VERSION ""

NS_ :

BS_:

BU_: UWB_RL UWB_FRNK UWB_RR UWB_INT DHR DHL UWB_BLE BDC UWB_FL Devtool ROA WPC UWB_TRNK UWB_FR

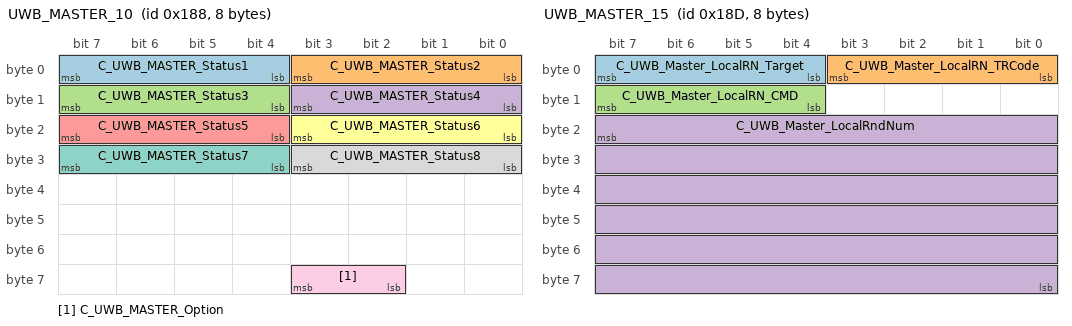
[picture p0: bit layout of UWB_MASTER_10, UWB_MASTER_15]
BO_ 392 UWB_MASTER_10: 8 UWB_BLE
 SG_ C_UWB_MASTER_Status1 : 7|4@0+ (1,0) [0|7] ""  BDC
 SG_ C_UWB_MASTER_Status2 : 3|4@0+ (1,0) [0|7] ""  BDC
 SG_ C_UWB_MASTER_Status3 : 15|4@0+ (1,0) [0|7] ""  BDC
 SG_ C_UWB_MASTER_Status4 : 11|4@0+ (1,0) [0|7] ""  BDC
 SG_ C_UWB_MASTER_Status5 : 23|4@0+ (1,0) [0|7] ""  BDC
 SG_ C_UWB_MASTER_Status6 : 19|4@0+ (1,0) [0|7] ""  BDC
 SG_ C_UWB_MASTER_Status7 : 31|4@0+ (1,0) [0|7] ""  BDC
 SG_ C_UWB_MASTER_Status8 : 27|4@0+ (1,0) [0|7] ""  BDC
 SG_ C_UWB_MASTER_Option : 59|2@0+ (1,0) [0|0] ""  BDC

BO_ 393 UWB_MASTER_11: 8 UWB_BLE
 SG_ C_UWB_Master_DK_ConnStat : 7|2@0+ (1,0) [0|0] ""  BDC
 SG_ C_UWB_Mst_DK_LocalizationStat : 5|2@0+ (1,0) [0|0] ""  BDC

BO_ 394 UWB_MASTER_12: 8 UWB_BLE
 SG_ C_UWB_Mst_EncryptedResult1Val : 7|64@0+ (1,0) [0|0] ""  BDC

BO_ 395 UWB_MASTER_13: 8 UWB_BLE
 SG_ C_UWB_Mst_EncryptedResult2Val : 7|64@0+ (1,0) [0|0] ""  BDC

BO_ 396 UWB_MASTER_14: 8 UWB_BLE
 SG_ C_UWB_Master2BDC_RndNum : 15|48@0+ (1,0) [0|0] ""  BDC

BO_ 397 UWB_MASTER_15: 8 UWB_BLE
 SG_ C_UWB_Master_LocalRN_Target : 7|4@0+ (1,0) [0|0] ""  UWB_FL,UWB_FR,UWB_FRNK,UWB_INT,UWB_RL,UWB_RR,UWB_TRNK
 SG_ C_UWB_Master_LocalRN_TRCode : 3|4@0+ (1,0) [0|0] ""  UWB_FL,UWB_FR,UWB_FRNK,UWB_INT,UWB_RL,UWB_RR,UWB_TRNK
 SG_ C_UWB_Master_LocalRN_CMD : 15|4@0+ (1,0) [0|0] ""  UWB_FL,UWB_FR,UWB_FRNK,UWB_INT,UWB_RL,UWB_RR,UWB_TRNK
 SG_ C_UWB_Master_LocalRndNum : 23|48@0+ (1,0) [0|0] ""  UWB_FL,UWB_FR,UWB_FRNK,UWB_INT,UWB_RL,UWB_RR,UWB_TRNK

BO_ 398 UWB_MASTER_16: 8 UWB_BLE
 SG_ UWB_Master_ToUWBEncryptData1 : 7|64@0+ (1,0) [0|0] ""  UWB_FL,UWB_FR,UWB_FRNK,UWB_INT,UWB_RL,UWB_RR,UWB_TRNK

BO_ 399 UWB_MASTER_17: 8 UWB_BLE
 SG_ UWB_Master_ToUWBEncryptData2 : 7|64@0+ (1,0) [0|0] ""  UWB_FL,UWB_FR,UWB_FRNK,UWB_INT,UWB_RL,UWB_RR,UWB_TRNK

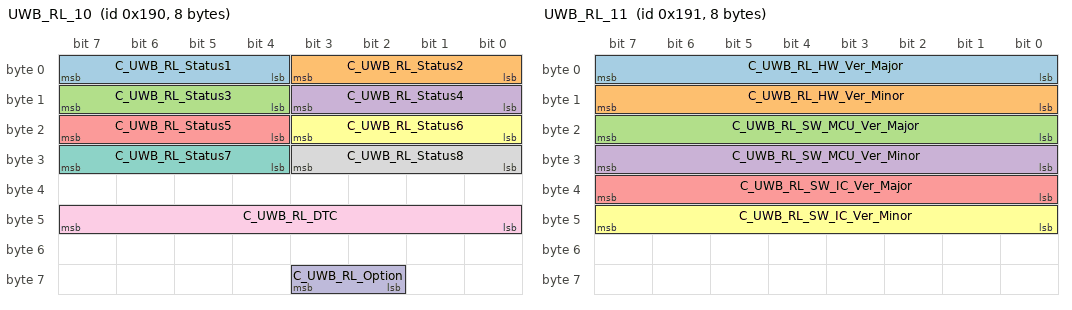
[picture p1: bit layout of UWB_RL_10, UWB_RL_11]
BO_ 400 UWB_RL_10: 8 UWB_RL
 SG_ C_UWB_RL_Status1 : 7|4@0+ (1,0) [0|7] ""  BDC,UWB_BLE
 SG_ C_UWB_RL_Status2 : 3|4@0+ (1,0) [0|7] ""  BDC,UWB_BLE
 SG_ C_UWB_RL_Status3 : 15|4@0+ (1,0) [0|7] ""  BDC,UWB_BLE
 SG_ C_UWB_RL_Status4 : 11|4@0+ (1,0) [0|7] ""  BDC,UWB_BLE
 SG_ C_UWB_RL_Status5 : 23|4@0+ (1,0) [0|7] ""  BDC,UWB_BLE
 SG_ C_UWB_RL_Status6 : 19|4@0+ (1,0) [0|7] ""  BDC,UWB_BLE
 SG_ C_UWB_RL_Status7 : 31|4@0+ (1,0) [0|7] ""  BDC,UWB_BLE
 SG_ C_UWB_RL_Status8 : 27|4@0+ (1,0) [0|7] ""  BDC,UWB_BLE
 SG_ C_UWB_RL_DTC : 47|8@0+ (1,0) [0|0] ""  UWB_BLE
 SG_ C_UWB_RL_Option : 59|2@0+ (1,0) [0|0] ""  BDC,UWB_BLE

BO_ 401 UWB_RL_11: 8 UWB_RL
 SG_ C_UWB_RL_HW_Ver_Major : 7|8@0+ (1,0) [0|7] ""  UWB_BLE
 SG_ C_UWB_RL_HW_Ver_Minor : 15|8@0+ (1,0) [0|7] ""  UWB_BLE
 SG_ C_UWB_RL_SW_MCU_Ver_Major : 23|8@0+ (1,0) [0|7] ""  UWB_BLE
 SG_ C_UWB_RL_SW_MCU_Ver_Minor : 31|8@0+ (1,0) [0|7] ""  UWB_BLE
 SG_ C_UWB_RL_SW_IC_Ver_Major : 39|8@0+ (1,0) [0|7] ""  UWB_BLE
 SG_ C_UWB_RL_SW_IC_Ver_Minor : 47|8@0+ (1,0) [0|7] ""  UWB_BLE

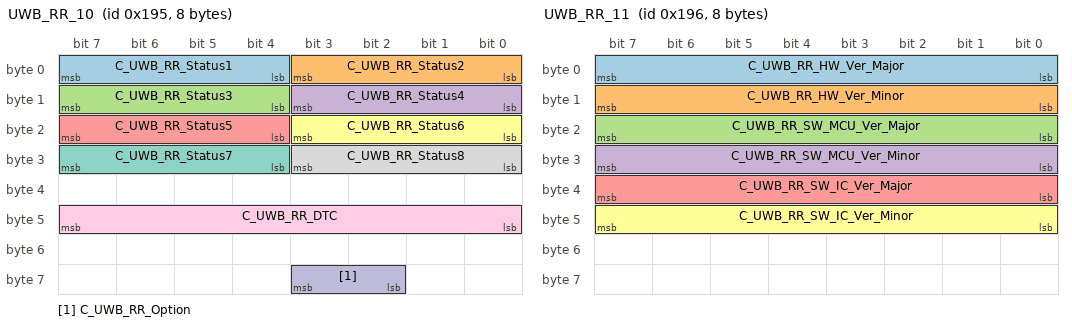
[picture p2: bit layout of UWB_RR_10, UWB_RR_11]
BO_ 405 UWB_RR_10: 8 UWB_RR
 SG_ C_UWB_RR_Status1 : 7|4@0+ (1,0) [0|7] ""  BDC,UWB_BLE
 SG_ C_UWB_RR_Status2 : 3|4@0+ (1,0) [0|7] ""  BDC,UWB_BLE
 SG_ C_UWB_RR_Status3 : 15|4@0+ (1,0) [0|7] ""  BDC,UWB_BLE
 SG_ C_UWB_RR_Status4 : 11|4@0+ (1,0) [0|7] ""  BDC,UWB_BLE
 SG_ C_UWB_RR_Status5 : 23|4@0+ (1,0) [0|7] ""  BDC,UWB_BLE
 SG_ C_UWB_RR_Status6 : 19|4@0+ (1,0) [0|7] ""  BDC,UWB_BLE
 SG_ C_UWB_RR_Status7 : 31|4@0+ (1,0) [0|7] ""  BDC,UWB_BLE
 SG_ C_UWB_RR_Status8 : 27|4@0+ (1,0) [0|7] ""  BDC,UWB_BLE
 SG_ C_UWB_RR_DTC : 47|8@0+ (1,0) [0|0] ""  UWB_BLE
 SG_ C_UWB_RR_Option : 59|2@0+ (1,0) [0|0] ""  BDC,UWB_BLE

BO_ 406 UWB_RR_11: 8 UWB_RR
 SG_ C_UWB_RR_HW_Ver_Major : 7|8@0+ (1,0) [0|7] ""  UWB_BLE
 SG_ C_UWB_RR_HW_Ver_Minor : 15|8@0+ (1,0) [0|7] ""  UWB_BLE
 SG_ C_UWB_RR_SW_MCU_Ver_Major : 23|8@0+ (1,0) [0|7] ""  UWB_BLE
 SG_ C_UWB_RR_SW_MCU_Ver_Minor : 31|8@0+ (1,0) [0|7] ""  UWB_BLE
 SG_ C_UWB_RR_SW_IC_Ver_Major : 39|8@0+ (1,0) [0|7] ""  UWB_BLE
 SG_ C_UWB_RR_SW_IC_Ver_Minor : 47|8@0+ (1,0) [0|7] ""  UWB_BLE

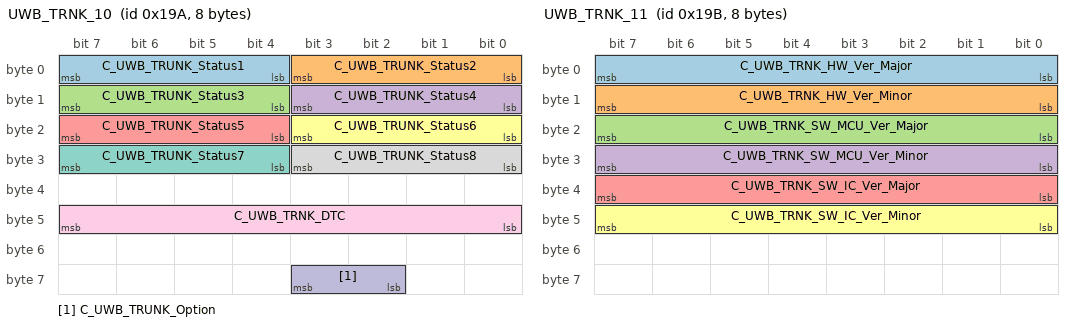
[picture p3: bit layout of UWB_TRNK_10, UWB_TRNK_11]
BO_ 410 UWB_TRNK_10: 8 UWB_TRNK
 SG_ C_UWB_TRUNK_Status1 : 7|4@0+ (1,0) [0|7] ""  BDC,UWB_BLE
 SG_ C_UWB_TRUNK_Status2 : 3|4@0+ (1,0) [0|7] ""  BDC,UWB_BLE
 SG_ C_UWB_TRUNK_Status3 : 15|4@0+ (1,0) [0|7] ""  BDC,UWB_BLE
 SG_ C_UWB_TRUNK_Status4 : 11|4@0+ (1,0) [0|7] ""  BDC,UWB_BLE
 SG_ C_UWB_TRUNK_Status5 : 23|4@0+ (1,0) [0|7] ""  BDC,UWB_BLE
 SG_ C_UWB_TRUNK_Status6 : 19|4@0+ (1,0) [0|7] ""  BDC,UWB_BLE
 SG_ C_UWB_TRUNK_Status7 : 31|4@0+ (1,0) [0|7] ""  BDC,UWB_BLE
 SG_ C_UWB_TRUNK_Status8 : 27|4@0+ (1,0) [0|7] ""  BDC,UWB_BLE
 SG_ C_UWB_TRNK_DTC : 47|8@0+ (1,0) [0|0] ""  UWB_BLE
 SG_ C_UWB_TRUNK_Option : 59|2@0+ (1,0) [0|3] ""  BDC,UWB_BLE

BO_ 411 UWB_TRNK_11: 8 UWB_TRNK
 SG_ C_UWB_TRNK_HW_Ver_Major : 7|8@0+ (1,0) [0|7] ""  UWB_BLE
 SG_ C_UWB_TRNK_HW_Ver_Minor : 15|8@0+ (1,0) [0|7] ""  UWB_BLE
 SG_ C_UWB_TRNK_SW_MCU_Ver_Major : 23|8@0+ (1,0) [0|7] ""  UWB_BLE
 SG_ C_UWB_TRNK_SW_MCU_Ver_Minor : 31|8@0+ (1,0) [0|7] ""  UWB_BLE
 SG_ C_UWB_TRNK_SW_IC_Ver_Major : 39|8@0+ (1,0) [0|7] ""  UWB_BLE
 SG_ C_UWB_TRNK_SW_IC_Ver_Minor : 47|8@0+ (1,0) [0|7] ""  UWB_BLE

BO_ 418 UWB_INT_02: 8 UWB_INT
 SG_ C_UWB_INT_To_MasterEncData1 : 7|64@0+ (1,0) [0|0] ""  UWB_BLE

BO_ 450 UWB_RL_02: 8 UWB_RL
 SG_ C_UWB_RL_To_MasterEncData1 : 7|64@0+ (1,0) [0|0] ""  UWB_BLE

BO_ 451 UWB_RL_03: 8 UWB_RL
 SG_ C_UWB_RL_To_MasterEncData2 : 7|64@0+ (1,0) [0|0] ""  UWB_BLE

BO_ 452 UWB_RL_04: 8 UWB_RL
 SG_ C_UWB_RL_To_BDCFOBRSDResult : 7|64@0+ (1,0) [0|0] ""  BDC

BO_ 453 UWB_RL_05: 8 UWB_RL
 SG_ C_UWB_RL_MCU_Bootloader : 7|8@0+ (1,0) [0|0] ""  UWB_BLE
 SG_ C_UWB_RL_MCU_Flash_Erase : 15|8@0+ (1,0) [0|0] ""  UWB_BLE
 SG_ C_UWB_RL_MCU_CRC32 : 23|8@0+ (1,0) [0|0] ""  UWB_BLE

BO_ 454 UWB_RL_06: 8 UWB_RL
 SG_ C_UWB_RL_IC_Bootloader : 7|8@0+ (1,0) [0|0] ""  UWB_BLE
 SG_ C_UWB_RL_IC_Flash_Erase : 15|8@0+ (1,0) [0|0] ""  UWB_BLE
 SG_ C_UWB_RL_IC_CRC32 : 23|8@0+ (1,0) [0|0] ""  UWB_BLE

BO_ 455 UWB_RL_01: 8 UWB_RL
 SG_ C_UWB_RL_Decrypt_FB : 63|4@0+ (1,0) [0|0] ""  BDC,UWB_BLE

BO_ 482 UWB_RR_02: 8 UWB_RR
 SG_ C_UWB_RR_To_MasterEncData1 : 7|64@0+ (1,0) [0|0] ""  UWB_BLE

BO_ 483 UWB_RR_03: 8 UWB_RR
 SG_ C_UWB_RR_To_MasterEncData2 : 7|64@0+ (1,0) [0|0] ""  UWB_BLE

BO_ 484 UWB_RR_04: 8 UWB_RR
 SG_ C_UWB_RR_To_BDCFOBRSDResult : 7|64@0+ (1,0) [0|0] ""  BDC

BO_ 485 UWB_RR_05: 8 UWB_RR
 SG_ C_UWB_RR_MCU_Bootloader : 7|8@0+ (1,0) [0|0] ""  UWB_BLE
 SG_ C_UWB_RR_MCU_Flash_Erase : 15|8@0+ (1,0) [0|0] ""  UWB_BLE
 SG_ C_UWB_RR_MCU_CRC32 : 23|8@0+ (1,0) [0|0] ""  UWB_BLE

BO_ 486 UWB_RR_06: 8 UWB_RR
 SG_ C_UWB_RR_IC_Bootloader : 7|8@0+ (1,0) [0|0] ""  UWB_BLE
 SG_ C_UWB_RR_IC_Flash_Erase : 15|8@0+ (1,0) [0|0] ""  UWB_BLE
 SG_ C_UWB_RR_IC_CRC32 : 23|8@0+ (1,0) [0|0] ""  UWB_BLE

BO_ 487 UWB_RR_01: 8 UWB_RR
 SG_ C_UWB_RR_Decrypt_FB : 63|4@0+ (1,0) [0|0] ""  BDC,UWB_BLE

BO_ 498 UWB_TRNK_02: 8 UWB_TRNK
 SG_ C_UWB_TRNK_To_MasterEncData1 : 7|64@0+ (1,0) [0|0] ""  UWB_BLE

BO_ 499 UWB_TRNK_03: 8 UWB_TRNK
 SG_ C_UWB_TRNK_To_MasterEncData2 : 7|64@0+ (1,0) [0|0] ""  UWB_BLE

BO_ 500 UWB_TRNK_04: 8 UWB_TRNK
 SG_ C_UWB_TRNK_To_BDCFOBRSDResult : 7|64@0+ (1,0) [0|0] ""  BDC

BO_ 501 UWB_TRNK_05: 8 UWB_TRNK
 SG_ C_UWB_TRNK_MCU_Bootloader : 7|8@0+ (1,0) [0|0] ""  UWB_BLE
 SG_ C_UWB_TRNK_MCU_Flash_Erase : 15|8@0+ (1,0) [0|0] ""  UWB_BLE
 SG_ C_UWB_TRNK_MCU_CRC32 : 23|8@0+ (1,0) [0|0] ""  UWB_BLE

BO_ 502 UWB_TRNK_06: 8 UWB_TRNK
 SG_ C_UWB_TRNK_IC_Bootloader : 7|8@0+ (1,0) [0|0] ""  UWB_BLE
 SG_ C_UWB_TRNK_IC_Flash_Erase : 15|8@0+ (1,0) [0|0] ""  UWB_BLE
 SG_ C_UWB_TRNK_IC_CRC32 : 23|8@0+ (1,0) [0|0] ""  UWB_BLE

BO_ 503 UWB_TRNK_01: 8 UWB_TRNK
 SG_ C_UWB_TRNK_Decrypt_FB : 63|4@0+ (1,0) [0|0] ""  BDC,UWB_BLE

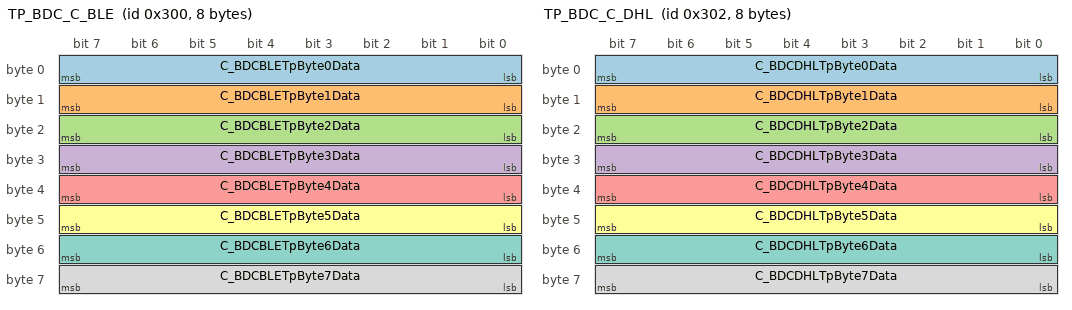
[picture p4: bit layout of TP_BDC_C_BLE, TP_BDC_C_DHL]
BO_ 768 TP_BDC_C_BLE: 8 BDC
 SG_ C_BDCBLETpByte0Data : 7|8@0+ (1,0) [0|0] ""  UWB_BLE
 SG_ C_BDCBLETpByte1Data : 15|8@0+ (1,0) [0|0] ""  UWB_BLE
 SG_ C_BDCBLETpByte2Data : 23|8@0+ (1,0) [0|0] ""  UWB_BLE
 SG_ C_BDCBLETpByte3Data : 31|8@0+ (1,0) [0|0] ""  UWB_BLE
 SG_ C_BDCBLETpByte4Data : 39|8@0+ (1,0) [0|0] ""  UWB_BLE
 SG_ C_BDCBLETpByte5Data : 47|8@0+ (1,0) [0|0] ""  UWB_BLE
 SG_ C_BDCBLETpByte6Data : 55|8@0+ (1,0) [0|0] ""  UWB_BLE
 SG_ C_BDCBLETpByte7Data : 63|8@0+ (1,0) [0|0] ""  UWB_BLE

BO_ 770 TP_BDC_C_DHL: 8 BDC
 SG_ C_BDCDHLTpByte0Data : 7|8@0+ (1,0) [0|0] ""  DHL
 SG_ C_BDCDHLTpByte1Data : 15|8@0+ (1,0) [0|0] ""  DHL
 SG_ C_BDCDHLTpByte2Data : 23|8@0+ (1,0) [0|0] ""  DHL
 SG_ C_BDCDHLTpByte3Data : 31|8@0+ (1,0) [0|0] ""  DHL
 SG_ C_BDCDHLTpByte4Data : 39|8@0+ (1,0) [0|0] ""  DHL
 SG_ C_BDCDHLTpByte5Data : 47|8@0+ (1,0) [0|0] ""  DHL
 SG_ C_BDCDHLTpByte6Data : 55|8@0+ (1,0) [0|0] ""  DHL
 SG_ C_BDCDHLTpByte7Data : 63|8@0+ (1,0) [0|0] ""  DHL

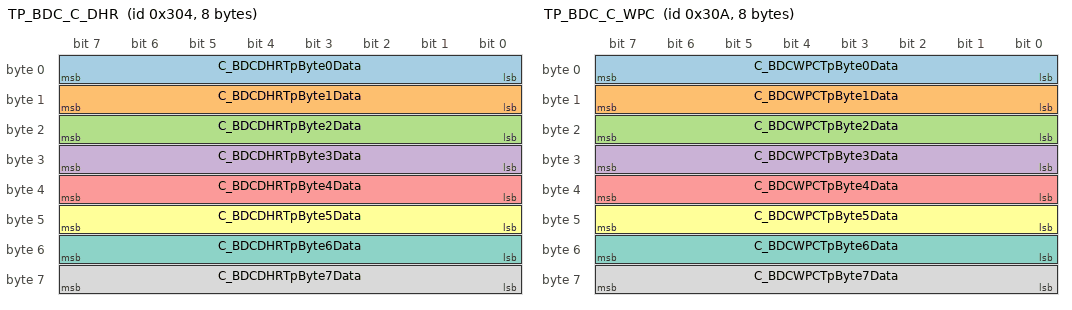
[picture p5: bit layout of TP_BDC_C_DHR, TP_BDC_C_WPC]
BO_ 772 TP_BDC_C_DHR: 8 BDC
 SG_ C_BDCDHRTpByte0Data : 7|8@0+ (1,0) [0|0] ""  DHR
 SG_ C_BDCDHRTpByte1Data : 15|8@0+ (1,0) [0|0] ""  DHR
 SG_ C_BDCDHRTpByte2Data : 23|8@0+ (1,0) [0|0] ""  DHR
 SG_ C_BDCDHRTpByte3Data : 31|8@0+ (1,0) [0|0] ""  DHR
 SG_ C_BDCDHRTpByte4Data : 39|8@0+ (1,0) [0|0] ""  DHR
 SG_ C_BDCDHRTpByte5Data : 47|8@0+ (1,0) [0|0] ""  DHR
 SG_ C_BDCDHRTpByte6Data : 55|8@0+ (1,0) [0|0] ""  DHR
 SG_ C_BDCDHRTpByte7Data : 63|8@0+ (1,0) [0|0] ""  DHR

BO_ 778 TP_BDC_C_WPC: 8 BDC
 SG_ C_BDCWPCTpByte0Data : 7|8@0+ (1,0) [0|0] ""  WPC
 SG_ C_BDCWPCTpByte1Data : 15|8@0+ (1,0) [0|0] ""  WPC
 SG_ C_BDCWPCTpByte2Data : 23|8@0+ (1,0) [0|0] ""  WPC
 SG_ C_BDCWPCTpByte3Data : 31|8@0+ (1,0) [0|0] ""  WPC
 SG_ C_BDCWPCTpByte4Data : 39|8@0+ (1,0) [0|0] ""  WPC
 SG_ C_BDCWPCTpByte5Data : 47|8@0+ (1,0) [0|0] ""  WPC
 SG_ C_BDCWPCTpByte6Data : 55|8@0+ (1,0) [0|0] ""  WPC
 SG_ C_BDCWPCTpByte7Data : 63|8@0+ (1,0) [0|0] ""  WPC

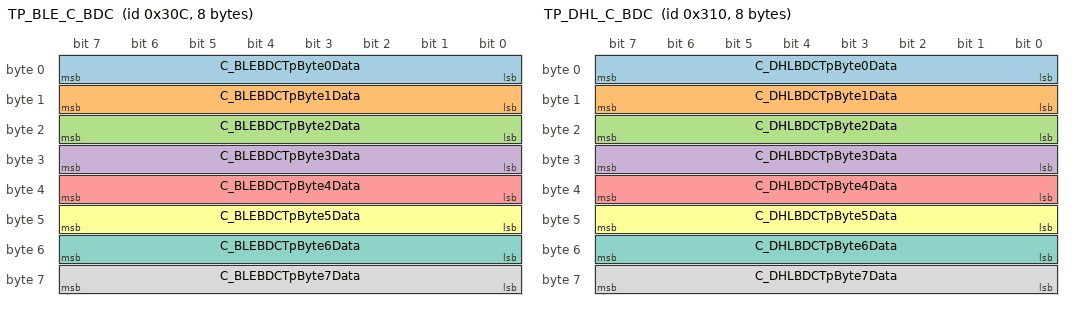
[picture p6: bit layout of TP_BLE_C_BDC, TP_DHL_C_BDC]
BO_ 780 TP_BLE_C_BDC: 8 UWB_BLE
 SG_ C_BLEBDCTpByte0Data : 7|8@0+ (1,0) [0|0] ""  BDC
 SG_ C_BLEBDCTpByte1Data : 15|8@0+ (1,0) [0|0] ""  BDC
 SG_ C_BLEBDCTpByte2Data : 23|8@0+ (1,0) [0|0] ""  BDC
 SG_ C_BLEBDCTpByte3Data : 31|8@0+ (1,0) [0|0] ""  BDC
 SG_ C_BLEBDCTpByte4Data : 39|8@0+ (1,0) [0|0] ""  BDC
 SG_ C_BLEBDCTpByte5Data : 47|8@0+ (1,0) [0|0] ""  BDC
 SG_ C_BLEBDCTpByte6Data : 55|8@0+ (1,0) [0|0] ""  BDC
 SG_ C_BLEBDCTpByte7Data : 63|8@0+ (1,0) [0|0] ""  BDC

BO_ 784 TP_DHL_C_BDC: 8 DHL
 SG_ C_DHLBDCTpByte0Data : 7|8@0+ (1,0) [0|0] ""  BDC
 SG_ C_DHLBDCTpByte1Data : 15|8@0+ (1,0) [0|0] ""  BDC
 SG_ C_DHLBDCTpByte2Data : 23|8@0+ (1,0) [0|0] ""  BDC
 SG_ C_DHLBDCTpByte3Data : 31|8@0+ (1,0) [0|0] ""  BDC
 SG_ C_DHLBDCTpByte4Data : 39|8@0+ (1,0) [0|0] ""  BDC
 SG_ C_DHLBDCTpByte5Data : 47|8@0+ (1,0) [0|0] ""  BDC
 SG_ C_DHLBDCTpByte6Data : 55|8@0+ (1,0) [0|0] ""  BDC
 SG_ C_DHLBDCTpByte7Data : 63|8@0+ (1,0) [0|0] ""  BDC

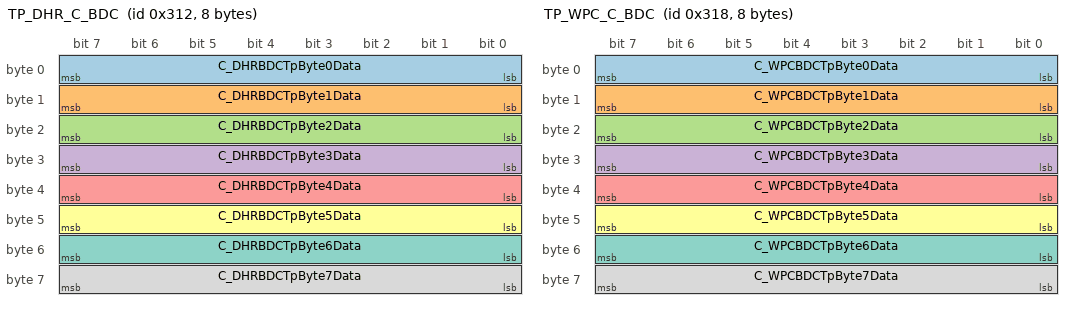
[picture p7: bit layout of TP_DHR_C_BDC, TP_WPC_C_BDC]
BO_ 786 TP_DHR_C_BDC: 8 DHR
 SG_ C_DHRBDCTpByte0Data : 7|8@0+ (1,0) [0|0] ""  BDC
 SG_ C_DHRBDCTpByte1Data : 15|8@0+ (1,0) [0|0] ""  BDC
 SG_ C_DHRBDCTpByte2Data : 23|8@0+ (1,0) [0|0] ""  BDC
 SG_ C_DHRBDCTpByte3Data : 31|8@0+ (1,0) [0|0] ""  BDC
 SG_ C_DHRBDCTpByte4Data : 39|8@0+ (1,0) [0|0] ""  BDC
 SG_ C_DHRBDCTpByte5Data : 47|8@0+ (1,0) [0|0] ""  BDC
 SG_ C_DHRBDCTpByte6Data : 55|8@0+ (1,0) [0|0] ""  BDC
 SG_ C_DHRBDCTpByte7Data : 63|8@0+ (1,0) [0|0] ""  BDC

BO_ 792 TP_WPC_C_BDC: 8 WPC
 SG_ C_WPCBDCTpByte0Data : 7|8@0+ (1,0) [0|0] ""  BDC,Devtool
 SG_ C_WPCBDCTpByte1Data : 15|8@0+ (1,0) [0|0] ""  BDC,Devtool
 SG_ C_WPCBDCTpByte2Data : 23|8@0+ (1,0) [0|0] ""  BDC,Devtool
 SG_ C_WPCBDCTpByte3Data : 31|8@0+ (1,0) [0|0] ""  BDC,Devtool
 SG_ C_WPCBDCTpByte4Data : 39|8@0+ (1,0) [0|0] ""  BDC,Devtool
 SG_ C_WPCBDCTpByte5Data : 47|8@0+ (1,0) [0|0] ""  BDC,Devtool
 SG_ C_WPCBDCTpByte6Data : 55|8@0+ (1,0) [0|0] ""  BDC,Devtool
 SG_ C_WPCBDCTpByte7Data : 63|8@0+ (1,0) [0|0] ""  BDC,Devtool

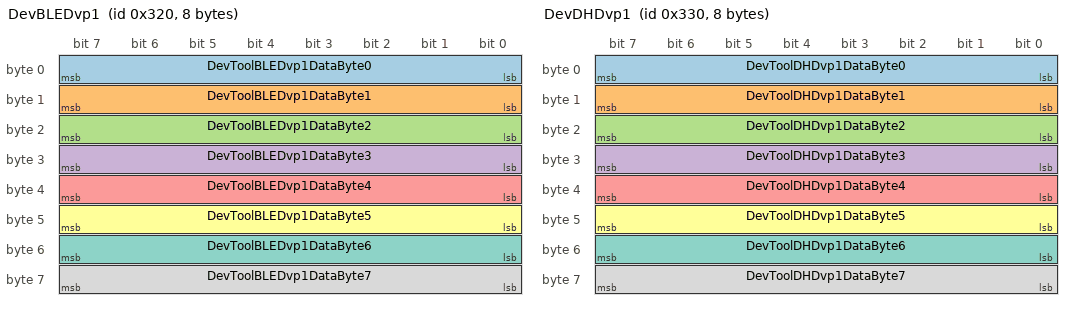
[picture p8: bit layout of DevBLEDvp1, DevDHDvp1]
BO_ 800 DevBLEDvp1: 8 Devtool
 SG_ DevToolBLEDvp1DataByte0 : 7|8@0+ (1,0) [0|0] ""  UWB_BLE
 SG_ DevToolBLEDvp1DataByte1 : 15|8@0+ (1,0) [0|0] ""  UWB_BLE
 SG_ DevToolBLEDvp1DataByte2 : 23|8@0+ (1,0) [0|0] ""  UWB_BLE
 SG_ DevToolBLEDvp1DataByte3 : 31|8@0+ (1,0) [0|0] ""  UWB_BLE
 SG_ DevToolBLEDvp1DataByte4 : 39|8@0+ (1,0) [0|0] ""  UWB_BLE
 SG_ DevToolBLEDvp1DataByte5 : 47|8@0+ (1,0) [0|0] ""  UWB_BLE
 SG_ DevToolBLEDvp1DataByte6 : 55|8@0+ (1,0) [0|0] ""  UWB_BLE
 SG_ DevToolBLEDvp1DataByte7 : 63|8@0+ (1,0) [0|0] ""  UWB_BLE

BO_ 816 DevDHDvp1: 8 Devtool
 SG_ DevToolDHDvp1DataByte0 : 7|8@0+ (1,0) [0|0] ""  DHL,DHR
 SG_ DevToolDHDvp1DataByte1 : 15|8@0+ (1,0) [0|0] ""  DHL,DHR
 SG_ DevToolDHDvp1DataByte2 : 23|8@0+ (1,0) [0|0] ""  DHL,DHR
 SG_ DevToolDHDvp1DataByte3 : 31|8@0+ (1,0) [0|0] ""  DHL,DHR
 SG_ DevToolDHDvp1DataByte4 : 39|8@0+ (1,0) [0|0] ""  DHL,DHR
 SG_ DevToolDHDvp1DataByte5 : 47|8@0+ (1,0) [0|0] ""  DHL,DHR
 SG_ DevToolDHDvp1DataByte6 : 55|8@0+ (1,0) [0|0] ""  DHL,DHR
 SG_ DevToolDHDvp1DataByte7 : 63|8@0+ (1,0) [0|0] ""  DHL,DHR

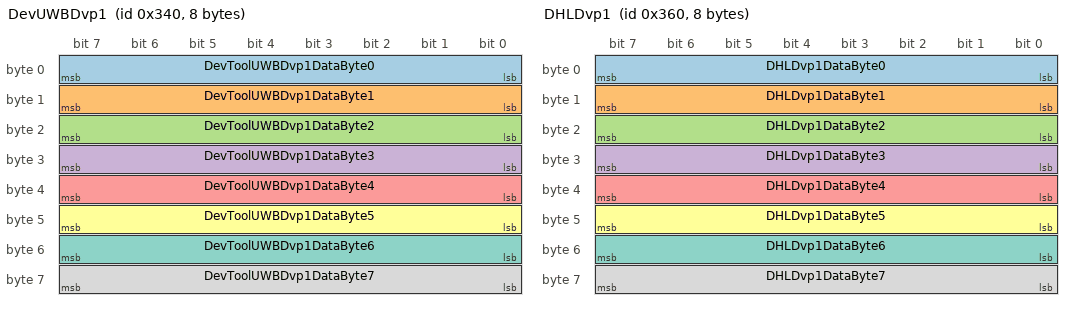
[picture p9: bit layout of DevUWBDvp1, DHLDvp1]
BO_ 832 DevUWBDvp1: 8 Devtool
 SG_ DevToolUWBDvp1DataByte0 : 7|8@0+ (1,0) [0|0] ""  UWB_BLE,UWB_FL,UWB_FR,UWB_FRNK,UWB_INT,UWB_RL,UWB_RR,UWB_TRNK
 SG_ DevToolUWBDvp1DataByte1 : 15|8@0+ (1,0) [0|0] ""  UWB_BLE,UWB_FL,UWB_FR,UWB_FRNK,UWB_INT,UWB_RL,UWB_RR,UWB_TRNK
 SG_ DevToolUWBDvp1DataByte2 : 23|8@0+ (1,0) [0|0] ""  UWB_BLE,UWB_FL,UWB_FR,UWB_FRNK,UWB_INT,UWB_RL,UWB_RR,UWB_TRNK
 SG_ DevToolUWBDvp1DataByte3 : 31|8@0+ (1,0) [0|0] ""  UWB_BLE,UWB_FL,UWB_FR,UWB_FRNK,UWB_INT,UWB_RL,UWB_RR,UWB_TRNK
 SG_ DevToolUWBDvp1DataByte4 : 39|8@0+ (1,0) [0|0] ""  UWB_BLE,UWB_FL,UWB_FR,UWB_FRNK,UWB_INT,UWB_RL,UWB_RR,UWB_TRNK
 SG_ DevToolUWBDvp1DataByte5 : 47|8@0+ (1,0) [0|0] ""  UWB_BLE,UWB_FL,UWB_FR,UWB_FRNK,UWB_INT,UWB_RL,UWB_RR,UWB_TRNK
 SG_ DevToolUWBDvp1DataByte6 : 55|8@0+ (1,0) [0|0] ""  UWB_BLE,UWB_FL,UWB_FR,UWB_FRNK,UWB_INT,UWB_RL,UWB_RR,UWB_TRNK
 SG_ DevToolUWBDvp1DataByte7 : 63|8@0+ (1,0) [0|0] ""  UWB_BLE,UWB_FL,UWB_FR,UWB_FRNK,UWB_INT,UWB_RL,UWB_RR,UWB_TRNK

BO_ 864 DHLDvp1: 8 DHL
 SG_ DHLDvp1DataByte0 : 7|8@0+ (1,0) [0|0] ""  Devtool
 SG_ DHLDvp1DataByte1 : 15|8@0+ (1,0) [0|0] ""  Devtool
 SG_ DHLDvp1DataByte2 : 23|8@0+ (1,0) [0|0] ""  Devtool
 SG_ DHLDvp1DataByte3 : 31|8@0+ (1,0) [0|0] ""  Devtool
 SG_ DHLDvp1DataByte4 : 39|8@0+ (1,0) [0|0] ""  Devtool
 SG_ DHLDvp1DataByte5 : 47|8@0+ (1,0) [0|0] ""  Devtool
 SG_ DHLDvp1DataByte6 : 55|8@0+ (1,0) [0|0] ""  Devtool
 SG_ DHLDvp1DataByte7 : 63|8@0+ (1,0) [0|0] ""  Devtool

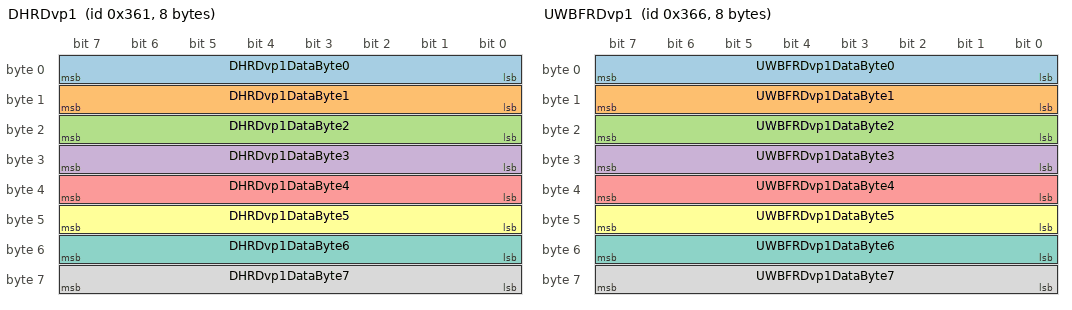
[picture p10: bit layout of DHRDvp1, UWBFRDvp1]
BO_ 865 DHRDvp1: 8 DHR
 SG_ DHRDvp1DataByte0 : 7|8@0+ (1,0) [0|0] ""  Devtool
 SG_ DHRDvp1DataByte1 : 15|8@0+ (1,0) [0|0] ""  Devtool
 SG_ DHRDvp1DataByte2 : 23|8@0+ (1,0) [0|0] ""  Devtool
 SG_ DHRDvp1DataByte3 : 31|8@0+ (1,0) [0|0] ""  Devtool
 SG_ DHRDvp1DataByte4 : 39|8@0+ (1,0) [0|0] ""  Devtool
 SG_ DHRDvp1DataByte5 : 47|8@0+ (1,0) [0|0] ""  Devtool
 SG_ DHRDvp1DataByte6 : 55|8@0+ (1,0) [0|0] ""  Devtool
 SG_ DHRDvp1DataByte7 : 63|8@0+ (1,0) [0|0] ""  Devtool

BO_ 870 UWBFRDvp1: 8 UWB_FR
 SG_ UWBFRDvp1DataByte0 : 7|8@0+ (1,0) [0|0] ""  Devtool
 SG_ UWBFRDvp1DataByte1 : 15|8@0+ (1,0) [0|0] ""  Devtool
 SG_ UWBFRDvp1DataByte2 : 23|8@0+ (1,0) [0|0] ""  Devtool
 SG_ UWBFRDvp1DataByte3 : 31|8@0+ (1,0) [0|0] ""  Devtool
 SG_ UWBFRDvp1DataByte4 : 39|8@0+ (1,0) [0|0] ""  Devtool
 SG_ UWBFRDvp1DataByte5 : 47|8@0+ (1,0) [0|0] ""  Devtool
 SG_ UWBFRDvp1DataByte6 : 55|8@0+ (1,0) [0|0] ""  Devtool
 SG_ UWBFRDvp1DataByte7 : 63|8@0+ (1,0) [0|0] ""  Devtool

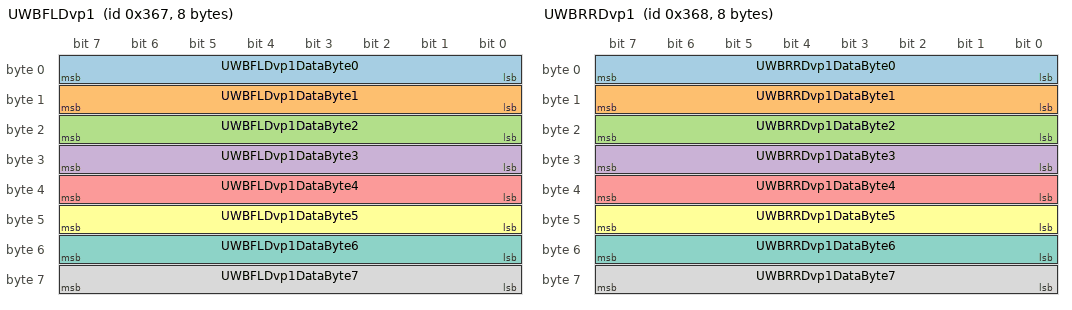
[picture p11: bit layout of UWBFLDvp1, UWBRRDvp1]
BO_ 871 UWBFLDvp1: 8 UWB_FL
 SG_ UWBFLDvp1DataByte0 : 7|8@0+ (1,0) [0|0] ""  Devtool
 SG_ UWBFLDvp1DataByte1 : 15|8@0+ (1,0) [0|0] ""  Devtool
 SG_ UWBFLDvp1DataByte2 : 23|8@0+ (1,0) [0|0] ""  Devtool
 SG_ UWBFLDvp1DataByte3 : 31|8@0+ (1,0) [0|0] ""  Devtool
 SG_ UWBFLDvp1DataByte4 : 39|8@0+ (1,0) [0|0] ""  Devtool
 SG_ UWBFLDvp1DataByte5 : 47|8@0+ (1,0) [0|0] ""  Devtool
 SG_ UWBFLDvp1DataByte6 : 55|8@0+ (1,0) [0|0] ""  Devtool
 SG_ UWBFLDvp1DataByte7 : 63|8@0+ (1,0) [0|0] ""  Devtool

BO_ 872 UWBRRDvp1: 8 UWB_RR
 SG_ UWBRRDvp1DataByte0 : 7|8@0+ (1,0) [0|0] ""  Devtool
 SG_ UWBRRDvp1DataByte1 : 15|8@0+ (1,0) [0|0] ""  Devtool
 SG_ UWBRRDvp1DataByte2 : 23|8@0+ (1,0) [0|0] ""  Devtool
 SG_ UWBRRDvp1DataByte3 : 31|8@0+ (1,0) [0|0] ""  Devtool
 SG_ UWBRRDvp1DataByte4 : 39|8@0+ (1,0) [0|0] ""  Devtool
 SG_ UWBRRDvp1DataByte5 : 47|8@0+ (1,0) [0|0] ""  Devtool
 SG_ UWBRRDvp1DataByte6 : 55|8@0+ (1,0) [0|0] ""  Devtool
 SG_ UWBRRDvp1DataByte7 : 63|8@0+ (1,0) [0|0] ""  Devtool

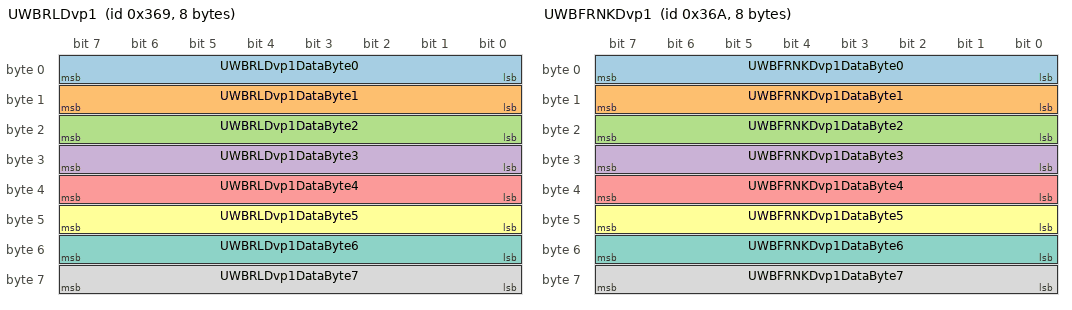
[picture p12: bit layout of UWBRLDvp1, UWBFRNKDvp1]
BO_ 873 UWBRLDvp1: 8 UWB_RL
 SG_ UWBRLDvp1DataByte0 : 7|8@0+ (1,0) [0|0] ""  Devtool
 SG_ UWBRLDvp1DataByte1 : 15|8@0+ (1,0) [0|0] ""  Devtool
 SG_ UWBRLDvp1DataByte2 : 23|8@0+ (1,0) [0|0] ""  Devtool
 SG_ UWBRLDvp1DataByte3 : 31|8@0+ (1,0) [0|0] ""  Devtool
 SG_ UWBRLDvp1DataByte4 : 39|8@0+ (1,0) [0|0] ""  Devtool
 SG_ UWBRLDvp1DataByte5 : 47|8@0+ (1,0) [0|0] ""  Devtool
 SG_ UWBRLDvp1DataByte6 : 55|8@0+ (1,0) [0|0] ""  Devtool
 SG_ UWBRLDvp1DataByte7 : 63|8@0+ (1,0) [0|0] ""  Devtool

BO_ 874 UWBFRNKDvp1: 8 UWB_FRNK
 SG_ UWBFRNKDvp1DataByte0 : 7|8@0+ (1,0) [0|0] ""  Devtool
 SG_ UWBFRNKDvp1DataByte1 : 15|8@0+ (1,0) [0|0] ""  Devtool
 SG_ UWBFRNKDvp1DataByte2 : 23|8@0+ (1,0) [0|0] ""  Devtool
 SG_ UWBFRNKDvp1DataByte3 : 31|8@0+ (1,0) [0|0] ""  Devtool
 SG_ UWBFRNKDvp1DataByte4 : 39|8@0+ (1,0) [0|0] ""  Devtool
 SG_ UWBFRNKDvp1DataByte5 : 47|8@0+ (1,0) [0|0] ""  Devtool
 SG_ UWBFRNKDvp1DataByte6 : 55|8@0+ (1,0) [0|0] ""  Devtool
 SG_ UWBFRNKDvp1DataByte7 : 63|8@0+ (1,0) [0|0] ""  Devtool

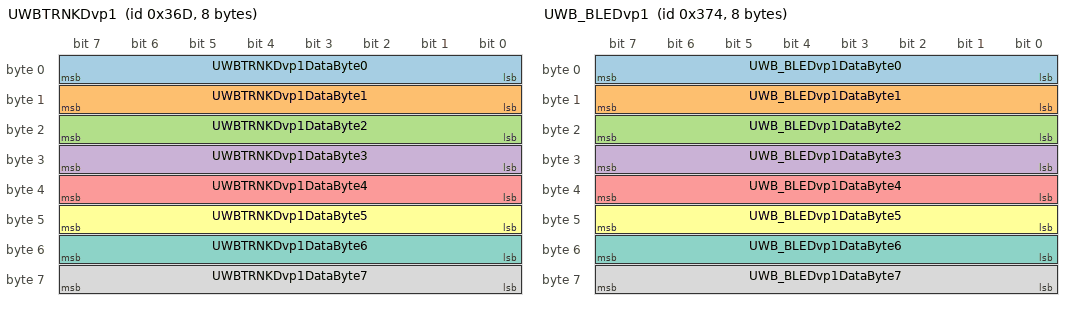
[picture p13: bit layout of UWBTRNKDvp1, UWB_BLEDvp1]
BO_ 877 UWBTRNKDvp1: 8 UWB_TRNK
 SG_ UWBTRNKDvp1DataByte0 : 7|8@0+ (1,0) [0|0] ""  Devtool
 SG_ UWBTRNKDvp1DataByte1 : 15|8@0+ (1,0) [0|0] ""  Devtool
 SG_ UWBTRNKDvp1DataByte2 : 23|8@0+ (1,0) [0|0] ""  Devtool
 SG_ UWBTRNKDvp1DataByte3 : 31|8@0+ (1,0) [0|0] ""  Devtool
 SG_ UWBTRNKDvp1DataByte4 : 39|8@0+ (1,0) [0|0] ""  Devtool
 SG_ UWBTRNKDvp1DataByte5 : 47|8@0+ (1,0) [0|0] ""  Devtool
 SG_ UWBTRNKDvp1DataByte6 : 55|8@0+ (1,0) [0|0] ""  Devtool
 SG_ UWBTRNKDvp1DataByte7 : 63|8@0+ (1,0) [0|0] ""  Devtool

BO_ 884 UWB_BLEDvp1: 8 UWB_BLE
 SG_ UWB_BLEDvp1DataByte0 : 7|8@0+ (1,0) [0|0] ""  Devtool
 SG_ UWB_BLEDvp1DataByte1 : 15|8@0+ (1,0) [0|0] ""  Devtool
 SG_ UWB_BLEDvp1DataByte2 : 23|8@0+ (1,0) [0|0] ""  Devtool
 SG_ UWB_BLEDvp1DataByte3 : 31|8@0+ (1,0) [0|0] ""  Devtool
 SG_ UWB_BLEDvp1DataByte4 : 39|8@0+ (1,0) [0|0] ""  Devtool
 SG_ UWB_BLEDvp1DataByte5 : 47|8@0+ (1,0) [0|0] ""  Devtool
 SG_ UWB_BLEDvp1DataByte6 : 55|8@0+ (1,0) [0|0] ""  Devtool
 SG_ UWB_BLEDvp1DataByte7 : 63|8@0+ (1,0) [0|0] ""  Devtool

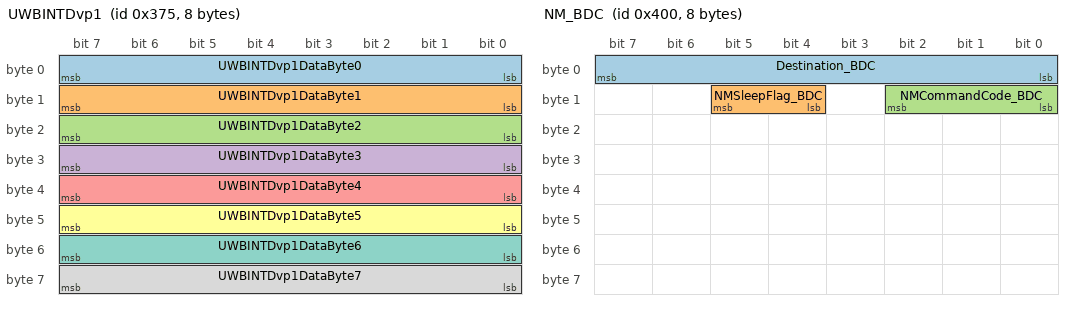
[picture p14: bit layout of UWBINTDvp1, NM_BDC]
BO_ 885 UWBINTDvp1: 8 UWB_INT
 SG_ UWBINTDvp1DataByte0 : 7|8@0+ (1,0) [0|0] ""  Devtool
 SG_ UWBINTDvp1DataByte1 : 15|8@0+ (1,0) [0|0] ""  Devtool
 SG_ UWBINTDvp1DataByte2 : 23|8@0+ (1,0) [0|0] ""  Devtool
 SG_ UWBINTDvp1DataByte3 : 31|8@0+ (1,0) [0|0] ""  Devtool
 SG_ UWBINTDvp1DataByte4 : 39|8@0+ (1,0) [0|0] ""  Devtool
 SG_ UWBINTDvp1DataByte5 : 47|8@0+ (1,0) [0|0] ""  Devtool
 SG_ UWBINTDvp1DataByte6 : 55|8@0+ (1,0) [0|0] ""  Devtool
 SG_ UWBINTDvp1DataByte7 : 63|8@0+ (1,0) [0|0] ""  Devtool

BO_ 888 UWB_BLEDvp2: 8 UWB_BLE
 SG_ UWB_BLE_Dvp2Data : 7|64@0+ (1,0) [0|0] ""  Devtool

BO_ 889 UWB_BLEDvp3: 8 UWB_BLE
 SG_ UWB_BLE_Dvp3Data : 7|64@0+ (1,0) [0|0] ""  Devtool

BO_ 896 UWB_BLEDvp4: 8 UWB_BLE
 SG_ UWB_BLE_Dvp4Data : 7|64@0+ (1,0) [0|0] ""  Devtool

BO_ 1024 NM_BDC: 8 BDC
 SG_ Destination_BDC : 7|8@0+ (1,0) [0|0] ""  UWB_RL,UWB_FRNK,UWB_RR,UWB_INT,DHR,DHL,UWB_BLE,UWB_FL,Devtool,ROA,WPC,UWB_TRNK,UWB_FR
 SG_ NMSleepFlag_BDC : 13|2@0+ (1,0) [0|0] ""  UWB_RL,UWB_FRNK,UWB_RR,UWB_INT,DHR,DHL,UWB_BLE,UWB_FL,Devtool,ROA,WPC,UWB_TRNK,UWB_FR
 SG_ NMCommandCode_BDC : 10|3@0+ (1,0) [0|0] ""  UWB_RL,UWB_FRNK,UWB_RR,UWB_INT,DHR,DHL,UWB_BLE,UWB_FL,Devtool,ROA,WPC,UWB_TRNK,UWB_FR

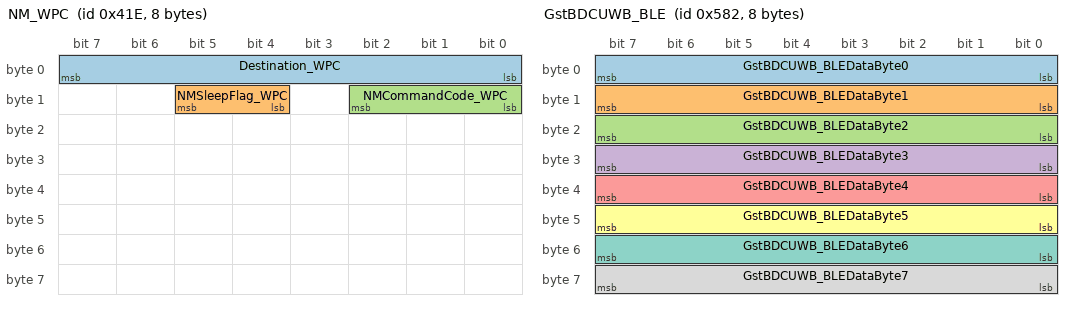
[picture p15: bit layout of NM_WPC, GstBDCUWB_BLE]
BO_ 1054 NM_WPC: 8 WPC
 SG_ Destination_WPC : 7|8@0+ (1,0) [0|0] ""  UWB_RL,UWB_FRNK,UWB_RR,UWB_INT,DHR,DHL,UWB_BLE,BDC,UWB_FL,Devtool,ROA,UWB_TRNK,UWB_FR
 SG_ NMSleepFlag_WPC : 13|2@0+ (1,0) [0|0] ""  UWB_RL,UWB_FRNK,UWB_RR,UWB_INT,DHR,DHL,UWB_BLE,BDC,UWB_FL,Devtool,ROA,UWB_TRNK,UWB_FR
 SG_ NMCommandCode_WPC : 10|3@0+ (1,0) [0|0] ""  UWB_RL,UWB_FRNK,UWB_RR,UWB_INT,DHR,DHL,UWB_BLE,BDC,UWB_FL,Devtool,ROA,UWB_TRNK,UWB_FR

BO_ 1097 NM_ROA: 8 ROA
 SG_ Destination_ROA : 7|8@0+ (1,0) [0|0] ""  UWB_RL,UWB_FRNK,UWB_RR,UWB_INT,DHR,DHL,UWB_BLE,BDC,UWB_FL,Devtool,WPC,UWB_TRNK,UWB_FR
 SG_ NMSleepFlag_ROA : 13|2@0+ (1,0) [0|0] ""  UWB_RL,UWB_FRNK,UWB_RR,UWB_INT,DHR,DHL,UWB_BLE,BDC,UWB_FL,Devtool,WPC,UWB_TRNK,UWB_FR
 SG_ NMCommandCode_ROA : 10|3@0+ (1,0) [0|0] ""  UWB_RL,UWB_FRNK,UWB_RR,UWB_INT,DHR,DHL,UWB_BLE,BDC,UWB_FL,Devtool,WPC,UWB_TRNK,UWB_FR

BO_ 1120 NM_DHL: 8 DHL
 SG_ Destination_DHL : 7|8@0+ (1,0) [0|0] ""  UWB_RL,UWB_FRNK,UWB_RR,UWB_INT,DHR,UWB_BLE,BDC,UWB_FL,Devtool,ROA,WPC,UWB_TRNK,UWB_FR
 SG_ NMSleepFlag_DHL : 13|2@0+ (1,0) [0|0] ""  UWB_RL,UWB_FRNK,UWB_RR,UWB_INT,DHR,UWB_BLE,BDC,UWB_FL,Devtool,ROA,WPC,UWB_TRNK,UWB_FR
 SG_ NMCommandCode_DHL : 10|3@0+ (1,0) [0|0] ""  UWB_RL,UWB_FRNK,UWB_RR,UWB_INT,DHR,UWB_BLE,BDC,UWB_FL,Devtool,ROA,WPC,UWB_TRNK,UWB_FR

BO_ 1121 NM_DHR: 8 DHR
 SG_ Destination_DHR : 7|8@0+ (1,0) [0|0] ""  UWB_RL,UWB_FRNK,UWB_RR,UWB_INT,DHL,UWB_BLE,BDC,UWB_FL,Devtool,ROA,WPC,UWB_TRNK,UWB_FR
 SG_ NMSleepFlag_DHR : 13|2@0+ (1,0) [0|0] ""  UWB_RL,UWB_FRNK,UWB_RR,UWB_INT,DHL,UWB_BLE,BDC,UWB_FL,Devtool,ROA,WPC,UWB_TRNK,UWB_FR
 SG_ NMCommandCode_DHR : 10|3@0+ (1,0) [0|0] ""  UWB_RL,UWB_FRNK,UWB_RR,UWB_INT,DHL,UWB_BLE,BDC,UWB_FL,Devtool,ROA,WPC,UWB_TRNK,UWB_FR

BO_ 1123 NM_Devtool: 8 Devtool
 SG_ Destination_Devtool : 7|8@0+ (1,0) [0|0] ""  UWB_RL,UWB_FRNK,UWB_RR,UWB_INT,DHR,DHL,UWB_BLE,BDC,UWB_FL,ROA,WPC,UWB_TRNK,UWB_FR
 SG_ NMSleepFlag_Devtool : 13|2@0+ (1,0) [0|0] ""  UWB_RL,UWB_FRNK,UWB_RR,UWB_INT,DHR,DHL,UWB_BLE,BDC,UWB_FL,ROA,WPC,UWB_TRNK,UWB_FR
 SG_ NMCommandCode_Devtool : 10|3@0+ (1,0) [0|0] ""  UWB_RL,UWB_FRNK,UWB_RR,UWB_INT,DHR,DHL,UWB_BLE,BDC,UWB_FL,ROA,WPC,UWB_TRNK,UWB_FR

BO_ 1126 NM_UWB_FR: 8 UWB_FR
 SG_ Destination_UWB_FR : 7|8@0+ (1,0) [0|0] ""  UWB_RL,UWB_FRNK,UWB_RR,UWB_INT,DHR,DHL,UWB_BLE,BDC,UWB_FL,Devtool,ROA,WPC,UWB_TRNK
 SG_ NMSleepFlag_UWB_FR : 13|2@0+ (1,0) [0|0] ""  UWB_RL,UWB_FRNK,UWB_RR,UWB_INT,DHR,DHL,UWB_BLE,BDC,UWB_FL,Devtool,ROA,WPC,UWB_TRNK
 SG_ NMCommandCode_UWB_FR : 10|3@0+ (1,0) [0|0] ""  UWB_RL,UWB_FRNK,UWB_RR,UWB_INT,DHR,DHL,UWB_BLE,BDC,UWB_FL,Devtool,ROA,WPC,UWB_TRNK

BO_ 1127 NM_UWB_FL: 8 UWB_FL
 SG_ Destination_UWB_FL : 7|8@0+ (1,0) [0|0] ""  UWB_RL,UWB_FRNK,UWB_RR,UWB_INT,DHR,DHL,UWB_BLE,BDC,Devtool,ROA,WPC,UWB_TRNK,UWB_FR
 SG_ NMSleepFlag_UWB_FL : 13|2@0+ (1,0) [0|0] ""  UWB_RL,UWB_FRNK,UWB_RR,UWB_INT,DHR,DHL,UWB_BLE,BDC,Devtool,ROA,WPC,UWB_TRNK,UWB_FR
 SG_ NMCommandCode_UWB_FL : 10|3@0+ (1,0) [0|0] ""  UWB_RL,UWB_FRNK,UWB_RR,UWB_INT,DHR,DHL,UWB_BLE,BDC,Devtool,ROA,WPC,UWB_TRNK,UWB_FR

BO_ 1128 NM_UWB_RR: 8 UWB_RR
 SG_ Destination_UWB_RR : 7|8@0+ (1,0) [0|0] ""  UWB_RL,UWB_FRNK,UWB_INT,DHR,DHL,UWB_BLE,BDC,UWB_FL,Devtool,ROA,WPC,UWB_TRNK,UWB_FR
 SG_ NMSleepFlag_UWB_RR : 13|2@0+ (1,0) [0|0] ""  UWB_RL,UWB_FRNK,UWB_INT,DHR,DHL,UWB_BLE,BDC,UWB_FL,Devtool,ROA,WPC,UWB_TRNK,UWB_FR
 SG_ NMCommandCode_UWB_RR : 10|3@0+ (1,0) [0|0] ""  UWB_RL,UWB_FRNK,UWB_INT,DHR,DHL,UWB_BLE,BDC,UWB_FL,Devtool,ROA,WPC,UWB_TRNK,UWB_FR

BO_ 1129 NM_UWB_RL: 8 UWB_RL
 SG_ Destination_UWB_RL : 7|8@0+ (1,0) [0|0] ""  UWB_FRNK,UWB_RR,UWB_INT,DHR,DHL,UWB_BLE,BDC,UWB_FL,Devtool,ROA,WPC,UWB_TRNK,UWB_FR
 SG_ NMSleepFlag_UWB_RL : 13|2@0+ (1,0) [0|0] ""  UWB_FRNK,UWB_RR,UWB_INT,DHR,DHL,UWB_BLE,BDC,UWB_FL,Devtool,ROA,WPC,UWB_TRNK,UWB_FR
 SG_ NMCommandCode_UWB_RL : 10|3@0+ (1,0) [0|0] ""  UWB_FRNK,UWB_RR,UWB_INT,DHR,DHL,UWB_BLE,BDC,UWB_FL,Devtool,ROA,WPC,UWB_TRNK,UWB_FR

BO_ 1133 NM_UWB_TRNK: 8 UWB_TRNK
 SG_ Destination_UWB_TRNK : 7|8@0+ (1,0) [0|0] ""  UWB_RL,UWB_FRNK,UWB_RR,UWB_INT,DHR,DHL,UWB_BLE,BDC,UWB_FL,Devtool,ROA,WPC,UWB_FR
 SG_ NMSleepFlag_UWB_TRNK : 13|2@0+ (1,0) [0|0] ""  UWB_RL,UWB_FRNK,UWB_RR,UWB_INT,DHR,DHL,UWB_BLE,BDC,UWB_FL,Devtool,ROA,WPC,UWB_FR
 SG_ NMCommandCode_UWB_TRNK : 10|3@0+ (1,0) [0|0] ""  UWB_RL,UWB_FRNK,UWB_RR,UWB_INT,DHR,DHL,UWB_BLE,BDC,UWB_FL,Devtool,ROA,WPC,UWB_FR

BO_ 1134 NM_UWB_FRNK: 8 UWB_FRNK
 SG_ Destination_UWB_FRNK : 7|8@0+ (1,0) [0|0] ""  UWB_RL,UWB_RR,UWB_INT,DHR,DHL,UWB_BLE,BDC,UWB_FL,Devtool,ROA,WPC,UWB_TRNK,UWB_FR
 SG_ NMSleepFlag_UWB_FRNK : 13|2@0+ (1,0) [0|0] ""  UWB_RL,UWB_RR,UWB_INT,DHR,DHL,UWB_BLE,BDC,UWB_FL,Devtool,ROA,WPC,UWB_TRNK,UWB_FR
 SG_ NMCommandCode_UWB_FRNK : 10|3@0+ (1,0) [0|0] ""  UWB_RL,UWB_RR,UWB_INT,DHR,DHL,UWB_BLE,BDC,UWB_FL,Devtool,ROA,WPC,UWB_TRNK,UWB_FR

BO_ 1140 NM_UWB_BLE: 8 UWB_BLE
 SG_ Destination_UWB_BLE : 7|8@0+ (1,0) [0|0] ""  UWB_RL,UWB_FRNK,UWB_RR,UWB_INT,DHR,DHL,BDC,UWB_FL,Devtool,ROA,WPC,UWB_TRNK,UWB_FR
 SG_ NMSleepFlag_UWB_BLE : 13|2@0+ (1,0) [0|0] ""  UWB_RL,UWB_FRNK,UWB_RR,UWB_INT,DHR,DHL,BDC,UWB_FL,Devtool,ROA,WPC,UWB_TRNK,UWB_FR
 SG_ NMCommandCode_UWB_BLE : 10|3@0+ (1,0) [0|0] ""  UWB_RL,UWB_FRNK,UWB_RR,UWB_INT,DHR,DHL,BDC,UWB_FL,Devtool,ROA,WPC,UWB_TRNK,UWB_FR

BO_ 1141 NM_UWB_INT: 8 UWB_INT
 SG_ Destination_UWB_INT : 7|8@0+ (1,0) [0|0] ""  UWB_RL,UWB_FRNK,UWB_RR,DHR,DHL,UWB_BLE,BDC,UWB_FL,Devtool,ROA,WPC,UWB_TRNK,UWB_FR
 SG_ NMSleepFlag_UWB_INT : 13|2@0+ (1,0) [0|0] ""  UWB_RL,UWB_FRNK,UWB_RR,DHR,DHL,UWB_BLE,BDC,UWB_FL,Devtool,ROA,WPC,UWB_TRNK,UWB_FR
 SG_ NMCommandCode_UWB_INT : 10|3@0+ (1,0) [0|0] ""  UWB_RL,UWB_FRNK,UWB_RR,DHR,DHL,UWB_BLE,BDC,UWB_FL,Devtool,ROA,WPC,UWB_TRNK,UWB_FR

BO_ 1410 GstBDCUWB_BLE: 8 BDC
 SG_ GstBDCUWB_BLEDataByte0 : 7|8@0+ (1,0) [0|0] ""  UWB_BLE
 SG_ GstBDCUWB_BLEDataByte1 : 15|8@0+ (1,0) [0|0] ""  UWB_BLE
 SG_ GstBDCUWB_BLEDataByte2 : 23|8@0+ (1,0) [0|0] ""  UWB_BLE
 SG_ GstBDCUWB_BLEDataByte3 : 31|8@0+ (1,0) [0|0] ""  UWB_BLE
 SG_ GstBDCUWB_BLEDataByte4 : 39|8@0+ (1,0) [0|0] ""  UWB_BLE
 SG_ GstBDCUWB_BLEDataByte5 : 47|8@0+ (1,0) [0|0] ""  UWB_BLE
 SG_ GstBDCUWB_BLEDataByte6 : 55|8@0+ (1,0) [0|0] ""  UWB_BLE
 SG_ GstBDCUWB_BLEDataByte7 : 63|8@0+ (1,0) [0|0] ""  UWB_BLE

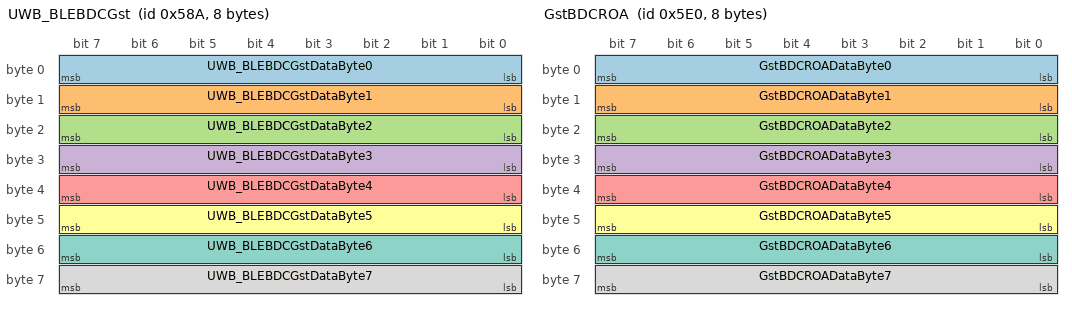
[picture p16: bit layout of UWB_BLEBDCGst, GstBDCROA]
BO_ 1418 UWB_BLEBDCGst: 8 UWB_BLE
 SG_ UWB_BLEBDCGstDataByte0 : 7|8@0+ (1,0) [0|0] ""  BDC
 SG_ UWB_BLEBDCGstDataByte1 : 15|8@0+ (1,0) [0|0] ""  BDC
 SG_ UWB_BLEBDCGstDataByte2 : 23|8@0+ (1,0) [0|0] ""  BDC
 SG_ UWB_BLEBDCGstDataByte3 : 31|8@0+ (1,0) [0|0] ""  BDC
 SG_ UWB_BLEBDCGstDataByte4 : 39|8@0+ (1,0) [0|0] ""  BDC
 SG_ UWB_BLEBDCGstDataByte5 : 47|8@0+ (1,0) [0|0] ""  BDC
 SG_ UWB_BLEBDCGstDataByte6 : 55|8@0+ (1,0) [0|0] ""  BDC
 SG_ UWB_BLEBDCGstDataByte7 : 63|8@0+ (1,0) [0|0] ""  BDC

BO_ 1504 GstBDCROA: 8 BDC
 SG_ GstBDCROADataByte0 : 7|8@0+ (1,0) [0|0] ""  ROA
 SG_ GstBDCROADataByte1 : 15|8@0+ (1,0) [0|0] ""  ROA
 SG_ GstBDCROADataByte2 : 23|8@0+ (1,0) [0|0] ""  ROA
 SG_ GstBDCROADataByte3 : 31|8@0+ (1,0) [0|0] ""  ROA
 SG_ GstBDCROADataByte4 : 39|8@0+ (1,0) [0|0] ""  ROA
 SG_ GstBDCROADataByte5 : 47|8@0+ (1,0) [0|0] ""  ROA
 SG_ GstBDCROADataByte6 : 55|8@0+ (1,0) [0|0] ""  ROA
 SG_ GstBDCROADataByte7 : 63|8@0+ (1,0) [0|0] ""  ROA

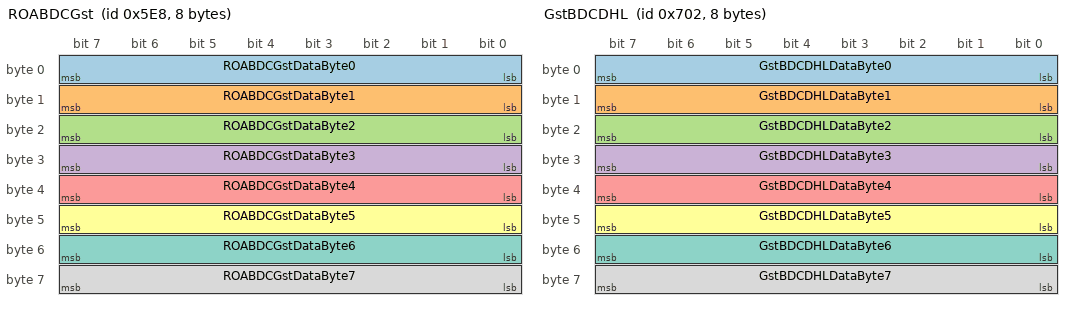
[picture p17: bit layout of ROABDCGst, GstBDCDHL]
BO_ 1512 ROABDCGst: 8 ROA
 SG_ ROABDCGstDataByte0 : 7|8@0+ (1,0) [0|0] ""  BDC
 SG_ ROABDCGstDataByte1 : 15|8@0+ (1,0) [0|0] ""  BDC
 SG_ ROABDCGstDataByte2 : 23|8@0+ (1,0) [0|0] ""  BDC
 SG_ ROABDCGstDataByte3 : 31|8@0+ (1,0) [0|0] ""  BDC
 SG_ ROABDCGstDataByte4 : 39|8@0+ (1,0) [0|0] ""  BDC
 SG_ ROABDCGstDataByte5 : 47|8@0+ (1,0) [0|0] ""  BDC
 SG_ ROABDCGstDataByte6 : 55|8@0+ (1,0) [0|0] ""  BDC
 SG_ ROABDCGstDataByte7 : 63|8@0+ (1,0) [0|0] ""  BDC

BO_ 1794 GstBDCDHL: 8 BDC
 SG_ GstBDCDHLDataByte0 : 7|8@0+ (1,0) [0|0] ""  DHL
 SG_ GstBDCDHLDataByte1 : 15|8@0+ (1,0) [0|0] ""  DHL
 SG_ GstBDCDHLDataByte2 : 23|8@0+ (1,0) [0|0] ""  DHL
 SG_ GstBDCDHLDataByte3 : 31|8@0+ (1,0) [0|0] ""  DHL
 SG_ GstBDCDHLDataByte4 : 39|8@0+ (1,0) [0|0] ""  DHL
 SG_ GstBDCDHLDataByte5 : 47|8@0+ (1,0) [0|0] ""  DHL
 SG_ GstBDCDHLDataByte6 : 55|8@0+ (1,0) [0|0] ""  DHL
 SG_ GstBDCDHLDataByte7 : 63|8@0+ (1,0) [0|0] ""  DHL

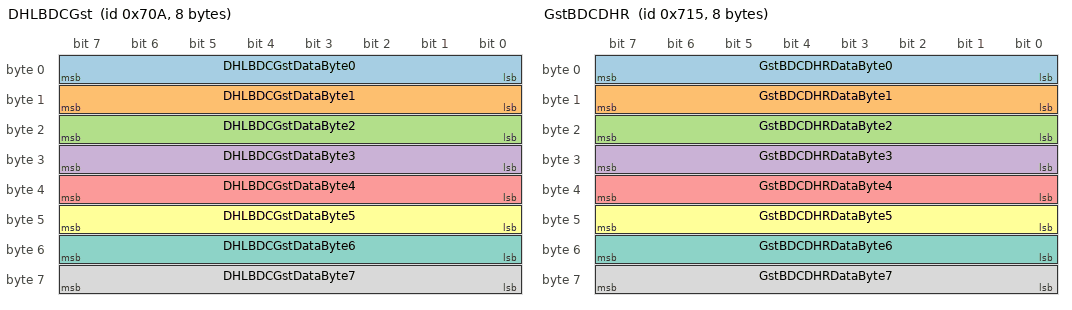
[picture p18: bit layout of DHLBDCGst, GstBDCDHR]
BO_ 1802 DHLBDCGst: 8 DHL
 SG_ DHLBDCGstDataByte0 : 7|8@0+ (1,0) [0|0] ""  BDC
 SG_ DHLBDCGstDataByte1 : 15|8@0+ (1,0) [0|0] ""  BDC
 SG_ DHLBDCGstDataByte2 : 23|8@0+ (1,0) [0|0] ""  BDC
 SG_ DHLBDCGstDataByte3 : 31|8@0+ (1,0) [0|0] ""  BDC
 SG_ DHLBDCGstDataByte4 : 39|8@0+ (1,0) [0|0] ""  BDC
 SG_ DHLBDCGstDataByte5 : 47|8@0+ (1,0) [0|0] ""  BDC
 SG_ DHLBDCGstDataByte6 : 55|8@0+ (1,0) [0|0] ""  BDC
 SG_ DHLBDCGstDataByte7 : 63|8@0+ (1,0) [0|0] ""  BDC

BO_ 1813 GstBDCDHR: 8 BDC
 SG_ GstBDCDHRDataByte0 : 7|8@0+ (1,0) [0|0] ""  DHR
 SG_ GstBDCDHRDataByte1 : 15|8@0+ (1,0) [0|0] ""  DHR
 SG_ GstBDCDHRDataByte2 : 23|8@0+ (1,0) [0|0] ""  DHR
 SG_ GstBDCDHRDataByte3 : 31|8@0+ (1,0) [0|0] ""  DHR
 SG_ GstBDCDHRDataByte4 : 39|8@0+ (1,0) [0|0] ""  DHR
 SG_ GstBDCDHRDataByte5 : 47|8@0+ (1,0) [0|0] ""  DHR
 SG_ GstBDCDHRDataByte6 : 55|8@0+ (1,0) [0|0] ""  DHR
 SG_ GstBDCDHRDataByte7 : 63|8@0+ (1,0) [0|0] ""  DHR

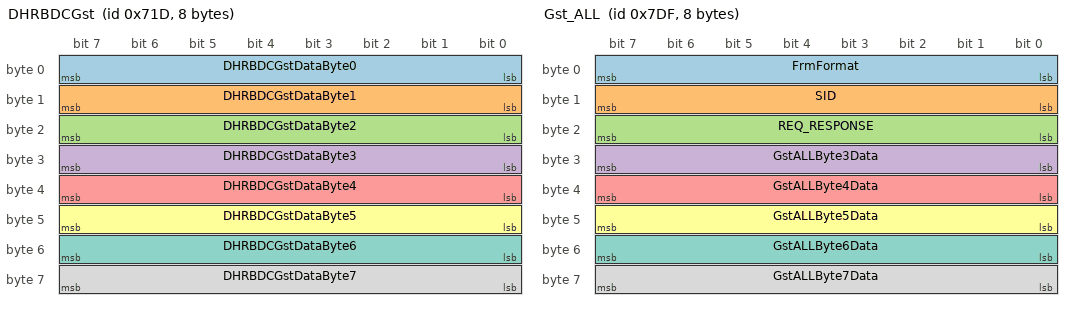
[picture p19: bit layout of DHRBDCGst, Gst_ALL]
BO_ 1821 DHRBDCGst: 8 DHR
 SG_ DHRBDCGstDataByte0 : 7|8@0+ (1,0) [0|0] ""  BDC
 SG_ DHRBDCGstDataByte1 : 15|8@0+ (1,0) [0|0] ""  BDC
 SG_ DHRBDCGstDataByte2 : 23|8@0+ (1,0) [0|0] ""  BDC
 SG_ DHRBDCGstDataByte3 : 31|8@0+ (1,0) [0|0] ""  BDC
 SG_ DHRBDCGstDataByte4 : 39|8@0+ (1,0) [0|0] ""  BDC
 SG_ DHRBDCGstDataByte5 : 47|8@0+ (1,0) [0|0] ""  BDC
 SG_ DHRBDCGstDataByte6 : 55|8@0+ (1,0) [0|0] ""  BDC
 SG_ DHRBDCGstDataByte7 : 63|8@0+ (1,0) [0|0] ""  BDC

BO_ 2015 Gst_ALL: 8 BDC
 SG_ FrmFormat : 7|8@0+ (1,0) [0|0] ""  DHL,DHR,ROA,UWB_BLE,WPC
 SG_ SID : 15|8@0+ (1,0) [0|0] ""  DHL,DHR,ROA,UWB_BLE,WPC
 SG_ REQ_RESPONSE : 23|8@0+ (1,0) [0|0] ""  DHL,DHR,ROA,UWB_BLE,WPC
 SG_ GstALLByte3Data : 31|8@0+ (1,0) [0|0] ""  DHL,DHR,ROA,UWB_BLE,WPC
 SG_ GstALLByte4Data : 39|8@0+ (1,0) [0|0] ""  DHL,DHR,ROA,UWB_BLE,WPC
 SG_ GstALLByte5Data : 47|8@0+ (1,0) [0|0] ""  DHL,DHR,ROA,UWB_BLE,WPC
 SG_ GstALLByte6Data : 55|8@0+ (1,0) [0|0] ""  DHL,DHR,ROA,UWB_BLE,WPC
 SG_ GstALLByte7Data : 63|8@0+ (1,0) [0|0] ""  DHL,DHR,ROA,UWB_BLE,WPC

CM_ BO_ 392 "[PE] Periodic and On Event";
CM_ SG_ 392 C_UWB_MASTER_Status1 "UWB_MASTER Processing Status 1";
CM_ SG_ 392 C_UWB_MASTER_Status2 "UWB_MASTER Processing Status 2";
CM_ SG_ 392 C_UWB_MASTER_Status3 "UWB_MASTER Processing Status 3";
CM_ SG_ 392 C_UWB_MASTER_Status4 "UWB_MASTER Processing Status 4";
CM_ SG_ 392 C_UWB_MASTER_Status5 "UWB_MASTER Processing Status 5";
CM_ SG_ 392 C_UWB_MASTER_Status6 "UWB_MASTER Processing Status 6";
CM_ SG_ 392 C_UWB_MASTER_Status7 "UWB_MASTER Processing Status 7";
CM_ SG_ 392 C_UWB_MASTER_Status8 "UWB_MASTER Processing Status 8";
CM_ SG_ 392 C_UWB_MASTER_Option "UWB INT1 Applied Signal";
CM_ BO_ 393 "[PE] Periodic and On Event";
CM_ SG_ 393 C_UWB_Master_DK_ConnStat "Digital key connection status";
CM_ SG_ 393 C_UWB_Mst_DK_LocalizationStat "Digital key localization status";
CM_ BO_ 394 "[PE] Periodic and On Event";
CM_ SG_ 394 C_UWB_Mst_EncryptedResult1Val "Enrypted result of UWB_BLE Master";
CM_ BO_ 395 "[PE] Periodic and On Event";
CM_ SG_ 395 C_UWB_Mst_EncryptedResult2Val "Enrypted result of UWB_BLE Master";
CM_ BO_ 396 "[PE] Periodic and On Event";
CM_ SG_ 396 C_UWB_Master2BDC_RndNum "Random Number for EncryptedData1,2";
CM_ BO_ 397 "[EC] On Event and On Change";
CM_ SG_ 397 C_UWB_Master_LocalRN_Target "Local Random Number Target Define";
CM_ SG_ 397 C_UWB_Master_LocalRN_TRCode "Local Random Number TRCode";
CM_ SG_ 397 C_UWB_Master_LocalRN_CMD "Local Random Number CMD";
CM_ SG_ 397 C_UWB_Master_LocalRndNum "Random Number for Encyption to IAU Local CAN Modules";
CM_ BO_ 398 "[EC] On Event and On Change";
CM_ SG_ 398 UWB_Master_ToUWBEncryptData1 "Encryption Data From UWB Master to UWB ALL";
CM_ BO_ 399 "[EC] On Event and On Change";
CM_ SG_ 399 UWB_Master_ToUWBEncryptData2 "Encryption Data From UWB Master to UWB ALL";
CM_ BO_ 400 "[PE] Periodic and On Event";
CM_ SG_ 400 C_UWB_RL_Status1 "UWB_RL Processing Status 1";
CM_ SG_ 400 C_UWB_RL_Status2 "UWB_RL Processing Status 2";
CM_ SG_ 400 C_UWB_RL_Status3 "UWB_RL Processing Status 3";
CM_ SG_ 400 C_UWB_RL_Status4 "UWB_RL Processing Status 4";
CM_ SG_ 400 C_UWB_RL_Status5 "UWB_RL Processing Status 5";
CM_ SG_ 400 C_UWB_RL_Status6 "UWB_RL Processing Status 6";
CM_ SG_ 400 C_UWB_RL_Status7 "UWB_RL Processing Status 7";
CM_ SG_ 400 C_UWB_RL_Status8 "UWB_RL Processing Status 8";
CM_ SG_ 400 C_UWB_RL_DTC "UWB RL DTC Data";
CM_ SG_ 400 C_UWB_RL_Option "UWB RL Applied Signal";
CM_ BO_ 401 "[P] Periodic";
CM_ SG_ 401 C_UWB_RL_HW_Ver_Major "UWB RL HW Version Major";
CM_ SG_ 401 C_UWB_RL_HW_Ver_Minor "UWB RL HW Version Minor";
CM_ SG_ 401 C_UWB_RL_SW_MCU_Ver_Major "UWB RL SW MCU Version Major";
CM_ SG_ 401 C_UWB_RL_SW_MCU_Ver_Minor "UWB RL SW MCU Version Minor";
CM_ SG_ 401 C_UWB_RL_SW_IC_Ver_Major "UWB RL SW IC Version Major";
CM_ SG_ 401 C_UWB_RL_SW_IC_Ver_Minor "UWB RL SW IC Version Minor";
CM_ BO_ 405 "[PE] Periodic and On Event";
CM_ SG_ 405 C_UWB_RR_Status1 "UWB_RR Processing Status 1";
CM_ SG_ 405 C_UWB_RR_Status2 "UWB_RR Processing Status 2";
CM_ SG_ 405 C_UWB_RR_Status3 "UWB_RR Processing Status 3";
CM_ SG_ 405 C_UWB_RR_Status4 "UWB_RR Processing Status 4";
CM_ SG_ 405 C_UWB_RR_Status5 "UWB_RR Processing Status 5";
CM_ SG_ 405 C_UWB_RR_Status6 "UWB_RR Processing Status 6";
CM_ SG_ 405 C_UWB_RR_Status7 "UWB_RR Processing Status 7";
CM_ SG_ 405 C_UWB_RR_Status8 "UWB_RR Processing Status 8";
CM_ SG_ 405 C_UWB_RR_DTC "UWB RR DTC Data";
CM_ SG_ 405 C_UWB_RR_Option "UWB RR Applied Signal";
CM_ BO_ 406 "[P] Periodic";
CM_ SG_ 406 C_UWB_RR_HW_Ver_Major "UWB RR HW Version Major";
CM_ SG_ 406 C_UWB_RR_HW_Ver_Minor "UWB RR HW Version Minor";
CM_ SG_ 406 C_UWB_RR_SW_MCU_Ver_Major "UWB RR SW MCU Version Major";
CM_ SG_ 406 C_UWB_RR_SW_MCU_Ver_Minor "UWB RR SW MCU Version Minor";
CM_ SG_ 406 C_UWB_RR_SW_IC_Ver_Major "UWB RR SW IC Version Major";
CM_ SG_ 406 C_UWB_RR_SW_IC_Ver_Minor "UWB RR SW IC Version Minor";
CM_ BO_ 410 "[PE] Periodic and On Event";
CM_ SG_ 410 C_UWB_TRUNK_Status1 "UWB_TRUNK Processing Status 1";
CM_ SG_ 410 C_UWB_TRUNK_Status2 "UWB_TRUNK Processing Status 2";
CM_ SG_ 410 C_UWB_TRUNK_Status3 "UWB_TRUNK Processing Status 3";
CM_ SG_ 410 C_UWB_TRUNK_Status4 "UWB_TRUNK Processing Status 4";
CM_ SG_ 410 C_UWB_TRUNK_Status5 "UWB_TRUNK Processing Status 5";
CM_ SG_ 410 C_UWB_TRUNK_Status6 "UWB_TRUNK Processing Status 6";
CM_ SG_ 410 C_UWB_TRUNK_Status7 "UWB_TRUNK Processing Status 7";
CM_ SG_ 410 C_UWB_TRUNK_Status8 "UWB_TRUNK Processing Status 8";
CM_ SG_ 410 C_UWB_TRNK_DTC "UWB Trunk DTC Data";
CM_ SG_ 410 C_UWB_TRUNK_Option "UWB TRUNK Applied Signal";
CM_ BO_ 411 "[P] Periodic";
CM_ SG_ 411 C_UWB_TRNK_HW_Ver_Major "UWB TRNK HW Version Major";
CM_ SG_ 411 C_UWB_TRNK_HW_Ver_Minor "UWB TRNK HW Version Minor";
CM_ SG_ 411 C_UWB_TRNK_SW_MCU_Ver_Major "UWB TRNK SW MCU Version Major";
CM_ SG_ 411 C_UWB_TRNK_SW_MCU_Ver_Minor "UWB TRNK SW MCU Version Minor";
CM_ SG_ 411 C_UWB_TRNK_SW_IC_Ver_Major "UWB TRNK SW IC Version Major";
CM_ SG_ 411 C_UWB_TRNK_SW_IC_Ver_Minor "UWB TRNK SW IC Version Minor";
CM_ BO_ 418 "[EW] On Event and On Write";
CM_ SG_ 418 C_UWB_INT_To_MasterEncData1 "Encryption Data From UWB_INT";
CM_ BO_ 450 "[EW] On Event and On Write";
CM_ SG_ 450 C_UWB_RL_To_MasterEncData1 "Encryption Data From UWB_RL";
CM_ BO_ 451 "[EW] On Event and On Write";
CM_ SG_ 451 C_UWB_RL_To_MasterEncData2 "Encryption Data From UWB_RL";
CM_ BO_ 452 "[EC] On Event and On Change";
CM_ SG_ 452 C_UWB_RL_To_BDCFOBRSDResult "Distance result of UWB ranging";
CM_ BO_ 453 "[EC] On Event and On Change";
CM_ SG_ 453 C_UWB_RL_MCU_Bootloader "UWB MCU_Bootloader";
CM_ SG_ 453 C_UWB_RL_MCU_Flash_Erase "UWB_MCU_Flash_Erase";
CM_ SG_ 453 C_UWB_RL_MCU_CRC32 "UWB_MCU_CRC32";
CM_ BO_ 454 "[EC] On Event and On Change";
CM_ SG_ 454 C_UWB_RL_IC_Bootloader "UWB_IC_Bootloader";
CM_ SG_ 454 C_UWB_RL_IC_Flash_Erase "UWB_IC_Flash_Erase";
CM_ SG_ 454 C_UWB_RL_IC_CRC32 "UWB_IC_CRC32";
CM_ BO_ 455 "[EC] On Event and On Change";
CM_ SG_ 455 C_UWB_RL_Decrypt_FB "UWB RL Decryption Feed Back";
CM_ BO_ 482 "[EW] On Event and On Write";
CM_ SG_ 482 C_UWB_RR_To_MasterEncData1 "Encryption Data From UWB_RR";
CM_ BO_ 483 "[EW] On Event and On Write";
CM_ SG_ 483 C_UWB_RR_To_MasterEncData2 "Encryption Data From UWB_RR";
CM_ BO_ 484 "[EC] On Event and On Change";
CM_ SG_ 484 C_UWB_RR_To_BDCFOBRSDResult "Distance result of UWB ranging";
CM_ BO_ 485 "[EC] On Event and On Change";
CM_ SG_ 485 C_UWB_RR_MCU_Bootloader "UWB MCU_Bootloader";
CM_ SG_ 485 C_UWB_RR_MCU_Flash_Erase "UWB_MCU_Flash_Erase";
CM_ SG_ 485 C_UWB_RR_MCU_CRC32 "UWB_MCU_CRC32";
CM_ BO_ 486 "[EC] On Event and On Change";
CM_ SG_ 486 C_UWB_RR_IC_Bootloader "UWB_IC_Bootloader";
CM_ SG_ 486 C_UWB_RR_IC_Flash_Erase "UWB_IC_Flash_Erase";
CM_ SG_ 486 C_UWB_RR_IC_CRC32 "UWB_IC_CRC32";
CM_ BO_ 487 "[EC] On Event and On Change";
CM_ SG_ 487 C_UWB_RR_Decrypt_FB "UWB RR Decryption Feed Back";
CM_ BO_ 498 "[EW] On Event and On Write";
CM_ SG_ 498 C_UWB_TRNK_To_MasterEncData1 "Encryption Data From UWB_TRNK";
CM_ BO_ 499 "[EW] On Event and On Write";
CM_ SG_ 499 C_UWB_TRNK_To_MasterEncData2 "Encryption Data From UWB_TRNK";
CM_ BO_ 500 "[EC] On Event and On Change";
CM_ SG_ 500 C_UWB_TRNK_To_BDCFOBRSDResult "Distance result of UWB ranging";
CM_ BO_ 501 "[EC] On Event and On Change";
CM_ SG_ 501 C_UWB_TRNK_MCU_Bootloader "UWB MCU_Bootloader";
CM_ SG_ 501 C_UWB_TRNK_MCU_Flash_Erase "UWB_MCU_Flash_Erase";
CM_ SG_ 501 C_UWB_TRNK_MCU_CRC32 "UWB_MCU_CRC32";
CM_ BO_ 502 "[EC] On Event and On Change";
CM_ SG_ 502 C_UWB_TRNK_IC_Bootloader "UWB_IC_Bootloader";
CM_ SG_ 502 C_UWB_TRNK_IC_Flash_Erase "UWB_IC_Flash_Erase";
CM_ SG_ 502 C_UWB_TRNK_IC_CRC32 "UWB_IC_CRC32";
CM_ BO_ 503 "[EC] On Event and On Change";
CM_ SG_ 503 C_UWB_TRNK_Decrypt_FB "UWB TRNK Decryption Feed Back";
CM_ BO_ 768 "[TP] TP Message";
CM_ SG_ 768 C_BDCBLETpByte0Data "TP  From BDC to BLE";
CM_ SG_ 768 C_BDCBLETpByte1Data "TP  From BDC to BLE";
CM_ SG_ 768 C_BDCBLETpByte2Data "TP  From BDC to BLE";
CM_ SG_ 768 C_BDCBLETpByte3Data "TP  From BDC to BLE";
CM_ SG_ 768 C_BDCBLETpByte4Data "TP  From BDC to BLE";
CM_ SG_ 768 C_BDCBLETpByte5Data "TP  From BDC to BLE";
CM_ SG_ 768 C_BDCBLETpByte6Data "TP  From BDC to BLE";
CM_ SG_ 768 C_BDCBLETpByte7Data "TP  From BDC to BLE";
CM_ BO_ 770 "[TP] TP Message";
CM_ SG_ 770 C_BDCDHLTpByte0Data "TP  From BDC to DHL";
CM_ SG_ 770 C_BDCDHLTpByte1Data "TP  From BDC to DHL";
CM_ SG_ 770 C_BDCDHLTpByte2Data "TP  From BDC to DHL";
CM_ SG_ 770 C_BDCDHLTpByte3Data "TP  From BDC to DHL";
CM_ SG_ 770 C_BDCDHLTpByte4Data "TP  From BDC to DHL";
CM_ SG_ 770 C_BDCDHLTpByte5Data "TP  From BDC to DHL";
CM_ SG_ 770 C_BDCDHLTpByte6Data "TP  From BDC to DHL";
CM_ SG_ 770 C_BDCDHLTpByte7Data "TP  From BDC to DHL";
CM_ BO_ 772 "[TP] TP Message";
CM_ SG_ 772 C_BDCDHRTpByte0Data "TP  From BDC to DHR";
CM_ SG_ 772 C_BDCDHRTpByte1Data "TP  From BDC to DHR";
CM_ SG_ 772 C_BDCDHRTpByte2Data "TP  From BDC to DHR";
CM_ SG_ 772 C_BDCDHRTpByte3Data "TP  From BDC to DHR";
CM_ SG_ 772 C_BDCDHRTpByte4Data "TP  From BDC to DHR";
CM_ SG_ 772 C_BDCDHRTpByte5Data "TP  From BDC to DHR";
CM_ SG_ 772 C_BDCDHRTpByte6Data "TP  From BDC to DHR";
CM_ SG_ 772 C_BDCDHRTpByte7Data "TP  From BDC to DHR";
CM_ BO_ 778 "[TP] TP Message";
CM_ SG_ 778 C_BDCWPCTpByte0Data "TP From BDC to WPC";
CM_ SG_ 778 C_BDCWPCTpByte1Data "TP From BDC to WPC";
CM_ SG_ 778 C_BDCWPCTpByte2Data "TP From BDC to WPC";
CM_ SG_ 778 C_BDCWPCTpByte3Data "TP From BDC to WPC";
CM_ SG_ 778 C_BDCWPCTpByte4Data "TP From BDC to WPC";
CM_ SG_ 778 C_BDCWPCTpByte5Data "TP From BDC to WPC";
CM_ SG_ 778 C_BDCWPCTpByte6Data "TP From BDC to WPC";
CM_ SG_ 778 C_BDCWPCTpByte7Data "TP From BDC to WPC";
CM_ BO_ 780 "[TP] TP Message";
CM_ SG_ 780 C_BLEBDCTpByte0Data "TP From BLE to BDC";
CM_ SG_ 780 C_BLEBDCTpByte1Data "TP From BLE to BDC";
CM_ SG_ 780 C_BLEBDCTpByte2Data "TP From BLE to BDC";
CM_ SG_ 780 C_BLEBDCTpByte3Data "TP From BLE to BDC";
CM_ SG_ 780 C_BLEBDCTpByte4Data "TP From BLE to BDC";
CM_ SG_ 780 C_BLEBDCTpByte5Data "TP From BLE to BDC";
CM_ SG_ 780 C_BLEBDCTpByte6Data "TP From BLE to BDC";
CM_ SG_ 780 C_BLEBDCTpByte7Data "TP From BLE to BDC";
CM_ BO_ 784 "[TP] TP Message";
CM_ SG_ 784 C_DHLBDCTpByte0Data "TP From DHL to BDC";
CM_ SG_ 784 C_DHLBDCTpByte1Data "TP From DHL to BDC";
CM_ SG_ 784 C_DHLBDCTpByte2Data "TP From DHL to BDC";
CM_ SG_ 784 C_DHLBDCTpByte3Data "TP From DHL to BDC";
CM_ SG_ 784 C_DHLBDCTpByte4Data "TP From DHL to BDC";
CM_ SG_ 784 C_DHLBDCTpByte5Data "TP From DHL to BDC";
CM_ SG_ 784 C_DHLBDCTpByte6Data "TP From DHL to BDC";
CM_ SG_ 784 C_DHLBDCTpByte7Data "TP From DHL to BDC";
CM_ BO_ 786 "[TP] TP Message";
CM_ SG_ 786 C_DHRBDCTpByte0Data "TP From DHL to BDC";
CM_ SG_ 786 C_DHRBDCTpByte1Data "TP From DHL to BDC";
CM_ SG_ 786 C_DHRBDCTpByte2Data "TP From DHL to BDC";
CM_ SG_ 786 C_DHRBDCTpByte3Data "TP From DHL to BDC";
CM_ SG_ 786 C_DHRBDCTpByte4Data "TP From DHL to BDC";
CM_ SG_ 786 C_DHRBDCTpByte5Data "TP From DHL to BDC";
CM_ SG_ 786 C_DHRBDCTpByte6Data "TP From DHL to BDC";
CM_ SG_ 786 C_DHRBDCTpByte7Data "TP From DHL to BDC";
CM_ BO_ 792 "[TP] TP Message";
CM_ SG_ 792 C_WPCBDCTpByte0Data "TP From WPC to BDC";
CM_ SG_ 792 C_WPCBDCTpByte1Data "TP From WPC to BDC";
CM_ SG_ 792 C_WPCBDCTpByte2Data "TP From WPC to BDC";
CM_ SG_ 792 C_WPCBDCTpByte3Data "TP From WPC to BDC";
CM_ SG_ 792 C_WPCBDCTpByte4Data "TP From WPC to BDC";
CM_ SG_ 792 C_WPCBDCTpByte5Data "TP From WPC to BDC";
CM_ SG_ 792 C_WPCBDCTpByte6Data "TP From WPC to BDC";
CM_ SG_ 792 C_WPCBDCTpByte7Data "TP From WPC to BDC";
CM_ BO_ 800 "[EC] On Event and On Change";
CM_ BO_ 816 "[EC] On Event and On Change";
CM_ BO_ 832 "[EC] On Event and On Change";
CM_ BO_ 864 "[EC] On Event and On Change";
CM_ BO_ 865 "[EC] On Event and On Change";
CM_ BO_ 870 "[EC] On Event and On Change";
CM_ BO_ 871 "[EC] On Event and On Change";
CM_ BO_ 872 "[EC] On Event and On Change";
CM_ BO_ 873 "[EC] On Event and On Change";
CM_ BO_ 874 "[EC] On Event and On Change";
CM_ BO_ 877 "[EC] On Event and On Change";
CM_ BO_ 884 "[EC] On Event and On Change";
CM_ BO_ 885 "[EC] On Event and On Change";
CM_ BO_ 888 "[EC] On Event and On Change";
CM_ SG_ 888 UWB_BLE_Dvp2Data "UWB Master Development Message";
CM_ BO_ 889 "[EC] On Event and On Change";
CM_ SG_ 889 UWB_BLE_Dvp3Data "UWB Master Development Message";
CM_ BO_ 896 "[EC] On Event and On Change";
CM_ SG_ 896 UWB_BLE_Dvp4Data "UWB Master Development Message";
CM_ BO_ 1024 "NM Message";
CM_ BO_ 1054 "NM Message";
CM_ BO_ 1097 "NM Message";
CM_ BO_ 1120 "NM Message";
CM_ BO_ 1121 "NM Message";
CM_ BO_ 1123 "NM Message";
CM_ BO_ 1126 "NM Message";
CM_ BO_ 1127 "NM Message";
CM_ BO_ 1128 "NM Message";
CM_ BO_ 1129 "NM Message";
CM_ BO_ 1133 "NM Message";
CM_ BO_ 1134 "NM Message";
CM_ BO_ 1140 "NM Message";
CM_ BO_ 1141 "NM Message";
CM_ BO_ 1410 "[EW] On Event and On Write";
CM_ BO_ 1418 "[EW] On Event and On Write";
CM_ BO_ 1504 "[EW] On Event and On Write";
CM_ SG_ 1504 GstBDCROADataByte0 "Diag MSG";
CM_ SG_ 1504 GstBDCROADataByte1 "Diag MSG";
CM_ SG_ 1504 GstBDCROADataByte2 "Diag MSG";
CM_ SG_ 1504 GstBDCROADataByte3 "Diag MSG";
CM_ SG_ 1504 GstBDCROADataByte4 "Diag MSG";
CM_ SG_ 1504 GstBDCROADataByte5 "Diag MSG";
CM_ SG_ 1504 GstBDCROADataByte6 "Diag MSG";
CM_ SG_ 1504 GstBDCROADataByte7 "Diag MSG";
CM_ BO_ 1512 "[EW] On Event and On Write";
CM_ BO_ 1794 "[EW] On Event and On Write";
CM_ BO_ 1802 "[EW] On Event and On Write";
CM_ BO_ 1813 "[EW] On Event and On Write";
CM_ BO_ 1821 "[EW] On Event and On Write";
CM_ BO_ 2015 "[EW] On Event and On Write";
BA_DEF_ SG_  "NWM-WakeupAllowed" ENUM  "<n.a.>";
BA_DEF_ BO_  "NWM-Botschaft" ENUM  "No","Yes";
BA_DEF_ SG_  "GenSigEnvVarType" ENUM  "int","float","undef";
BA_DEF_ SG_  "GwSigLatencyTime" INT 0 65535;
BA_DEF_ SG_  "GwSigMissingSourceType" ENUM  "Undef","OldValue","DefaultValue","InitialValue";
BA_DEF_ SG_  "SignalCategory" HEX 10 15;
BA_DEF_ SG_  "GenSigSendType" ENUM  "Cyclic","OnWrite","OnWriteWithRepetition","OnChange","OnChangeWithRepetition","IfActive","IfActiveWithRepetition","NoSigSendType";
BA_DEF_ BO_  "GenMsgDelayTime" INT 20 20;
BA_DEF_ BO_  "NmMessage" ENUM  "No","Yes";
BA_DEF_ BO_  "GenMsgILSupport" ENUM  "No","Yes";
BA_DEF_ BO_  "GenMsgNrOfRepetition" INT 0 3;
BA_DEF_ BO_  "GenMsgCycleTimeFast" INT 0 500;
BA_DEF_ BO_  "GenMsgStartDelayTime" INT 0 100;
BA_DEF_ BO_  "GenMsgSendType" ENUM  "Cyclic","not_used","not_used","not_used","not_used","not_used","not_used","not_used","NoMsgSendType";
BA_DEF_ BO_  "GenMsgCycleTime" INT 0 2000;
BA_DEF_REL_ BU_SG_REL_  "GenSigTimeoutTime" INT 175 3500;
BA_DEF_DEF_  "NWM-WakeupAllowed" "<n.a.>";
BA_DEF_DEF_  "NWM-Botschaft" "No";
BA_DEF_DEF_  "GenSigEnvVarType" "undef";
BA_DEF_DEF_  "GwSigLatencyTime" 40;
BA_DEF_DEF_  "GwSigMissingSourceType" "Undef";
BA_DEF_DEF_  "SignalCategory" 12;
BA_DEF_DEF_  "GenSigSendType" "NoSigSendType";
BA_DEF_DEF_  "GenMsgDelayTime" 20;
BA_DEF_DEF_  "NmMessage" "No";
BA_DEF_DEF_  "GenMsgILSupport" "Yes";
BA_DEF_DEF_  "GenMsgNrOfRepetition" 3;
BA_DEF_DEF_  "GenMsgCycleTimeFast" 60;
BA_DEF_DEF_  "GenMsgStartDelayTime" 0;
BA_DEF_DEF_  "GenMsgSendType" "NoMsgSendType";
BA_DEF_DEF_  "GenMsgCycleTime" 200;
BA_DEF_DEF_REL_ "GenSigTimeoutTime" 700;
BA_ "GenMsgStartDelayTime" BO_ 392 40;
BA_ "GenMsgCycleTimeFast" BO_ 392 40;
BA_ "GenMsgSendType" BO_ 392 0;
BA_ "GenMsgStartDelayTime" BO_ 393 60;
BA_ "GenMsgCycleTimeFast" BO_ 393 40;
BA_ "GenMsgSendType" BO_ 393 0;
BA_ "GenMsgStartDelayTime" BO_ 394 80;
BA_ "GenMsgCycleTimeFast" BO_ 394 40;
BA_ "GenMsgSendType" BO_ 394 0;
BA_ "GenMsgStartDelayTime" BO_ 395 100;
BA_ "GenMsgCycleTimeFast" BO_ 395 40;
BA_ "GenMsgSendType" BO_ 395 0;
BA_ "GenMsgStartDelayTime" BO_ 396 120;
BA_ "GenMsgCycleTimeFast" BO_ 396 40;
BA_ "GenMsgSendType" BO_ 396 0;
BA_ "GenMsgCycleTimeFast" BO_ 397 40;
BA_ "GenMsgCycleTime" BO_ 397 0;
BA_ "GenMsgCycleTimeFast" BO_ 398 40;
BA_ "GenMsgCycleTime" BO_ 398 0;
BA_ "GenMsgCycleTimeFast" BO_ 399 40;
BA_ "GenMsgCycleTime" BO_ 399 0;
BA_ "GenMsgCycleTimeFast" BO_ 400 40;
BA_ "GenMsgSendType" BO_ 400 0;
BA_ "GenMsgStartDelayTime" BO_ 401 20;
BA_ "GenMsgNrOfRepetition" BO_ 401 0;
BA_ "GenMsgCycleTimeFast" BO_ 401 0;
BA_ "GenMsgSendType" BO_ 401 0;
BA_ "GenMsgCycleTimeFast" BO_ 405 40;
BA_ "GenMsgSendType" BO_ 405 0;
BA_ "GenMsgStartDelayTime" BO_ 406 20;
BA_ "GenMsgNrOfRepetition" BO_ 406 0;
BA_ "GenMsgCycleTimeFast" BO_ 406 0;
BA_ "GenMsgSendType" BO_ 406 0;
BA_ "GenMsgCycleTimeFast" BO_ 410 40;
BA_ "GenMsgSendType" BO_ 410 0;
BA_ "GenMsgStartDelayTime" BO_ 411 20;
BA_ "GenMsgNrOfRepetition" BO_ 411 0;
BA_ "GenMsgCycleTimeFast" BO_ 411 0;
BA_ "GenMsgSendType" BO_ 411 0;
BA_ "GenMsgCycleTimeFast" BO_ 418 40;
BA_ "GenMsgCycleTime" BO_ 418 0;
BA_ "GenMsgCycleTimeFast" BO_ 450 40;
BA_ "GenMsgCycleTime" BO_ 450 0;
BA_ "GenMsgCycleTimeFast" BO_ 451 40;
BA_ "GenMsgCycleTime" BO_ 451 0;
BA_ "GenMsgCycleTimeFast" BO_ 452 40;
BA_ "GenMsgCycleTime" BO_ 452 0;
BA_ "GenMsgCycleTimeFast" BO_ 453 40;
BA_ "GenMsgCycleTime" BO_ 453 0;
BA_ "GenMsgCycleTimeFast" BO_ 454 40;
BA_ "GenMsgCycleTime" BO_ 454 0;
BA_ "GenMsgCycleTimeFast" BO_ 455 40;
BA_ "GenMsgCycleTime" BO_ 455 0;
BA_ "GenMsgCycleTimeFast" BO_ 482 40;
BA_ "GenMsgCycleTime" BO_ 482 0;
BA_ "GenMsgCycleTimeFast" BO_ 483 40;
BA_ "GenMsgCycleTime" BO_ 483 0;
BA_ "GenMsgCycleTimeFast" BO_ 484 40;
BA_ "GenMsgCycleTime" BO_ 484 0;
BA_ "GenMsgCycleTimeFast" BO_ 485 40;
BA_ "GenMsgCycleTime" BO_ 485 0;
BA_ "GenMsgCycleTimeFast" BO_ 486 40;
BA_ "GenMsgCycleTime" BO_ 486 0;
BA_ "GenMsgCycleTimeFast" BO_ 487 40;
BA_ "GenMsgCycleTime" BO_ 487 0;
BA_ "GenMsgCycleTimeFast" BO_ 498 40;
BA_ "GenMsgCycleTime" BO_ 498 0;
BA_ "GenMsgCycleTimeFast" BO_ 499 40;
BA_ "GenMsgCycleTime" BO_ 499 0;
BA_ "GenMsgCycleTimeFast" BO_ 500 40;
BA_ "GenMsgCycleTime" BO_ 500 0;
BA_ "GenMsgCycleTimeFast" BO_ 501 40;
BA_ "GenMsgCycleTime" BO_ 501 0;
BA_ "GenMsgCycleTimeFast" BO_ 502 40;
BA_ "GenMsgCycleTime" BO_ 502 0;
BA_ "GenMsgCycleTimeFast" BO_ 503 40;
BA_ "GenMsgCycleTime" BO_ 503 0;
BA_ "GenMsgCycleTimeFast" BO_ 768 40;
BA_ "GenMsgCycleTimeFast" BO_ 770 40;
BA_ "GenMsgCycleTimeFast" BO_ 772 40;
BA_ "GenMsgCycleTimeFast" BO_ 778 40;
BA_ "GenMsgCycleTimeFast" BO_ 780 40;
BA_ "GenMsgCycleTimeFast" BO_ 784 40;
BA_ "GenMsgCycleTimeFast" BO_ 786 40;
BA_ "GenMsgCycleTimeFast" BO_ 792 40;
BA_ "GenMsgCycleTimeFast" BO_ 800 40;
BA_ "GenMsgCycleTime" BO_ 800 0;
BA_ "GenMsgCycleTimeFast" BO_ 816 40;
BA_ "GenMsgCycleTime" BO_ 816 0;
BA_ "GenMsgCycleTimeFast" BO_ 832 40;
BA_ "GenMsgCycleTime" BO_ 832 0;
BA_ "GenMsgCycleTimeFast" BO_ 864 40;
BA_ "GenMsgCycleTime" BO_ 864 0;
BA_ "GenMsgCycleTimeFast" BO_ 865 40;
BA_ "GenMsgCycleTime" BO_ 865 0;
BA_ "GenMsgCycleTimeFast" BO_ 870 40;
BA_ "GenMsgCycleTime" BO_ 870 0;
BA_ "GenMsgCycleTimeFast" BO_ 871 40;
BA_ "GenMsgCycleTime" BO_ 871 0;
BA_ "GenMsgCycleTimeFast" BO_ 872 40;
BA_ "GenMsgCycleTime" BO_ 872 0;
BA_ "GenMsgCycleTimeFast" BO_ 873 40;
BA_ "GenMsgCycleTime" BO_ 873 0;
BA_ "GenMsgCycleTimeFast" BO_ 874 40;
BA_ "GenMsgCycleTime" BO_ 874 0;
BA_ "GenMsgCycleTimeFast" BO_ 877 40;
BA_ "GenMsgCycleTime" BO_ 877 0;
BA_ "GenMsgCycleTimeFast" BO_ 884 40;
BA_ "GenMsgCycleTime" BO_ 884 0;
BA_ "GenMsgCycleTimeFast" BO_ 885 40;
BA_ "GenMsgCycleTime" BO_ 885 0;
BA_ "GenMsgCycleTimeFast" BO_ 888 40;
BA_ "GenMsgCycleTime" BO_ 888 0;
BA_ "GenMsgCycleTimeFast" BO_ 889 40;
BA_ "GenMsgCycleTime" BO_ 889 0;
BA_ "GenMsgCycleTimeFast" BO_ 896 40;
BA_ "GenMsgCycleTime" BO_ 896 0;
BA_ "NWM-Botschaft" BO_ 1024 1;
BA_ "GenMsgCycleTimeFast" BO_ 1024 40;
BA_ "GenMsgILSupport" BO_ 1024 0;
BA_ "NmMessage" BO_ 1024 1;
BA_ "NWM-Botschaft" BO_ 1054 1;
BA_ "GenMsgCycleTimeFast" BO_ 1054 40;
BA_ "GenMsgILSupport" BO_ 1054 0;
BA_ "NmMessage" BO_ 1054 1;
BA_ "NWM-Botschaft" BO_ 1097 1;
BA_ "GenMsgCycleTimeFast" BO_ 1097 40;
BA_ "GenMsgILSupport" BO_ 1097 0;
BA_ "NmMessage" BO_ 1097 1;
BA_ "NWM-Botschaft" BO_ 1120 1;
BA_ "GenMsgCycleTimeFast" BO_ 1120 40;
BA_ "GenMsgILSupport" BO_ 1120 0;
BA_ "NmMessage" BO_ 1120 1;
BA_ "NWM-Botschaft" BO_ 1121 1;
BA_ "GenMsgCycleTimeFast" BO_ 1121 40;
BA_ "GenMsgILSupport" BO_ 1121 0;
BA_ "NmMessage" BO_ 1121 1;
BA_ "NWM-Botschaft" BO_ 1123 1;
BA_ "GenMsgCycleTimeFast" BO_ 1123 40;
BA_ "GenMsgILSupport" BO_ 1123 0;
BA_ "NmMessage" BO_ 1123 1;
BA_ "NWM-Botschaft" BO_ 1126 1;
BA_ "GenMsgCycleTimeFast" BO_ 1126 40;
BA_ "GenMsgILSupport" BO_ 1126 0;
BA_ "NmMessage" BO_ 1126 1;
BA_ "NWM-Botschaft" BO_ 1127 1;
BA_ "GenMsgCycleTimeFast" BO_ 1127 40;
BA_ "GenMsgILSupport" BO_ 1127 0;
BA_ "NmMessage" BO_ 1127 1;
BA_ "NWM-Botschaft" BO_ 1128 1;
BA_ "GenMsgCycleTimeFast" BO_ 1128 40;
BA_ "GenMsgILSupport" BO_ 1128 0;
BA_ "NmMessage" BO_ 1128 1;
BA_ "NWM-Botschaft" BO_ 1129 1;
BA_ "GenMsgCycleTimeFast" BO_ 1129 40;
BA_ "GenMsgILSupport" BO_ 1129 0;
BA_ "NmMessage" BO_ 1129 1;
BA_ "NWM-Botschaft" BO_ 1133 1;
BA_ "GenMsgCycleTimeFast" BO_ 1133 40;
BA_ "GenMsgILSupport" BO_ 1133 0;
BA_ "NmMessage" BO_ 1133 1;
BA_ "NWM-Botschaft" BO_ 1134 1;
BA_ "GenMsgCycleTimeFast" BO_ 1134 40;
BA_ "GenMsgILSupport" BO_ 1134 0;
BA_ "NmMessage" BO_ 1134 1;
BA_ "NWM-Botschaft" BO_ 1140 1;
BA_ "GenMsgCycleTimeFast" BO_ 1140 40;
BA_ "GenMsgILSupport" BO_ 1140 0;
BA_ "NmMessage" BO_ 1140 1;
BA_ "NWM-Botschaft" BO_ 1141 1;
BA_ "GenMsgCycleTimeFast" BO_ 1141 40;
BA_ "GenMsgILSupport" BO_ 1141 0;
BA_ "NmMessage" BO_ 1141 1;
BA_ "GenMsgCycleTimeFast" BO_ 1410 40;
BA_ "GenMsgCycleTime" BO_ 1410 0;
BA_ "GenMsgCycleTimeFast" BO_ 1418 40;
BA_ "GenMsgCycleTime" BO_ 1418 0;
BA_ "GenMsgCycleTimeFast" BO_ 1504 40;
BA_ "GenMsgCycleTime" BO_ 1504 0;
BA_ "GenMsgCycleTimeFast" BO_ 1512 40;
BA_ "GenMsgCycleTime" BO_ 1512 0;
BA_ "GenMsgCycleTimeFast" BO_ 1794 40;
BA_ "GenMsgCycleTime" BO_ 1794 0;
BA_ "GenMsgCycleTimeFast" BO_ 1802 40;
BA_ "GenMsgCycleTime" BO_ 1802 0;
BA_ "GenMsgCycleTimeFast" BO_ 1813 40;
BA_ "GenMsgCycleTime" BO_ 1813 0;
BA_ "GenMsgCycleTimeFast" BO_ 1821 40;
BA_ "GenMsgCycleTime" BO_ 1821 0;
BA_ "GenMsgCycleTimeFast" BO_ 2015 40;
BA_ "GenMsgCycleTime" BO_ 2015 0;
BA_ "GenSigSendType" SG_ 392 C_UWB_MASTER_Status1 4;
BA_ "GenSigSendType" SG_ 392 C_UWB_MASTER_Status2 4;
BA_ "GenSigSendType" SG_ 392 C_UWB_MASTER_Status3 4;
BA_ "GenSigSendType" SG_ 392 C_UWB_MASTER_Status4 4;
BA_ "GenSigSendType" SG_ 392 C_UWB_MASTER_Status5 4;
BA_ "GenSigSendType" SG_ 392 C_UWB_MASTER_Status6 4;
BA_ "GenSigSendType" SG_ 392 C_UWB_MASTER_Status7 4;
BA_ "GenSigSendType" SG_ 392 C_UWB_MASTER_Status8 4;
BA_ "GenSigSendType" SG_ 392 C_UWB_MASTER_Option 4;
BA_ "GenSigSendType" SG_ 393 C_UWB_Master_DK_ConnStat 4;
BA_ "GenSigSendType" SG_ 393 C_UWB_Mst_DK_LocalizationStat 4;
BA_ "GenSigSendType" SG_ 394 C_UWB_Mst_EncryptedResult1Val 4;
BA_ "GenSigSendType" SG_ 395 C_UWB_Mst_EncryptedResult2Val 4;
BA_ "GenSigSendType" SG_ 396 C_UWB_Master2BDC_RndNum 4;
BA_ "GenSigSendType" SG_ 397 C_UWB_Master_LocalRN_Target 4;
BA_ "GenSigSendType" SG_ 397 C_UWB_Master_LocalRN_TRCode 4;
BA_ "GenSigSendType" SG_ 397 C_UWB_Master_LocalRN_CMD 4;
BA_ "GenSigSendType" SG_ 397 C_UWB_Master_LocalRndNum 4;
BA_ "GenSigSendType" SG_ 398 UWB_Master_ToUWBEncryptData1 4;
BA_ "GenSigSendType" SG_ 399 UWB_Master_ToUWBEncryptData2 4;
BA_ "GenSigSendType" SG_ 400 C_UWB_RL_Status1 4;
BA_ "GenSigSendType" SG_ 400 C_UWB_RL_Status2 4;
BA_ "GenSigSendType" SG_ 400 C_UWB_RL_Status3 4;
BA_ "GenSigSendType" SG_ 400 C_UWB_RL_Status4 4;
BA_ "GenSigSendType" SG_ 400 C_UWB_RL_Status5 4;
BA_ "GenSigSendType" SG_ 400 C_UWB_RL_Status6 4;
BA_ "GenSigSendType" SG_ 400 C_UWB_RL_Status7 4;
BA_ "GenSigSendType" SG_ 400 C_UWB_RL_Status8 4;
BA_ "GenSigSendType" SG_ 400 C_UWB_RL_DTC 4;
BA_ "GenSigSendType" SG_ 400 C_UWB_RL_Option 4;
BA_ "GenSigSendType" SG_ 405 C_UWB_RR_Status1 4;
BA_ "GenSigSendType" SG_ 405 C_UWB_RR_Status2 4;
BA_ "GenSigSendType" SG_ 405 C_UWB_RR_Status3 4;
BA_ "GenSigSendType" SG_ 405 C_UWB_RR_Status4 4;
BA_ "GenSigSendType" SG_ 405 C_UWB_RR_Status5 4;
BA_ "GenSigSendType" SG_ 405 C_UWB_RR_Status6 4;
BA_ "GenSigSendType" SG_ 405 C_UWB_RR_Status7 4;
BA_ "GenSigSendType" SG_ 405 C_UWB_RR_Status8 4;
BA_ "GenSigSendType" SG_ 405 C_UWB_RR_DTC 4;
BA_ "GenSigSendType" SG_ 405 C_UWB_RR_Option 4;
BA_ "GenSigSendType" SG_ 410 C_UWB_TRUNK_Status1 4;
BA_ "GenSigSendType" SG_ 410 C_UWB_TRUNK_Status2 4;
BA_ "GenSigSendType" SG_ 410 C_UWB_TRUNK_Status3 4;
BA_ "GenSigSendType" SG_ 410 C_UWB_TRUNK_Status4 4;
BA_ "GenSigSendType" SG_ 410 C_UWB_TRUNK_Status5 4;
BA_ "GenSigSendType" SG_ 410 C_UWB_TRUNK_Status6 4;
BA_ "GenSigSendType" SG_ 410 C_UWB_TRUNK_Status7 4;
BA_ "GenSigSendType" SG_ 410 C_UWB_TRUNK_Status8 4;
BA_ "GenSigSendType" SG_ 410 C_UWB_TRNK_DTC 4;
BA_ "GenSigSendType" SG_ 410 C_UWB_TRUNK_Option 4;
BA_ "GenSigSendType" SG_ 452 C_UWB_RL_To_BDCFOBRSDResult 4;
BA_ "GenSigSendType" SG_ 453 C_UWB_RL_MCU_Bootloader 4;
BA_ "GenSigSendType" SG_ 453 C_UWB_RL_MCU_Flash_Erase 4;
BA_ "GenSigSendType" SG_ 453 C_UWB_RL_MCU_CRC32 4;
BA_ "GenSigSendType" SG_ 454 C_UWB_RL_IC_Bootloader 4;
BA_ "GenSigSendType" SG_ 454 C_UWB_RL_IC_Flash_Erase 4;
BA_ "GenSigSendType" SG_ 454 C_UWB_RL_IC_CRC32 4;
BA_ "GenSigSendType" SG_ 455 C_UWB_RL_Decrypt_FB 4;
BA_ "GenSigSendType" SG_ 484 C_UWB_RR_To_BDCFOBRSDResult 4;
BA_ "GenSigSendType" SG_ 485 C_UWB_RR_MCU_Bootloader 4;
BA_ "GenSigSendType" SG_ 485 C_UWB_RR_MCU_Flash_Erase 4;
BA_ "GenSigSendType" SG_ 485 C_UWB_RR_MCU_CRC32 4;
BA_ "GenSigSendType" SG_ 486 C_UWB_RR_IC_Bootloader 4;
BA_ "GenSigSendType" SG_ 486 C_UWB_RR_IC_Flash_Erase 4;
BA_ "GenSigSendType" SG_ 486 C_UWB_RR_IC_CRC32 4;
BA_ "GenSigSendType" SG_ 487 C_UWB_RR_Decrypt_FB 4;
BA_ "GenSigSendType" SG_ 500 C_UWB_TRNK_To_BDCFOBRSDResult 4;
BA_ "GenSigSendType" SG_ 501 C_UWB_TRNK_MCU_Bootloader 4;
BA_ "GenSigSendType" SG_ 501 C_UWB_TRNK_MCU_Flash_Erase 4;
BA_ "GenSigSendType" SG_ 501 C_UWB_TRNK_MCU_CRC32 4;
BA_ "GenSigSendType" SG_ 502 C_UWB_TRNK_IC_Bootloader 4;
BA_ "GenSigSendType" SG_ 502 C_UWB_TRNK_IC_Flash_Erase 4;
BA_ "GenSigSendType" SG_ 502 C_UWB_TRNK_IC_CRC32 4;
BA_ "GenSigSendType" SG_ 503 C_UWB_TRNK_Decrypt_FB 4;
BA_ "GenSigSendType" SG_ 792 C_WPCBDCTpByte0Data 1;
BA_ "GenSigSendType" SG_ 792 C_WPCBDCTpByte1Data 1;
BA_ "GenSigSendType" SG_ 792 C_WPCBDCTpByte2Data 1;
BA_ "GenSigSendType" SG_ 792 C_WPCBDCTpByte3Data 1;
BA_ "GenSigSendType" SG_ 792 C_WPCBDCTpByte4Data 1;
BA_ "GenSigSendType" SG_ 792 C_WPCBDCTpByte5Data 1;
BA_ "GenSigSendType" SG_ 792 C_WPCBDCTpByte6Data 1;
BA_ "GenSigSendType" SG_ 792 C_WPCBDCTpByte7Data 1;
BA_ "GenSigSendType" SG_ 800 DevToolBLEDvp1DataByte0 4;
BA_ "GenSigSendType" SG_ 800 DevToolBLEDvp1DataByte1 4;
BA_ "GenSigSendType" SG_ 800 DevToolBLEDvp1DataByte2 4;
BA_ "GenSigSendType" SG_ 800 DevToolBLEDvp1DataByte3 4;
BA_ "GenSigSendType" SG_ 800 DevToolBLEDvp1DataByte4 4;
BA_ "GenSigSendType" SG_ 800 DevToolBLEDvp1DataByte5 4;
BA_ "GenSigSendType" SG_ 800 DevToolBLEDvp1DataByte6 4;
BA_ "GenSigSendType" SG_ 800 DevToolBLEDvp1DataByte7 4;
BA_ "GenSigSendType" SG_ 816 DevToolDHDvp1DataByte0 4;
BA_ "GenSigSendType" SG_ 816 DevToolDHDvp1DataByte1 4;
BA_ "GenSigSendType" SG_ 816 DevToolDHDvp1DataByte2 4;
BA_ "GenSigSendType" SG_ 816 DevToolDHDvp1DataByte3 4;
BA_ "GenSigSendType" SG_ 816 DevToolDHDvp1DataByte4 4;
BA_ "GenSigSendType" SG_ 816 DevToolDHDvp1DataByte5 4;
BA_ "GenSigSendType" SG_ 816 DevToolDHDvp1DataByte6 4;
BA_ "GenSigSendType" SG_ 816 DevToolDHDvp1DataByte7 4;
BA_ "GenSigSendType" SG_ 832 DevToolUWBDvp1DataByte0 4;
BA_ "GenSigSendType" SG_ 832 DevToolUWBDvp1DataByte1 4;
BA_ "GenSigSendType" SG_ 832 DevToolUWBDvp1DataByte2 4;
BA_ "GenSigSendType" SG_ 832 DevToolUWBDvp1DataByte3 4;
BA_ "GenSigSendType" SG_ 832 DevToolUWBDvp1DataByte4 4;
BA_ "GenSigSendType" SG_ 832 DevToolUWBDvp1DataByte5 4;
BA_ "GenSigSendType" SG_ 832 DevToolUWBDvp1DataByte6 4;
BA_ "GenSigSendType" SG_ 832 DevToolUWBDvp1DataByte7 4;
BA_ "GenSigSendType" SG_ 864 DHLDvp1DataByte0 4;
BA_ "GenSigSendType" SG_ 864 DHLDvp1DataByte1 4;
BA_ "GenSigSendType" SG_ 864 DHLDvp1DataByte2 4;
BA_ "GenSigSendType" SG_ 864 DHLDvp1DataByte3 4;
BA_ "GenSigSendType" SG_ 864 DHLDvp1DataByte4 4;
BA_ "GenSigSendType" SG_ 864 DHLDvp1DataByte5 4;
BA_ "GenSigSendType" SG_ 864 DHLDvp1DataByte6 4;
BA_ "GenSigSendType" SG_ 864 DHLDvp1DataByte7 4;
BA_ "GenSigSendType" SG_ 865 DHRDvp1DataByte0 4;
BA_ "GenSigSendType" SG_ 865 DHRDvp1DataByte1 4;
BA_ "GenSigSendType" SG_ 865 DHRDvp1DataByte2 4;
BA_ "GenSigSendType" SG_ 865 DHRDvp1DataByte3 4;
BA_ "GenSigSendType" SG_ 865 DHRDvp1DataByte4 4;
BA_ "GenSigSendType" SG_ 865 DHRDvp1DataByte5 4;
BA_ "GenSigSendType" SG_ 865 DHRDvp1DataByte6 4;
BA_ "GenSigSendType" SG_ 865 DHRDvp1DataByte7 4;
BA_ "GenSigSendType" SG_ 870 UWBFRDvp1DataByte0 4;
BA_ "GenSigSendType" SG_ 870 UWBFRDvp1DataByte1 4;
BA_ "GenSigSendType" SG_ 870 UWBFRDvp1DataByte2 4;
BA_ "GenSigSendType" SG_ 870 UWBFRDvp1DataByte3 4;
BA_ "GenSigSendType" SG_ 870 UWBFRDvp1DataByte4 4;
BA_ "GenSigSendType" SG_ 870 UWBFRDvp1DataByte5 4;
BA_ "GenSigSendType" SG_ 870 UWBFRDvp1DataByte6 4;
BA_ "GenSigSendType" SG_ 870 UWBFRDvp1DataByte7 4;
BA_ "GenSigSendType" SG_ 871 UWBFLDvp1DataByte0 4;
BA_ "GenSigSendType" SG_ 871 UWBFLDvp1DataByte1 4;
BA_ "GenSigSendType" SG_ 871 UWBFLDvp1DataByte2 4;
BA_ "GenSigSendType" SG_ 871 UWBFLDvp1DataByte3 4;
BA_ "GenSigSendType" SG_ 871 UWBFLDvp1DataByte4 4;
BA_ "GenSigSendType" SG_ 871 UWBFLDvp1DataByte5 4;
BA_ "GenSigSendType" SG_ 871 UWBFLDvp1DataByte6 4;
BA_ "GenSigSendType" SG_ 871 UWBFLDvp1DataByte7 4;
BA_ "GenSigSendType" SG_ 872 UWBRRDvp1DataByte0 4;
BA_ "GenSigSendType" SG_ 872 UWBRRDvp1DataByte1 4;
BA_ "GenSigSendType" SG_ 872 UWBRRDvp1DataByte2 4;
BA_ "GenSigSendType" SG_ 872 UWBRRDvp1DataByte3 4;
BA_ "GenSigSendType" SG_ 872 UWBRRDvp1DataByte4 4;
BA_ "GenSigSendType" SG_ 872 UWBRRDvp1DataByte5 4;
BA_ "GenSigSendType" SG_ 872 UWBRRDvp1DataByte6 4;
BA_ "GenSigSendType" SG_ 872 UWBRRDvp1DataByte7 4;
BA_ "GenSigSendType" SG_ 873 UWBRLDvp1DataByte0 4;
BA_ "GenSigSendType" SG_ 873 UWBRLDvp1DataByte1 4;
BA_ "GenSigSendType" SG_ 873 UWBRLDvp1DataByte2 4;
BA_ "GenSigSendType" SG_ 873 UWBRLDvp1DataByte3 4;
BA_ "GenSigSendType" SG_ 873 UWBRLDvp1DataByte4 4;
BA_ "GenSigSendType" SG_ 873 UWBRLDvp1DataByte5 4;
BA_ "GenSigSendType" SG_ 873 UWBRLDvp1DataByte6 4;
BA_ "GenSigSendType" SG_ 873 UWBRLDvp1DataByte7 4;
BA_ "GenSigSendType" SG_ 874 UWBFRNKDvp1DataByte0 4;
BA_ "GenSigSendType" SG_ 874 UWBFRNKDvp1DataByte1 4;
BA_ "GenSigSendType" SG_ 874 UWBFRNKDvp1DataByte2 4;
BA_ "GenSigSendType" SG_ 874 UWBFRNKDvp1DataByte3 4;
BA_ "GenSigSendType" SG_ 874 UWBFRNKDvp1DataByte4 4;
BA_ "GenSigSendType" SG_ 874 UWBFRNKDvp1DataByte5 4;
BA_ "GenSigSendType" SG_ 874 UWBFRNKDvp1DataByte6 4;
BA_ "GenSigSendType" SG_ 874 UWBFRNKDvp1DataByte7 4;
BA_ "GenSigSendType" SG_ 877 UWBTRNKDvp1DataByte0 4;
BA_ "GenSigSendType" SG_ 877 UWBTRNKDvp1DataByte1 4;
BA_ "GenSigSendType" SG_ 877 UWBTRNKDvp1DataByte2 4;
BA_ "GenSigSendType" SG_ 877 UWBTRNKDvp1DataByte3 4;
BA_ "GenSigSendType" SG_ 877 UWBTRNKDvp1DataByte4 4;
BA_ "GenSigSendType" SG_ 877 UWBTRNKDvp1DataByte5 4;
BA_ "GenSigSendType" SG_ 877 UWBTRNKDvp1DataByte6 4;
BA_ "GenSigSendType" SG_ 877 UWBTRNKDvp1DataByte7 4;
BA_ "GenSigSendType" SG_ 884 UWB_BLEDvp1DataByte0 4;
BA_ "GenSigSendType" SG_ 884 UWB_BLEDvp1DataByte1 4;
BA_ "GenSigSendType" SG_ 884 UWB_BLEDvp1DataByte2 4;
BA_ "GenSigSendType" SG_ 884 UWB_BLEDvp1DataByte3 4;
BA_ "GenSigSendType" SG_ 884 UWB_BLEDvp1DataByte4 4;
BA_ "GenSigSendType" SG_ 884 UWB_BLEDvp1DataByte5 4;
BA_ "GenSigSendType" SG_ 884 UWB_BLEDvp1DataByte6 4;
BA_ "GenSigSendType" SG_ 884 UWB_BLEDvp1DataByte7 4;
BA_ "GenSigSendType" SG_ 885 UWBINTDvp1DataByte0 4;
BA_ "GenSigSendType" SG_ 885 UWBINTDvp1DataByte1 4;
BA_ "GenSigSendType" SG_ 885 UWBINTDvp1DataByte2 4;
BA_ "GenSigSendType" SG_ 885 UWBINTDvp1DataByte3 4;
BA_ "GenSigSendType" SG_ 885 UWBINTDvp1DataByte4 4;
BA_ "GenSigSendType" SG_ 885 UWBINTDvp1DataByte5 4;
BA_ "GenSigSendType" SG_ 885 UWBINTDvp1DataByte6 4;
BA_ "GenSigSendType" SG_ 885 UWBINTDvp1DataByte7 4;
BA_ "GenSigSendType" SG_ 888 UWB_BLE_Dvp2Data 4;
BA_ "GenSigSendType" SG_ 889 UWB_BLE_Dvp3Data 4;
BA_ "GenSigSendType" SG_ 896 UWB_BLE_Dvp4Data 4;
BA_ "GenSigSendType" SG_ 1410 GstBDCUWB_BLEDataByte7 2;
BA_ "GenSigSendType" SG_ 1418 UWB_BLEBDCGstDataByte7 2;
BA_ "GenSigSendType" SG_ 1504 GstBDCROADataByte7 2;
BA_ "GenSigSendType" SG_ 1512 ROABDCGstDataByte7 2;
BA_ "GenSigSendType" SG_ 1794 GstBDCDHLDataByte7 2;
BA_ "GenSigSendType" SG_ 1802 DHLBDCGstDataByte7 2;
BA_ "GenSigSendType" SG_ 1813 GstBDCDHRDataByte7 2;
BA_ "GenSigSendType" SG_ 1821 DHRBDCGstDataByte7 2;
BA_ "GenSigSendType" SG_ 2015 GstALLByte7Data 2;
BA_REL_ "GenSigTimeoutTime" BU_SG_REL_ BDC SG_ 392 C_UWB_MASTER_Status1 0;
BA_REL_ "GenSigTimeoutTime" BU_SG_REL_ BDC SG_ 392 C_UWB_MASTER_Status2 0;
BA_REL_ "GenSigTimeoutTime" BU_SG_REL_ BDC SG_ 392 C_UWB_MASTER_Status3 0;
BA_REL_ "GenSigTimeoutTime" BU_SG_REL_ BDC SG_ 392 C_UWB_MASTER_Status4 0;
BA_REL_ "GenSigTimeoutTime" BU_SG_REL_ BDC SG_ 392 C_UWB_MASTER_Status5 0;
BA_REL_ "GenSigTimeoutTime" BU_SG_REL_ BDC SG_ 392 C_UWB_MASTER_Status6 0;
BA_REL_ "GenSigTimeoutTime" BU_SG_REL_ BDC SG_ 392 C_UWB_MASTER_Status7 0;
BA_REL_ "GenSigTimeoutTime" BU_SG_REL_ BDC SG_ 392 C_UWB_MASTER_Status8 0;
BA_REL_ "GenSigTimeoutTime" BU_SG_REL_ BDC SG_ 392 C_UWB_MASTER_Option 0;
BA_REL_ "GenSigTimeoutTime" BU_SG_REL_ BDC SG_ 393 C_UWB_Master_DK_ConnStat 0;
BA_REL_ "GenSigTimeoutTime" BU_SG_REL_ BDC SG_ 393 C_UWB_Mst_DK_LocalizationStat 0;
BA_REL_ "GenSigTimeoutTime" BU_SG_REL_ BDC SG_ 394 C_UWB_Mst_EncryptedResult1Val 0;
BA_REL_ "GenSigTimeoutTime" BU_SG_REL_ BDC SG_ 395 C_UWB_Mst_EncryptedResult2Val 0;
BA_REL_ "GenSigTimeoutTime" BU_SG_REL_ BDC SG_ 396 C_UWB_Master2BDC_RndNum 0;
BA_REL_ "GenSigTimeoutTime" BU_SG_REL_ UWB_FL SG_ 397 C_UWB_Master_LocalRN_Target 0;
BA_REL_ "GenSigTimeoutTime" BU_SG_REL_ UWB_FR SG_ 397 C_UWB_Master_LocalRN_Target 0;
BA_REL_ "GenSigTimeoutTime" BU_SG_REL_ UWB_FRNK SG_ 397 C_UWB_Master_LocalRN_Target 0;
BA_REL_ "GenSigTimeoutTime" BU_SG_REL_ UWB_INT SG_ 397 C_UWB_Master_LocalRN_Target 0;
BA_REL_ "GenSigTimeoutTime" BU_SG_REL_ UWB_RL SG_ 397 C_UWB_Master_LocalRN_Target 0;
BA_REL_ "GenSigTimeoutTime" BU_SG_REL_ UWB_RR SG_ 397 C_UWB_Master_LocalRN_Target 0;
BA_REL_ "GenSigTimeoutTime" BU_SG_REL_ UWB_TRNK SG_ 397 C_UWB_Master_LocalRN_Target 0;
BA_REL_ "GenSigTimeoutTime" BU_SG_REL_ UWB_FL SG_ 397 C_UWB_Master_LocalRN_TRCode 0;
BA_REL_ "GenSigTimeoutTime" BU_SG_REL_ UWB_FR SG_ 397 C_UWB_Master_LocalRN_TRCode 0;
BA_REL_ "GenSigTimeoutTime" BU_SG_REL_ UWB_FRNK SG_ 397 C_UWB_Master_LocalRN_TRCode 0;
BA_REL_ "GenSigTimeoutTime" BU_SG_REL_ UWB_INT SG_ 397 C_UWB_Master_LocalRN_TRCode 0;
BA_REL_ "GenSigTimeoutTime" BU_SG_REL_ UWB_RL SG_ 397 C_UWB_Master_LocalRN_TRCode 0;
BA_REL_ "GenSigTimeoutTime" BU_SG_REL_ UWB_RR SG_ 397 C_UWB_Master_LocalRN_TRCode 0;
BA_REL_ "GenSigTimeoutTime" BU_SG_REL_ UWB_TRNK SG_ 397 C_UWB_Master_LocalRN_TRCode 0;
BA_REL_ "GenSigTimeoutTime" BU_SG_REL_ UWB_FL SG_ 397 C_UWB_Master_LocalRN_CMD 0;
BA_REL_ "GenSigTimeoutTime" BU_SG_REL_ UWB_FR SG_ 397 C_UWB_Master_LocalRN_CMD 0;
BA_REL_ "GenSigTimeoutTime" BU_SG_REL_ UWB_FRNK SG_ 397 C_UWB_Master_LocalRN_CMD 0;
BA_REL_ "GenSigTimeoutTime" BU_SG_REL_ UWB_INT SG_ 397 C_UWB_Master_LocalRN_CMD 0;
BA_REL_ "GenSigTimeoutTime" BU_SG_REL_ UWB_RL SG_ 397 C_UWB_Master_LocalRN_CMD 0;
BA_REL_ "GenSigTimeoutTime" BU_SG_REL_ UWB_RR SG_ 397 C_UWB_Master_LocalRN_CMD 0;
BA_REL_ "GenSigTimeoutTime" BU_SG_REL_ UWB_TRNK SG_ 397 C_UWB_Master_LocalRN_CMD 0;
BA_REL_ "GenSigTimeoutTime" BU_SG_REL_ UWB_FL SG_ 397 C_UWB_Master_LocalRndNum 0;
BA_REL_ "GenSigTimeoutTime" BU_SG_REL_ UWB_FR SG_ 397 C_UWB_Master_LocalRndNum 0;
BA_REL_ "GenSigTimeoutTime" BU_SG_REL_ UWB_FRNK SG_ 397 C_UWB_Master_LocalRndNum 0;
BA_REL_ "GenSigTimeoutTime" BU_SG_REL_ UWB_INT SG_ 397 C_UWB_Master_LocalRndNum 0;
BA_REL_ "GenSigTimeoutTime" BU_SG_REL_ UWB_RL SG_ 397 C_UWB_Master_LocalRndNum 0;
BA_REL_ "GenSigTimeoutTime" BU_SG_REL_ UWB_RR SG_ 397 C_UWB_Master_LocalRndNum 0;
BA_REL_ "GenSigTimeoutTime" BU_SG_REL_ UWB_TRNK SG_ 397 C_UWB_Master_LocalRndNum 0;
BA_REL_ "GenSigTimeoutTime" BU_SG_REL_ UWB_FL SG_ 398 UWB_Master_ToUWBEncryptData1 0;
BA_REL_ "GenSigTimeoutTime" BU_SG_REL_ UWB_FR SG_ 398 UWB_Master_ToUWBEncryptData1 0;
BA_REL_ "GenSigTimeoutTime" BU_SG_REL_ UWB_FRNK SG_ 398 UWB_Master_ToUWBEncryptData1 0;
BA_REL_ "GenSigTimeoutTime" BU_SG_REL_ UWB_INT SG_ 398 UWB_Master_ToUWBEncryptData1 0;
BA_REL_ "GenSigTimeoutTime" BU_SG_REL_ UWB_RL SG_ 398 UWB_Master_ToUWBEncryptData1 0;
BA_REL_ "GenSigTimeoutTime" BU_SG_REL_ UWB_RR SG_ 398 UWB_Master_ToUWBEncryptData1 0;
BA_REL_ "GenSigTimeoutTime" BU_SG_REL_ UWB_TRNK SG_ 398 UWB_Master_ToUWBEncryptData1 0;
BA_REL_ "GenSigTimeoutTime" BU_SG_REL_ UWB_FL SG_ 399 UWB_Master_ToUWBEncryptData2 0;
BA_REL_ "GenSigTimeoutTime" BU_SG_REL_ UWB_FR SG_ 399 UWB_Master_ToUWBEncryptData2 0;
BA_REL_ "GenSigTimeoutTime" BU_SG_REL_ UWB_FRNK SG_ 399 UWB_Master_ToUWBEncryptData2 0;
BA_REL_ "GenSigTimeoutTime" BU_SG_REL_ UWB_INT SG_ 399 UWB_Master_ToUWBEncryptData2 0;
BA_REL_ "GenSigTimeoutTime" BU_SG_REL_ UWB_RL SG_ 399 UWB_Master_ToUWBEncryptData2 0;
BA_REL_ "GenSigTimeoutTime" BU_SG_REL_ UWB_RR SG_ 399 UWB_Master_ToUWBEncryptData2 0;
BA_REL_ "GenSigTimeoutTime" BU_SG_REL_ UWB_TRNK SG_ 399 UWB_Master_ToUWBEncryptData2 0;
BA_REL_ "GenSigTimeoutTime" BU_SG_REL_ BDC SG_ 400 C_UWB_RL_Status1 0;
BA_REL_ "GenSigTimeoutTime" BU_SG_REL_ UWB_BLE SG_ 400 C_UWB_RL_Status1 0;
BA_REL_ "GenSigTimeoutTime" BU_SG_REL_ BDC SG_ 400 C_UWB_RL_Status2 0;
BA_REL_ "GenSigTimeoutTime" BU_SG_REL_ UWB_BLE SG_ 400 C_UWB_RL_Status2 0;
BA_REL_ "GenSigTimeoutTime" BU_SG_REL_ BDC SG_ 400 C_UWB_RL_Status3 0;
BA_REL_ "GenSigTimeoutTime" BU_SG_REL_ UWB_BLE SG_ 400 C_UWB_RL_Status3 0;
BA_REL_ "GenSigTimeoutTime" BU_SG_REL_ BDC SG_ 400 C_UWB_RL_Status4 0;
BA_REL_ "GenSigTimeoutTime" BU_SG_REL_ UWB_BLE SG_ 400 C_UWB_RL_Status4 0;
BA_REL_ "GenSigTimeoutTime" BU_SG_REL_ BDC SG_ 400 C_UWB_RL_Status5 0;
BA_REL_ "GenSigTimeoutTime" BU_SG_REL_ UWB_BLE SG_ 400 C_UWB_RL_Status5 0;
BA_REL_ "GenSigTimeoutTime" BU_SG_REL_ BDC SG_ 400 C_UWB_RL_Status6 0;
BA_REL_ "GenSigTimeoutTime" BU_SG_REL_ UWB_BLE SG_ 400 C_UWB_RL_Status6 0;
BA_REL_ "GenSigTimeoutTime" BU_SG_REL_ BDC SG_ 400 C_UWB_RL_Status7 0;
BA_REL_ "GenSigTimeoutTime" BU_SG_REL_ UWB_BLE SG_ 400 C_UWB_RL_Status7 0;
BA_REL_ "GenSigTimeoutTime" BU_SG_REL_ BDC SG_ 400 C_UWB_RL_Status8 0;
BA_REL_ "GenSigTimeoutTime" BU_SG_REL_ UWB_BLE SG_ 400 C_UWB_RL_Status8 0;
BA_REL_ "GenSigTimeoutTime" BU_SG_REL_ UWB_BLE SG_ 400 C_UWB_RL_DTC 0;
BA_REL_ "GenSigTimeoutTime" BU_SG_REL_ BDC SG_ 400 C_UWB_RL_Option 0;
BA_REL_ "GenSigTimeoutTime" BU_SG_REL_ UWB_BLE SG_ 400 C_UWB_RL_Option 0;
BA_REL_ "GenSigTimeoutTime" BU_SG_REL_ UWB_BLE SG_ 401 C_UWB_RL_HW_Ver_Major 0;
BA_REL_ "GenSigTimeoutTime" BU_SG_REL_ UWB_BLE SG_ 401 C_UWB_RL_HW_Ver_Minor 0;
BA_REL_ "GenSigTimeoutTime" BU_SG_REL_ UWB_BLE SG_ 401 C_UWB_RL_SW_MCU_Ver_Major 0;
BA_REL_ "GenSigTimeoutTime" BU_SG_REL_ UWB_BLE SG_ 401 C_UWB_RL_SW_MCU_Ver_Minor 0;
BA_REL_ "GenSigTimeoutTime" BU_SG_REL_ UWB_BLE SG_ 401 C_UWB_RL_SW_IC_Ver_Major 0;
BA_REL_ "GenSigTimeoutTime" BU_SG_REL_ UWB_BLE SG_ 401 C_UWB_RL_SW_IC_Ver_Minor 0;
BA_REL_ "GenSigTimeoutTime" BU_SG_REL_ BDC SG_ 405 C_UWB_RR_Status1 0;
BA_REL_ "GenSigTimeoutTime" BU_SG_REL_ UWB_BLE SG_ 405 C_UWB_RR_Status1 0;
BA_REL_ "GenSigTimeoutTime" BU_SG_REL_ BDC SG_ 405 C_UWB_RR_Status2 0;
BA_REL_ "GenSigTimeoutTime" BU_SG_REL_ UWB_BLE SG_ 405 C_UWB_RR_Status2 0;
BA_REL_ "GenSigTimeoutTime" BU_SG_REL_ BDC SG_ 405 C_UWB_RR_Status3 0;
BA_REL_ "GenSigTimeoutTime" BU_SG_REL_ UWB_BLE SG_ 405 C_UWB_RR_Status3 0;
BA_REL_ "GenSigTimeoutTime" BU_SG_REL_ BDC SG_ 405 C_UWB_RR_Status4 0;
BA_REL_ "GenSigTimeoutTime" BU_SG_REL_ UWB_BLE SG_ 405 C_UWB_RR_Status4 0;
BA_REL_ "GenSigTimeoutTime" BU_SG_REL_ BDC SG_ 405 C_UWB_RR_Status5 0;
BA_REL_ "GenSigTimeoutTime" BU_SG_REL_ UWB_BLE SG_ 405 C_UWB_RR_Status5 0;
BA_REL_ "GenSigTimeoutTime" BU_SG_REL_ BDC SG_ 405 C_UWB_RR_Status6 0;
BA_REL_ "GenSigTimeoutTime" BU_SG_REL_ UWB_BLE SG_ 405 C_UWB_RR_Status6 0;
BA_REL_ "GenSigTimeoutTime" BU_SG_REL_ BDC SG_ 405 C_UWB_RR_Status7 0;
BA_REL_ "GenSigTimeoutTime" BU_SG_REL_ UWB_BLE SG_ 405 C_UWB_RR_Status7 0;
BA_REL_ "GenSigTimeoutTime" BU_SG_REL_ BDC SG_ 405 C_UWB_RR_Status8 0;
BA_REL_ "GenSigTimeoutTime" BU_SG_REL_ UWB_BLE SG_ 405 C_UWB_RR_Status8 0;
BA_REL_ "GenSigTimeoutTime" BU_SG_REL_ UWB_BLE SG_ 405 C_UWB_RR_DTC 0;
BA_REL_ "GenSigTimeoutTime" BU_SG_REL_ BDC SG_ 405 C_UWB_RR_Option 0;
BA_REL_ "GenSigTimeoutTime" BU_SG_REL_ UWB_BLE SG_ 405 C_UWB_RR_Option 0;
BA_REL_ "GenSigTimeoutTime" BU_SG_REL_ UWB_BLE SG_ 406 C_UWB_RR_HW_Ver_Major 0;
BA_REL_ "GenSigTimeoutTime" BU_SG_REL_ UWB_BLE SG_ 406 C_UWB_RR_HW_Ver_Minor 0;
BA_REL_ "GenSigTimeoutTime" BU_SG_REL_ UWB_BLE SG_ 406 C_UWB_RR_SW_MCU_Ver_Major 0;
BA_REL_ "GenSigTimeoutTime" BU_SG_REL_ UWB_BLE SG_ 406 C_UWB_RR_SW_MCU_Ver_Minor 0;
BA_REL_ "GenSigTimeoutTime" BU_SG_REL_ UWB_BLE SG_ 406 C_UWB_RR_SW_IC_Ver_Major 0;
BA_REL_ "GenSigTimeoutTime" BU_SG_REL_ UWB_BLE SG_ 406 C_UWB_RR_SW_IC_Ver_Minor 0;
BA_REL_ "GenSigTimeoutTime" BU_SG_REL_ BDC SG_ 410 C_UWB_TRUNK_Status1 0;
BA_REL_ "GenSigTimeoutTime" BU_SG_REL_ UWB_BLE SG_ 410 C_UWB_TRUNK_Status1 0;
BA_REL_ "GenSigTimeoutTime" BU_SG_REL_ BDC SG_ 410 C_UWB_TRUNK_Status2 0;
BA_REL_ "GenSigTimeoutTime" BU_SG_REL_ UWB_BLE SG_ 410 C_UWB_TRUNK_Status2 0;
BA_REL_ "GenSigTimeoutTime" BU_SG_REL_ BDC SG_ 410 C_UWB_TRUNK_Status3 0;
BA_REL_ "GenSigTimeoutTime" BU_SG_REL_ UWB_BLE SG_ 410 C_UWB_TRUNK_Status3 0;
BA_REL_ "GenSigTimeoutTime" BU_SG_REL_ BDC SG_ 410 C_UWB_TRUNK_Status4 0;
BA_REL_ "GenSigTimeoutTime" BU_SG_REL_ UWB_BLE SG_ 410 C_UWB_TRUNK_Status4 0;
BA_REL_ "GenSigTimeoutTime" BU_SG_REL_ BDC SG_ 410 C_UWB_TRUNK_Status5 0;
BA_REL_ "GenSigTimeoutTime" BU_SG_REL_ UWB_BLE SG_ 410 C_UWB_TRUNK_Status5 0;
BA_REL_ "GenSigTimeoutTime" BU_SG_REL_ BDC SG_ 410 C_UWB_TRUNK_Status6 0;
BA_REL_ "GenSigTimeoutTime" BU_SG_REL_ UWB_BLE SG_ 410 C_UWB_TRUNK_Status6 0;
BA_REL_ "GenSigTimeoutTime" BU_SG_REL_ BDC SG_ 410 C_UWB_TRUNK_Status7 0;
BA_REL_ "GenSigTimeoutTime" BU_SG_REL_ UWB_BLE SG_ 410 C_UWB_TRUNK_Status7 0;
BA_REL_ "GenSigTimeoutTime" BU_SG_REL_ BDC SG_ 410 C_UWB_TRUNK_Status8 0;
BA_REL_ "GenSigTimeoutTime" BU_SG_REL_ UWB_BLE SG_ 410 C_UWB_TRUNK_Status8 0;
BA_REL_ "GenSigTimeoutTime" BU_SG_REL_ UWB_BLE SG_ 410 C_UWB_TRNK_DTC 0;
BA_REL_ "GenSigTimeoutTime" BU_SG_REL_ BDC SG_ 410 C_UWB_TRUNK_Option 0;
BA_REL_ "GenSigTimeoutTime" BU_SG_REL_ UWB_BLE SG_ 410 C_UWB_TRUNK_Option 0;
BA_REL_ "GenSigTimeoutTime" BU_SG_REL_ UWB_BLE SG_ 411 C_UWB_TRNK_HW_Ver_Major 0;
BA_REL_ "GenSigTimeoutTime" BU_SG_REL_ UWB_BLE SG_ 411 C_UWB_TRNK_HW_Ver_Minor 0;
BA_REL_ "GenSigTimeoutTime" BU_SG_REL_ UWB_BLE SG_ 411 C_UWB_TRNK_SW_MCU_Ver_Major 0;
BA_REL_ "GenSigTimeoutTime" BU_SG_REL_ UWB_BLE SG_ 411 C_UWB_TRNK_SW_MCU_Ver_Minor 0;
BA_REL_ "GenSigTimeoutTime" BU_SG_REL_ UWB_BLE SG_ 411 C_UWB_TRNK_SW_IC_Ver_Major 0;
BA_REL_ "GenSigTimeoutTime" BU_SG_REL_ UWB_BLE SG_ 411 C_UWB_TRNK_SW_IC_Ver_Minor 0;
BA_REL_ "GenSigTimeoutTime" BU_SG_REL_ UWB_BLE SG_ 418 C_UWB_INT_To_MasterEncData1 0;
BA_REL_ "GenSigTimeoutTime" BU_SG_REL_ UWB_BLE SG_ 450 C_UWB_RL_To_MasterEncData1 0;
BA_REL_ "GenSigTimeoutTime" BU_SG_REL_ UWB_BLE SG_ 451 C_UWB_RL_To_MasterEncData2 0;
BA_REL_ "GenSigTimeoutTime" BU_SG_REL_ BDC SG_ 452 C_UWB_RL_To_BDCFOBRSDResult 0;
BA_REL_ "GenSigTimeoutTime" BU_SG_REL_ UWB_BLE SG_ 453 C_UWB_RL_MCU_Bootloader 0;
BA_REL_ "GenSigTimeoutTime" BU_SG_REL_ UWB_BLE SG_ 453 C_UWB_RL_MCU_Flash_Erase 0;
BA_REL_ "GenSigTimeoutTime" BU_SG_REL_ UWB_BLE SG_ 453 C_UWB_RL_MCU_CRC32 0;
BA_REL_ "GenSigTimeoutTime" BU_SG_REL_ UWB_BLE SG_ 454 C_UWB_RL_IC_Bootloader 0;
BA_REL_ "GenSigTimeoutTime" BU_SG_REL_ UWB_BLE SG_ 454 C_UWB_RL_IC_Flash_Erase 0;
BA_REL_ "GenSigTimeoutTime" BU_SG_REL_ UWB_BLE SG_ 454 C_UWB_RL_IC_CRC32 0;
BA_REL_ "GenSigTimeoutTime" BU_SG_REL_ BDC SG_ 455 C_UWB_RL_Decrypt_FB 0;
BA_REL_ "GenSigTimeoutTime" BU_SG_REL_ UWB_BLE SG_ 455 C_UWB_RL_Decrypt_FB 0;
BA_REL_ "GenSigTimeoutTime" BU_SG_REL_ UWB_BLE SG_ 482 C_UWB_RR_To_MasterEncData1 0;
BA_REL_ "GenSigTimeoutTime" BU_SG_REL_ UWB_BLE SG_ 483 C_UWB_RR_To_MasterEncData2 0;
BA_REL_ "GenSigTimeoutTime" BU_SG_REL_ BDC SG_ 484 C_UWB_RR_To_BDCFOBRSDResult 0;
BA_REL_ "GenSigTimeoutTime" BU_SG_REL_ UWB_BLE SG_ 485 C_UWB_RR_MCU_Bootloader 0;
BA_REL_ "GenSigTimeoutTime" BU_SG_REL_ UWB_BLE SG_ 485 C_UWB_RR_MCU_Flash_Erase 0;
BA_REL_ "GenSigTimeoutTime" BU_SG_REL_ UWB_BLE SG_ 485 C_UWB_RR_MCU_CRC32 0;
BA_REL_ "GenSigTimeoutTime" BU_SG_REL_ UWB_BLE SG_ 486 C_UWB_RR_IC_Bootloader 0;
BA_REL_ "GenSigTimeoutTime" BU_SG_REL_ UWB_BLE SG_ 486 C_UWB_RR_IC_Flash_Erase 0;
BA_REL_ "GenSigTimeoutTime" BU_SG_REL_ UWB_BLE SG_ 486 C_UWB_RR_IC_CRC32 0;
BA_REL_ "GenSigTimeoutTime" BU_SG_REL_ BDC SG_ 487 C_UWB_RR_Decrypt_FB 0;
BA_REL_ "GenSigTimeoutTime" BU_SG_REL_ UWB_BLE SG_ 487 C_UWB_RR_Decrypt_FB 0;
BA_REL_ "GenSigTimeoutTime" BU_SG_REL_ UWB_BLE SG_ 498 C_UWB_TRNK_To_MasterEncData1 0;
BA_REL_ "GenSigTimeoutTime" BU_SG_REL_ UWB_BLE SG_ 499 C_UWB_TRNK_To_MasterEncData2 0;
BA_REL_ "GenSigTimeoutTime" BU_SG_REL_ BDC SG_ 500 C_UWB_TRNK_To_BDCFOBRSDResult 0;
BA_REL_ "GenSigTimeoutTime" BU_SG_REL_ UWB_BLE SG_ 501 C_UWB_TRNK_MCU_Bootloader 0;
BA_REL_ "GenSigTimeoutTime" BU_SG_REL_ UWB_BLE SG_ 501 C_UWB_TRNK_MCU_Flash_Erase 0;
BA_REL_ "GenSigTimeoutTime" BU_SG_REL_ UWB_BLE SG_ 501 C_UWB_TRNK_MCU_CRC32 0;
BA_REL_ "GenSigTimeoutTime" BU_SG_REL_ UWB_BLE SG_ 502 C_UWB_TRNK_IC_Bootloader 0;
BA_REL_ "GenSigTimeoutTime" BU_SG_REL_ UWB_BLE SG_ 502 C_UWB_TRNK_IC_Flash_Erase 0;
BA_REL_ "GenSigTimeoutTime" BU_SG_REL_ UWB_BLE SG_ 502 C_UWB_TRNK_IC_CRC32 0;
BA_REL_ "GenSigTimeoutTime" BU_SG_REL_ BDC SG_ 503 C_UWB_TRNK_Decrypt_FB 0;
BA_REL_ "GenSigTimeoutTime" BU_SG_REL_ UWB_BLE SG_ 503 C_UWB_TRNK_Decrypt_FB 0;
BA_REL_ "GenSigTimeoutTime" BU_SG_REL_ UWB_BLE SG_ 768 C_BDCBLETpByte0Data 0;
BA_REL_ "GenSigTimeoutTime" BU_SG_REL_ UWB_BLE SG_ 768 C_BDCBLETpByte1Data 0;
BA_REL_ "GenSigTimeoutTime" BU_SG_REL_ UWB_BLE SG_ 768 C_BDCBLETpByte2Data 0;
BA_REL_ "GenSigTimeoutTime" BU_SG_REL_ UWB_BLE SG_ 768 C_BDCBLETpByte3Data 0;
BA_REL_ "GenSigTimeoutTime" BU_SG_REL_ UWB_BLE SG_ 768 C_BDCBLETpByte4Data 0;
BA_REL_ "GenSigTimeoutTime" BU_SG_REL_ UWB_BLE SG_ 768 C_BDCBLETpByte5Data 0;
BA_REL_ "GenSigTimeoutTime" BU_SG_REL_ UWB_BLE SG_ 768 C_BDCBLETpByte6Data 0;
BA_REL_ "GenSigTimeoutTime" BU_SG_REL_ UWB_BLE SG_ 768 C_BDCBLETpByte7Data 0;
BA_REL_ "GenSigTimeoutTime" BU_SG_REL_ DHL SG_ 770 C_BDCDHLTpByte0Data 0;
BA_REL_ "GenSigTimeoutTime" BU_SG_REL_ DHL SG_ 770 C_BDCDHLTpByte1Data 0;
BA_REL_ "GenSigTimeoutTime" BU_SG_REL_ DHL SG_ 770 C_BDCDHLTpByte2Data 0;
BA_REL_ "GenSigTimeoutTime" BU_SG_REL_ DHL SG_ 770 C_BDCDHLTpByte3Data 0;
BA_REL_ "GenSigTimeoutTime" BU_SG_REL_ DHL SG_ 770 C_BDCDHLTpByte4Data 0;
BA_REL_ "GenSigTimeoutTime" BU_SG_REL_ DHL SG_ 770 C_BDCDHLTpByte5Data 0;
BA_REL_ "GenSigTimeoutTime" BU_SG_REL_ DHL SG_ 770 C_BDCDHLTpByte6Data 0;
BA_REL_ "GenSigTimeoutTime" BU_SG_REL_ DHL SG_ 770 C_BDCDHLTpByte7Data 0;
BA_REL_ "GenSigTimeoutTime" BU_SG_REL_ DHR SG_ 772 C_BDCDHRTpByte0Data 0;
BA_REL_ "GenSigTimeoutTime" BU_SG_REL_ DHR SG_ 772 C_BDCDHRTpByte1Data 0;
BA_REL_ "GenSigTimeoutTime" BU_SG_REL_ DHR SG_ 772 C_BDCDHRTpByte2Data 0;
BA_REL_ "GenSigTimeoutTime" BU_SG_REL_ DHR SG_ 772 C_BDCDHRTpByte3Data 0;
BA_REL_ "GenSigTimeoutTime" BU_SG_REL_ DHR SG_ 772 C_BDCDHRTpByte4Data 0;
BA_REL_ "GenSigTimeoutTime" BU_SG_REL_ DHR SG_ 772 C_BDCDHRTpByte5Data 0;
BA_REL_ "GenSigTimeoutTime" BU_SG_REL_ DHR SG_ 772 C_BDCDHRTpByte6Data 0;
BA_REL_ "GenSigTimeoutTime" BU_SG_REL_ DHR SG_ 772 C_BDCDHRTpByte7Data 0;
BA_REL_ "GenSigTimeoutTime" BU_SG_REL_ WPC SG_ 778 C_BDCWPCTpByte0Data 0;
BA_REL_ "GenSigTimeoutTime" BU_SG_REL_ WPC SG_ 778 C_BDCWPCTpByte1Data 0;
BA_REL_ "GenSigTimeoutTime" BU_SG_REL_ WPC SG_ 778 C_BDCWPCTpByte2Data 0;
BA_REL_ "GenSigTimeoutTime" BU_SG_REL_ WPC SG_ 778 C_BDCWPCTpByte3Data 0;
BA_REL_ "GenSigTimeoutTime" BU_SG_REL_ WPC SG_ 778 C_BDCWPCTpByte4Data 0;
BA_REL_ "GenSigTimeoutTime" BU_SG_REL_ WPC SG_ 778 C_BDCWPCTpByte5Data 0;
BA_REL_ "GenSigTimeoutTime" BU_SG_REL_ WPC SG_ 778 C_BDCWPCTpByte6Data 0;
BA_REL_ "GenSigTimeoutTime" BU_SG_REL_ WPC SG_ 778 C_BDCWPCTpByte7Data 0;
BA_REL_ "GenSigTimeoutTime" BU_SG_REL_ BDC SG_ 780 C_BLEBDCTpByte0Data 0;
BA_REL_ "GenSigTimeoutTime" BU_SG_REL_ BDC SG_ 780 C_BLEBDCTpByte1Data 0;
BA_REL_ "GenSigTimeoutTime" BU_SG_REL_ BDC SG_ 780 C_BLEBDCTpByte2Data 0;
BA_REL_ "GenSigTimeoutTime" BU_SG_REL_ BDC SG_ 780 C_BLEBDCTpByte3Data 0;
BA_REL_ "GenSigTimeoutTime" BU_SG_REL_ BDC SG_ 780 C_BLEBDCTpByte4Data 0;
BA_REL_ "GenSigTimeoutTime" BU_SG_REL_ BDC SG_ 780 C_BLEBDCTpByte5Data 0;
BA_REL_ "GenSigTimeoutTime" BU_SG_REL_ BDC SG_ 780 C_BLEBDCTpByte6Data 0;
BA_REL_ "GenSigTimeoutTime" BU_SG_REL_ BDC SG_ 780 C_BLEBDCTpByte7Data 0;
BA_REL_ "GenSigTimeoutTime" BU_SG_REL_ BDC SG_ 784 C_DHLBDCTpByte0Data 0;
BA_REL_ "GenSigTimeoutTime" BU_SG_REL_ BDC SG_ 784 C_DHLBDCTpByte1Data 0;
BA_REL_ "GenSigTimeoutTime" BU_SG_REL_ BDC SG_ 784 C_DHLBDCTpByte2Data 0;
BA_REL_ "GenSigTimeoutTime" BU_SG_REL_ BDC SG_ 784 C_DHLBDCTpByte3Data 0;
BA_REL_ "GenSigTimeoutTime" BU_SG_REL_ BDC SG_ 784 C_DHLBDCTpByte4Data 0;
BA_REL_ "GenSigTimeoutTime" BU_SG_REL_ BDC SG_ 784 C_DHLBDCTpByte5Data 0;
BA_REL_ "GenSigTimeoutTime" BU_SG_REL_ BDC SG_ 784 C_DHLBDCTpByte6Data 0;
BA_REL_ "GenSigTimeoutTime" BU_SG_REL_ BDC SG_ 784 C_DHLBDCTpByte7Data 0;
BA_REL_ "GenSigTimeoutTime" BU_SG_REL_ BDC SG_ 786 C_DHRBDCTpByte0Data 0;
BA_REL_ "GenSigTimeoutTime" BU_SG_REL_ BDC SG_ 786 C_DHRBDCTpByte1Data 0;
BA_REL_ "GenSigTimeoutTime" BU_SG_REL_ BDC SG_ 786 C_DHRBDCTpByte2Data 0;
BA_REL_ "GenSigTimeoutTime" BU_SG_REL_ BDC SG_ 786 C_DHRBDCTpByte3Data 0;
BA_REL_ "GenSigTimeoutTime" BU_SG_REL_ BDC SG_ 786 C_DHRBDCTpByte4Data 0;
BA_REL_ "GenSigTimeoutTime" BU_SG_REL_ BDC SG_ 786 C_DHRBDCTpByte5Data 0;
BA_REL_ "GenSigTimeoutTime" BU_SG_REL_ BDC SG_ 786 C_DHRBDCTpByte6Data 0;
BA_REL_ "GenSigTimeoutTime" BU_SG_REL_ BDC SG_ 786 C_DHRBDCTpByte7Data 0;
BA_REL_ "GenSigTimeoutTime" BU_SG_REL_ BDC SG_ 792 C_WPCBDCTpByte0Data 0;
BA_REL_ "GenSigTimeoutTime" BU_SG_REL_ Devtool SG_ 792 C_WPCBDCTpByte0Data 0;
BA_REL_ "GenSigTimeoutTime" BU_SG_REL_ BDC SG_ 792 C_WPCBDCTpByte1Data 0;
BA_REL_ "GenSigTimeoutTime" BU_SG_REL_ Devtool SG_ 792 C_WPCBDCTpByte1Data 0;
BA_REL_ "GenSigTimeoutTime" BU_SG_REL_ BDC SG_ 792 C_WPCBDCTpByte2Data 0;
BA_REL_ "GenSigTimeoutTime" BU_SG_REL_ Devtool SG_ 792 C_WPCBDCTpByte2Data 0;
BA_REL_ "GenSigTimeoutTime" BU_SG_REL_ BDC SG_ 792 C_WPCBDCTpByte3Data 0;
BA_REL_ "GenSigTimeoutTime" BU_SG_REL_ Devtool SG_ 792 C_WPCBDCTpByte3Data 0;
BA_REL_ "GenSigTimeoutTime" BU_SG_REL_ BDC SG_ 792 C_WPCBDCTpByte4Data 0;
BA_REL_ "GenSigTimeoutTime" BU_SG_REL_ Devtool SG_ 792 C_WPCBDCTpByte4Data 0;
BA_REL_ "GenSigTimeoutTime" BU_SG_REL_ BDC SG_ 792 C_WPCBDCTpByte5Data 0;
BA_REL_ "GenSigTimeoutTime" BU_SG_REL_ Devtool SG_ 792 C_WPCBDCTpByte5Data 0;
BA_REL_ "GenSigTimeoutTime" BU_SG_REL_ BDC SG_ 792 C_WPCBDCTpByte6Data 0;
BA_REL_ "GenSigTimeoutTime" BU_SG_REL_ Devtool SG_ 792 C_WPCBDCTpByte6Data 0;
BA_REL_ "GenSigTimeoutTime" BU_SG_REL_ BDC SG_ 792 C_WPCBDCTpByte7Data 0;
BA_REL_ "GenSigTimeoutTime" BU_SG_REL_ Devtool SG_ 792 C_WPCBDCTpByte7Data 0;
BA_REL_ "GenSigTimeoutTime" BU_SG_REL_ UWB_BLE SG_ 800 DevToolBLEDvp1DataByte0 0;
BA_REL_ "GenSigTimeoutTime" BU_SG_REL_ UWB_BLE SG_ 800 DevToolBLEDvp1DataByte1 0;
BA_REL_ "GenSigTimeoutTime" BU_SG_REL_ UWB_BLE SG_ 800 DevToolBLEDvp1DataByte2 0;
BA_REL_ "GenSigTimeoutTime" BU_SG_REL_ UWB_BLE SG_ 800 DevToolBLEDvp1DataByte3 0;
BA_REL_ "GenSigTimeoutTime" BU_SG_REL_ UWB_BLE SG_ 800 DevToolBLEDvp1DataByte4 0;
BA_REL_ "GenSigTimeoutTime" BU_SG_REL_ UWB_BLE SG_ 800 DevToolBLEDvp1DataByte5 0;
BA_REL_ "GenSigTimeoutTime" BU_SG_REL_ UWB_BLE SG_ 800 DevToolBLEDvp1DataByte6 0;
BA_REL_ "GenSigTimeoutTime" BU_SG_REL_ UWB_BLE SG_ 800 DevToolBLEDvp1DataByte7 0;
BA_REL_ "GenSigTimeoutTime" BU_SG_REL_ DHL SG_ 816 DevToolDHDvp1DataByte0 0;
BA_REL_ "GenSigTimeoutTime" BU_SG_REL_ DHR SG_ 816 DevToolDHDvp1DataByte0 0;
BA_REL_ "GenSigTimeoutTime" BU_SG_REL_ DHL SG_ 816 DevToolDHDvp1DataByte1 0;
BA_REL_ "GenSigTimeoutTime" BU_SG_REL_ DHR SG_ 816 DevToolDHDvp1DataByte1 0;
BA_REL_ "GenSigTimeoutTime" BU_SG_REL_ DHL SG_ 816 DevToolDHDvp1DataByte2 0;
BA_REL_ "GenSigTimeoutTime" BU_SG_REL_ DHR SG_ 816 DevToolDHDvp1DataByte2 0;
BA_REL_ "GenSigTimeoutTime" BU_SG_REL_ DHL SG_ 816 DevToolDHDvp1DataByte3 0;
BA_REL_ "GenSigTimeoutTime" BU_SG_REL_ DHR SG_ 816 DevToolDHDvp1DataByte3 0;
BA_REL_ "GenSigTimeoutTime" BU_SG_REL_ DHL SG_ 816 DevToolDHDvp1DataByte4 0;
BA_REL_ "GenSigTimeoutTime" BU_SG_REL_ DHR SG_ 816 DevToolDHDvp1DataByte4 0;
BA_REL_ "GenSigTimeoutTime" BU_SG_REL_ DHL SG_ 816 DevToolDHDvp1DataByte5 0;
BA_REL_ "GenSigTimeoutTime" BU_SG_REL_ DHR SG_ 816 DevToolDHDvp1DataByte5 0;
BA_REL_ "GenSigTimeoutTime" BU_SG_REL_ DHL SG_ 816 DevToolDHDvp1DataByte6 0;
BA_REL_ "GenSigTimeoutTime" BU_SG_REL_ DHR SG_ 816 DevToolDHDvp1DataByte6 0;
BA_REL_ "GenSigTimeoutTime" BU_SG_REL_ DHL SG_ 816 DevToolDHDvp1DataByte7 0;
BA_REL_ "GenSigTimeoutTime" BU_SG_REL_ DHR SG_ 816 DevToolDHDvp1DataByte7 0;
BA_REL_ "GenSigTimeoutTime" BU_SG_REL_ UWB_BLE SG_ 832 DevToolUWBDvp1DataByte0 0;
BA_REL_ "GenSigTimeoutTime" BU_SG_REL_ UWB_FL SG_ 832 DevToolUWBDvp1DataByte0 0;
BA_REL_ "GenSigTimeoutTime" BU_SG_REL_ UWB_FR SG_ 832 DevToolUWBDvp1DataByte0 0;
BA_REL_ "GenSigTimeoutTime" BU_SG_REL_ UWB_FRNK SG_ 832 DevToolUWBDvp1DataByte0 0;
BA_REL_ "GenSigTimeoutTime" BU_SG_REL_ UWB_INT SG_ 832 DevToolUWBDvp1DataByte0 0;
BA_REL_ "GenSigTimeoutTime" BU_SG_REL_ UWB_RL SG_ 832 DevToolUWBDvp1DataByte0 0;
BA_REL_ "GenSigTimeoutTime" BU_SG_REL_ UWB_RR SG_ 832 DevToolUWBDvp1DataByte0 0;
BA_REL_ "GenSigTimeoutTime" BU_SG_REL_ UWB_TRNK SG_ 832 DevToolUWBDvp1DataByte0 0;
BA_REL_ "GenSigTimeoutTime" BU_SG_REL_ UWB_BLE SG_ 832 DevToolUWBDvp1DataByte1 0;
BA_REL_ "GenSigTimeoutTime" BU_SG_REL_ UWB_FL SG_ 832 DevToolUWBDvp1DataByte1 0;
BA_REL_ "GenSigTimeoutTime" BU_SG_REL_ UWB_FR SG_ 832 DevToolUWBDvp1DataByte1 0;
BA_REL_ "GenSigTimeoutTime" BU_SG_REL_ UWB_FRNK SG_ 832 DevToolUWBDvp1DataByte1 0;
BA_REL_ "GenSigTimeoutTime" BU_SG_REL_ UWB_INT SG_ 832 DevToolUWBDvp1DataByte1 0;
BA_REL_ "GenSigTimeoutTime" BU_SG_REL_ UWB_RL SG_ 832 DevToolUWBDvp1DataByte1 0;
BA_REL_ "GenSigTimeoutTime" BU_SG_REL_ UWB_RR SG_ 832 DevToolUWBDvp1DataByte1 0;
BA_REL_ "GenSigTimeoutTime" BU_SG_REL_ UWB_TRNK SG_ 832 DevToolUWBDvp1DataByte1 0;
BA_REL_ "GenSigTimeoutTime" BU_SG_REL_ UWB_BLE SG_ 832 DevToolUWBDvp1DataByte2 0;
BA_REL_ "GenSigTimeoutTime" BU_SG_REL_ UWB_FL SG_ 832 DevToolUWBDvp1DataByte2 0;
BA_REL_ "GenSigTimeoutTime" BU_SG_REL_ UWB_FR SG_ 832 DevToolUWBDvp1DataByte2 0;
BA_REL_ "GenSigTimeoutTime" BU_SG_REL_ UWB_FRNK SG_ 832 DevToolUWBDvp1DataByte2 0;
BA_REL_ "GenSigTimeoutTime" BU_SG_REL_ UWB_INT SG_ 832 DevToolUWBDvp1DataByte2 0;
BA_REL_ "GenSigTimeoutTime" BU_SG_REL_ UWB_RL SG_ 832 DevToolUWBDvp1DataByte2 0;
BA_REL_ "GenSigTimeoutTime" BU_SG_REL_ UWB_RR SG_ 832 DevToolUWBDvp1DataByte2 0;
BA_REL_ "GenSigTimeoutTime" BU_SG_REL_ UWB_TRNK SG_ 832 DevToolUWBDvp1DataByte2 0;
BA_REL_ "GenSigTimeoutTime" BU_SG_REL_ UWB_BLE SG_ 832 DevToolUWBDvp1DataByte3 0;
BA_REL_ "GenSigTimeoutTime" BU_SG_REL_ UWB_FL SG_ 832 DevToolUWBDvp1DataByte3 0;
BA_REL_ "GenSigTimeoutTime" BU_SG_REL_ UWB_FR SG_ 832 DevToolUWBDvp1DataByte3 0;
BA_REL_ "GenSigTimeoutTime" BU_SG_REL_ UWB_FRNK SG_ 832 DevToolUWBDvp1DataByte3 0;
BA_REL_ "GenSigTimeoutTime" BU_SG_REL_ UWB_INT SG_ 832 DevToolUWBDvp1DataByte3 0;
BA_REL_ "GenSigTimeoutTime" BU_SG_REL_ UWB_RL SG_ 832 DevToolUWBDvp1DataByte3 0;
BA_REL_ "GenSigTimeoutTime" BU_SG_REL_ UWB_RR SG_ 832 DevToolUWBDvp1DataByte3 0;
BA_REL_ "GenSigTimeoutTime" BU_SG_REL_ UWB_TRNK SG_ 832 DevToolUWBDvp1DataByte3 0;
BA_REL_ "GenSigTimeoutTime" BU_SG_REL_ UWB_BLE SG_ 832 DevToolUWBDvp1DataByte4 0;
BA_REL_ "GenSigTimeoutTime" BU_SG_REL_ UWB_FL SG_ 832 DevToolUWBDvp1DataByte4 0;
BA_REL_ "GenSigTimeoutTime" BU_SG_REL_ UWB_FR SG_ 832 DevToolUWBDvp1DataByte4 0;
BA_REL_ "GenSigTimeoutTime" BU_SG_REL_ UWB_FRNK SG_ 832 DevToolUWBDvp1DataByte4 0;
BA_REL_ "GenSigTimeoutTime" BU_SG_REL_ UWB_INT SG_ 832 DevToolUWBDvp1DataByte4 0;
BA_REL_ "GenSigTimeoutTime" BU_SG_REL_ UWB_RL SG_ 832 DevToolUWBDvp1DataByte4 0;
BA_REL_ "GenSigTimeoutTime" BU_SG_REL_ UWB_RR SG_ 832 DevToolUWBDvp1DataByte4 0;
BA_REL_ "GenSigTimeoutTime" BU_SG_REL_ UWB_TRNK SG_ 832 DevToolUWBDvp1DataByte4 0;
BA_REL_ "GenSigTimeoutTime" BU_SG_REL_ UWB_BLE SG_ 832 DevToolUWBDvp1DataByte5 0;
BA_REL_ "GenSigTimeoutTime" BU_SG_REL_ UWB_FL SG_ 832 DevToolUWBDvp1DataByte5 0;
BA_REL_ "GenSigTimeoutTime" BU_SG_REL_ UWB_FR SG_ 832 DevToolUWBDvp1DataByte5 0;
BA_REL_ "GenSigTimeoutTime" BU_SG_REL_ UWB_FRNK SG_ 832 DevToolUWBDvp1DataByte5 0;
BA_REL_ "GenSigTimeoutTime" BU_SG_REL_ UWB_INT SG_ 832 DevToolUWBDvp1DataByte5 0;
BA_REL_ "GenSigTimeoutTime" BU_SG_REL_ UWB_RL SG_ 832 DevToolUWBDvp1DataByte5 0;
BA_REL_ "GenSigTimeoutTime" BU_SG_REL_ UWB_RR SG_ 832 DevToolUWBDvp1DataByte5 0;
BA_REL_ "GenSigTimeoutTime" BU_SG_REL_ UWB_TRNK SG_ 832 DevToolUWBDvp1DataByte5 0;
BA_REL_ "GenSigTimeoutTime" BU_SG_REL_ UWB_BLE SG_ 832 DevToolUWBDvp1DataByte6 0;
BA_REL_ "GenSigTimeoutTime" BU_SG_REL_ UWB_FL SG_ 832 DevToolUWBDvp1DataByte6 0;
BA_REL_ "GenSigTimeoutTime" BU_SG_REL_ UWB_FR SG_ 832 DevToolUWBDvp1DataByte6 0;
BA_REL_ "GenSigTimeoutTime" BU_SG_REL_ UWB_FRNK SG_ 832 DevToolUWBDvp1DataByte6 0;
BA_REL_ "GenSigTimeoutTime" BU_SG_REL_ UWB_INT SG_ 832 DevToolUWBDvp1DataByte6 0;
BA_REL_ "GenSigTimeoutTime" BU_SG_REL_ UWB_RL SG_ 832 DevToolUWBDvp1DataByte6 0;
BA_REL_ "GenSigTimeoutTime" BU_SG_REL_ UWB_RR SG_ 832 DevToolUWBDvp1DataByte6 0;
BA_REL_ "GenSigTimeoutTime" BU_SG_REL_ UWB_TRNK SG_ 832 DevToolUWBDvp1DataByte6 0;
BA_REL_ "GenSigTimeoutTime" BU_SG_REL_ UWB_BLE SG_ 832 DevToolUWBDvp1DataByte7 0;
BA_REL_ "GenSigTimeoutTime" BU_SG_REL_ UWB_FL SG_ 832 DevToolUWBDvp1DataByte7 0;
BA_REL_ "GenSigTimeoutTime" BU_SG_REL_ UWB_FR SG_ 832 DevToolUWBDvp1DataByte7 0;
BA_REL_ "GenSigTimeoutTime" BU_SG_REL_ UWB_FRNK SG_ 832 DevToolUWBDvp1DataByte7 0;
BA_REL_ "GenSigTimeoutTime" BU_SG_REL_ UWB_INT SG_ 832 DevToolUWBDvp1DataByte7 0;
BA_REL_ "GenSigTimeoutTime" BU_SG_REL_ UWB_RL SG_ 832 DevToolUWBDvp1DataByte7 0;
BA_REL_ "GenSigTimeoutTime" BU_SG_REL_ UWB_RR SG_ 832 DevToolUWBDvp1DataByte7 0;
BA_REL_ "GenSigTimeoutTime" BU_SG_REL_ UWB_TRNK SG_ 832 DevToolUWBDvp1DataByte7 0;
BA_REL_ "GenSigTimeoutTime" BU_SG_REL_ Devtool SG_ 864 DHLDvp1DataByte0 0;
BA_REL_ "GenSigTimeoutTime" BU_SG_REL_ Devtool SG_ 864 DHLDvp1DataByte1 0;
BA_REL_ "GenSigTimeoutTime" BU_SG_REL_ Devtool SG_ 864 DHLDvp1DataByte2 0;
BA_REL_ "GenSigTimeoutTime" BU_SG_REL_ Devtool SG_ 864 DHLDvp1DataByte3 0;
BA_REL_ "GenSigTimeoutTime" BU_SG_REL_ Devtool SG_ 864 DHLDvp1DataByte4 0;
BA_REL_ "GenSigTimeoutTime" BU_SG_REL_ Devtool SG_ 864 DHLDvp1DataByte5 0;
BA_REL_ "GenSigTimeoutTime" BU_SG_REL_ Devtool SG_ 864 DHLDvp1DataByte6 0;
BA_REL_ "GenSigTimeoutTime" BU_SG_REL_ Devtool SG_ 864 DHLDvp1DataByte7 0;
BA_REL_ "GenSigTimeoutTime" BU_SG_REL_ Devtool SG_ 865 DHRDvp1DataByte0 0;
BA_REL_ "GenSigTimeoutTime" BU_SG_REL_ Devtool SG_ 865 DHRDvp1DataByte1 0;
BA_REL_ "GenSigTimeoutTime" BU_SG_REL_ Devtool SG_ 865 DHRDvp1DataByte2 0;
BA_REL_ "GenSigTimeoutTime" BU_SG_REL_ Devtool SG_ 865 DHRDvp1DataByte3 0;
BA_REL_ "GenSigTimeoutTime" BU_SG_REL_ Devtool SG_ 865 DHRDvp1DataByte4 0;
BA_REL_ "GenSigTimeoutTime" BU_SG_REL_ Devtool SG_ 865 DHRDvp1DataByte5 0;
BA_REL_ "GenSigTimeoutTime" BU_SG_REL_ Devtool SG_ 865 DHRDvp1DataByte6 0;
BA_REL_ "GenSigTimeoutTime" BU_SG_REL_ Devtool SG_ 865 DHRDvp1DataByte7 0;
BA_REL_ "GenSigTimeoutTime" BU_SG_REL_ Devtool SG_ 870 UWBFRDvp1DataByte0 0;
BA_REL_ "GenSigTimeoutTime" BU_SG_REL_ Devtool SG_ 870 UWBFRDvp1DataByte1 0;
BA_REL_ "GenSigTimeoutTime" BU_SG_REL_ Devtool SG_ 870 UWBFRDvp1DataByte2 0;
BA_REL_ "GenSigTimeoutTime" BU_SG_REL_ Devtool SG_ 870 UWBFRDvp1DataByte3 0;
BA_REL_ "GenSigTimeoutTime" BU_SG_REL_ Devtool SG_ 870 UWBFRDvp1DataByte4 0;
BA_REL_ "GenSigTimeoutTime" BU_SG_REL_ Devtool SG_ 870 UWBFRDvp1DataByte5 0;
BA_REL_ "GenSigTimeoutTime" BU_SG_REL_ Devtool SG_ 870 UWBFRDvp1DataByte6 0;
BA_REL_ "GenSigTimeoutTime" BU_SG_REL_ Devtool SG_ 870 UWBFRDvp1DataByte7 0;
BA_REL_ "GenSigTimeoutTime" BU_SG_REL_ Devtool SG_ 871 UWBFLDvp1DataByte0 0;
BA_REL_ "GenSigTimeoutTime" BU_SG_REL_ Devtool SG_ 871 UWBFLDvp1DataByte1 0;
BA_REL_ "GenSigTimeoutTime" BU_SG_REL_ Devtool SG_ 871 UWBFLDvp1DataByte2 0;
BA_REL_ "GenSigTimeoutTime" BU_SG_REL_ Devtool SG_ 871 UWBFLDvp1DataByte3 0;
BA_REL_ "GenSigTimeoutTime" BU_SG_REL_ Devtool SG_ 871 UWBFLDvp1DataByte4 0;
BA_REL_ "GenSigTimeoutTime" BU_SG_REL_ Devtool SG_ 871 UWBFLDvp1DataByte5 0;
BA_REL_ "GenSigTimeoutTime" BU_SG_REL_ Devtool SG_ 871 UWBFLDvp1DataByte6 0;
BA_REL_ "GenSigTimeoutTime" BU_SG_REL_ Devtool SG_ 871 UWBFLDvp1DataByte7 0;
BA_REL_ "GenSigTimeoutTime" BU_SG_REL_ Devtool SG_ 872 UWBRRDvp1DataByte0 0;
BA_REL_ "GenSigTimeoutTime" BU_SG_REL_ Devtool SG_ 872 UWBRRDvp1DataByte1 0;
BA_REL_ "GenSigTimeoutTime" BU_SG_REL_ Devtool SG_ 872 UWBRRDvp1DataByte2 0;
BA_REL_ "GenSigTimeoutTime" BU_SG_REL_ Devtool SG_ 872 UWBRRDvp1DataByte3 0;
BA_REL_ "GenSigTimeoutTime" BU_SG_REL_ Devtool SG_ 872 UWBRRDvp1DataByte4 0;
BA_REL_ "GenSigTimeoutTime" BU_SG_REL_ Devtool SG_ 872 UWBRRDvp1DataByte5 0;
BA_REL_ "GenSigTimeoutTime" BU_SG_REL_ Devtool SG_ 872 UWBRRDvp1DataByte6 0;
BA_REL_ "GenSigTimeoutTime" BU_SG_REL_ Devtool SG_ 872 UWBRRDvp1DataByte7 0;
BA_REL_ "GenSigTimeoutTime" BU_SG_REL_ Devtool SG_ 873 UWBRLDvp1DataByte0 0;
BA_REL_ "GenSigTimeoutTime" BU_SG_REL_ Devtool SG_ 873 UWBRLDvp1DataByte1 0;
BA_REL_ "GenSigTimeoutTime" BU_SG_REL_ Devtool SG_ 873 UWBRLDvp1DataByte2 0;
BA_REL_ "GenSigTimeoutTime" BU_SG_REL_ Devtool SG_ 873 UWBRLDvp1DataByte3 0;
BA_REL_ "GenSigTimeoutTime" BU_SG_REL_ Devtool SG_ 873 UWBRLDvp1DataByte4 0;
BA_REL_ "GenSigTimeoutTime" BU_SG_REL_ Devtool SG_ 873 UWBRLDvp1DataByte5 0;
BA_REL_ "GenSigTimeoutTime" BU_SG_REL_ Devtool SG_ 873 UWBRLDvp1DataByte6 0;
BA_REL_ "GenSigTimeoutTime" BU_SG_REL_ Devtool SG_ 873 UWBRLDvp1DataByte7 0;
BA_REL_ "GenSigTimeoutTime" BU_SG_REL_ Devtool SG_ 874 UWBFRNKDvp1DataByte0 0;
BA_REL_ "GenSigTimeoutTime" BU_SG_REL_ Devtool SG_ 874 UWBFRNKDvp1DataByte1 0;
BA_REL_ "GenSigTimeoutTime" BU_SG_REL_ Devtool SG_ 874 UWBFRNKDvp1DataByte2 0;
BA_REL_ "GenSigTimeoutTime" BU_SG_REL_ Devtool SG_ 874 UWBFRNKDvp1DataByte3 0;
BA_REL_ "GenSigTimeoutTime" BU_SG_REL_ Devtool SG_ 874 UWBFRNKDvp1DataByte4 0;
BA_REL_ "GenSigTimeoutTime" BU_SG_REL_ Devtool SG_ 874 UWBFRNKDvp1DataByte5 0;
BA_REL_ "GenSigTimeoutTime" BU_SG_REL_ Devtool SG_ 874 UWBFRNKDvp1DataByte6 0;
BA_REL_ "GenSigTimeoutTime" BU_SG_REL_ Devtool SG_ 874 UWBFRNKDvp1DataByte7 0;
BA_REL_ "GenSigTimeoutTime" BU_SG_REL_ Devtool SG_ 877 UWBTRNKDvp1DataByte0 0;
BA_REL_ "GenSigTimeoutTime" BU_SG_REL_ Devtool SG_ 877 UWBTRNKDvp1DataByte1 0;
BA_REL_ "GenSigTimeoutTime" BU_SG_REL_ Devtool SG_ 877 UWBTRNKDvp1DataByte2 0;
BA_REL_ "GenSigTimeoutTime" BU_SG_REL_ Devtool SG_ 877 UWBTRNKDvp1DataByte3 0;
BA_REL_ "GenSigTimeoutTime" BU_SG_REL_ Devtool SG_ 877 UWBTRNKDvp1DataByte4 0;
BA_REL_ "GenSigTimeoutTime" BU_SG_REL_ Devtool SG_ 877 UWBTRNKDvp1DataByte5 0;
BA_REL_ "GenSigTimeoutTime" BU_SG_REL_ Devtool SG_ 877 UWBTRNKDvp1DataByte6 0;
BA_REL_ "GenSigTimeoutTime" BU_SG_REL_ Devtool SG_ 877 UWBTRNKDvp1DataByte7 0;
BA_REL_ "GenSigTimeoutTime" BU_SG_REL_ Devtool SG_ 884 UWB_BLEDvp1DataByte0 0;
BA_REL_ "GenSigTimeoutTime" BU_SG_REL_ Devtool SG_ 884 UWB_BLEDvp1DataByte1 0;
BA_REL_ "GenSigTimeoutTime" BU_SG_REL_ Devtool SG_ 884 UWB_BLEDvp1DataByte2 0;
BA_REL_ "GenSigTimeoutTime" BU_SG_REL_ Devtool SG_ 884 UWB_BLEDvp1DataByte3 0;
BA_REL_ "GenSigTimeoutTime" BU_SG_REL_ Devtool SG_ 884 UWB_BLEDvp1DataByte4 0;
BA_REL_ "GenSigTimeoutTime" BU_SG_REL_ Devtool SG_ 884 UWB_BLEDvp1DataByte5 0;
BA_REL_ "GenSigTimeoutTime" BU_SG_REL_ Devtool SG_ 884 UWB_BLEDvp1DataByte6 0;
BA_REL_ "GenSigTimeoutTime" BU_SG_REL_ Devtool SG_ 884 UWB_BLEDvp1DataByte7 0;
BA_REL_ "GenSigTimeoutTime" BU_SG_REL_ Devtool SG_ 885 UWBINTDvp1DataByte0 0;
BA_REL_ "GenSigTimeoutTime" BU_SG_REL_ Devtool SG_ 885 UWBINTDvp1DataByte1 0;
BA_REL_ "GenSigTimeoutTime" BU_SG_REL_ Devtool SG_ 885 UWBINTDvp1DataByte2 0;
BA_REL_ "GenSigTimeoutTime" BU_SG_REL_ Devtool SG_ 885 UWBINTDvp1DataByte3 0;
BA_REL_ "GenSigTimeoutTime" BU_SG_REL_ Devtool SG_ 885 UWBINTDvp1DataByte4 0;
BA_REL_ "GenSigTimeoutTime" BU_SG_REL_ Devtool SG_ 885 UWBINTDvp1DataByte5 0;
BA_REL_ "GenSigTimeoutTime" BU_SG_REL_ Devtool SG_ 885 UWBINTDvp1DataByte6 0;
BA_REL_ "GenSigTimeoutTime" BU_SG_REL_ Devtool SG_ 885 UWBINTDvp1DataByte7 0;
BA_REL_ "GenSigTimeoutTime" BU_SG_REL_ Devtool SG_ 888 UWB_BLE_Dvp2Data 0;
BA_REL_ "GenSigTimeoutTime" BU_SG_REL_ Devtool SG_ 889 UWB_BLE_Dvp3Data 0;
BA_REL_ "GenSigTimeoutTime" BU_SG_REL_ Devtool SG_ 896 UWB_BLE_Dvp4Data 0;
BA_REL_ "GenSigTimeoutTime" BU_SG_REL_ UWB_BLE SG_ 1410 GstBDCUWB_BLEDataByte0 0;
BA_REL_ "GenSigTimeoutTime" BU_SG_REL_ UWB_BLE SG_ 1410 GstBDCUWB_BLEDataByte1 0;
BA_REL_ "GenSigTimeoutTime" BU_SG_REL_ UWB_BLE SG_ 1410 GstBDCUWB_BLEDataByte2 0;
BA_REL_ "GenSigTimeoutTime" BU_SG_REL_ UWB_BLE SG_ 1410 GstBDCUWB_BLEDataByte3 0;
BA_REL_ "GenSigTimeoutTime" BU_SG_REL_ UWB_BLE SG_ 1410 GstBDCUWB_BLEDataByte4 0;
BA_REL_ "GenSigTimeoutTime" BU_SG_REL_ UWB_BLE SG_ 1410 GstBDCUWB_BLEDataByte5 0;
BA_REL_ "GenSigTimeoutTime" BU_SG_REL_ UWB_BLE SG_ 1410 GstBDCUWB_BLEDataByte6 0;
BA_REL_ "GenSigTimeoutTime" BU_SG_REL_ UWB_BLE SG_ 1410 GstBDCUWB_BLEDataByte7 0;
BA_REL_ "GenSigTimeoutTime" BU_SG_REL_ BDC SG_ 1418 UWB_BLEBDCGstDataByte0 0;
BA_REL_ "GenSigTimeoutTime" BU_SG_REL_ BDC SG_ 1418 UWB_BLEBDCGstDataByte1 0;
BA_REL_ "GenSigTimeoutTime" BU_SG_REL_ BDC SG_ 1418 UWB_BLEBDCGstDataByte2 0;
BA_REL_ "GenSigTimeoutTime" BU_SG_REL_ BDC SG_ 1418 UWB_BLEBDCGstDataByte3 0;
BA_REL_ "GenSigTimeoutTime" BU_SG_REL_ BDC SG_ 1418 UWB_BLEBDCGstDataByte4 0;
BA_REL_ "GenSigTimeoutTime" BU_SG_REL_ BDC SG_ 1418 UWB_BLEBDCGstDataByte5 0;
BA_REL_ "GenSigTimeoutTime" BU_SG_REL_ BDC SG_ 1418 UWB_BLEBDCGstDataByte6 0;
BA_REL_ "GenSigTimeoutTime" BU_SG_REL_ BDC SG_ 1418 UWB_BLEBDCGstDataByte7 0;
BA_REL_ "GenSigTimeoutTime" BU_SG_REL_ ROA SG_ 1504 GstBDCROADataByte0 0;
BA_REL_ "GenSigTimeoutTime" BU_SG_REL_ ROA SG_ 1504 GstBDCROADataByte1 0;
BA_REL_ "GenSigTimeoutTime" BU_SG_REL_ ROA SG_ 1504 GstBDCROADataByte2 0;
BA_REL_ "GenSigTimeoutTime" BU_SG_REL_ ROA SG_ 1504 GstBDCROADataByte3 0;
BA_REL_ "GenSigTimeoutTime" BU_SG_REL_ ROA SG_ 1504 GstBDCROADataByte4 0;
BA_REL_ "GenSigTimeoutTime" BU_SG_REL_ ROA SG_ 1504 GstBDCROADataByte5 0;
BA_REL_ "GenSigTimeoutTime" BU_SG_REL_ ROA SG_ 1504 GstBDCROADataByte6 0;
BA_REL_ "GenSigTimeoutTime" BU_SG_REL_ ROA SG_ 1504 GstBDCROADataByte7 0;
BA_REL_ "GenSigTimeoutTime" BU_SG_REL_ BDC SG_ 1512 ROABDCGstDataByte0 0;
BA_REL_ "GenSigTimeoutTime" BU_SG_REL_ BDC SG_ 1512 ROABDCGstDataByte1 0;
BA_REL_ "GenSigTimeoutTime" BU_SG_REL_ BDC SG_ 1512 ROABDCGstDataByte2 0;
BA_REL_ "GenSigTimeoutTime" BU_SG_REL_ BDC SG_ 1512 ROABDCGstDataByte3 0;
BA_REL_ "GenSigTimeoutTime" BU_SG_REL_ BDC SG_ 1512 ROABDCGstDataByte4 0;
BA_REL_ "GenSigTimeoutTime" BU_SG_REL_ BDC SG_ 1512 ROABDCGstDataByte5 0;
BA_REL_ "GenSigTimeoutTime" BU_SG_REL_ BDC SG_ 1512 ROABDCGstDataByte6 0;
BA_REL_ "GenSigTimeoutTime" BU_SG_REL_ BDC SG_ 1512 ROABDCGstDataByte7 0;
BA_REL_ "GenSigTimeoutTime" BU_SG_REL_ DHL SG_ 1794 GstBDCDHLDataByte0 0;
BA_REL_ "GenSigTimeoutTime" BU_SG_REL_ DHL SG_ 1794 GstBDCDHLDataByte1 0;
BA_REL_ "GenSigTimeoutTime" BU_SG_REL_ DHL SG_ 1794 GstBDCDHLDataByte2 0;
BA_REL_ "GenSigTimeoutTime" BU_SG_REL_ DHL SG_ 1794 GstBDCDHLDataByte3 0;
BA_REL_ "GenSigTimeoutTime" BU_SG_REL_ DHL SG_ 1794 GstBDCDHLDataByte4 0;
BA_REL_ "GenSigTimeoutTime" BU_SG_REL_ DHL SG_ 1794 GstBDCDHLDataByte5 0;
BA_REL_ "GenSigTimeoutTime" BU_SG_REL_ DHL SG_ 1794 GstBDCDHLDataByte6 0;
BA_REL_ "GenSigTimeoutTime" BU_SG_REL_ DHL SG_ 1794 GstBDCDHLDataByte7 0;
BA_REL_ "GenSigTimeoutTime" BU_SG_REL_ BDC SG_ 1802 DHLBDCGstDataByte0 0;
BA_REL_ "GenSigTimeoutTime" BU_SG_REL_ BDC SG_ 1802 DHLBDCGstDataByte1 0;
BA_REL_ "GenSigTimeoutTime" BU_SG_REL_ BDC SG_ 1802 DHLBDCGstDataByte2 0;
BA_REL_ "GenSigTimeoutTime" BU_SG_REL_ BDC SG_ 1802 DHLBDCGstDataByte3 0;
BA_REL_ "GenSigTimeoutTime" BU_SG_REL_ BDC SG_ 1802 DHLBDCGstDataByte4 0;
BA_REL_ "GenSigTimeoutTime" BU_SG_REL_ BDC SG_ 1802 DHLBDCGstDataByte5 0;
BA_REL_ "GenSigTimeoutTime" BU_SG_REL_ BDC SG_ 1802 DHLBDCGstDataByte6 0;
BA_REL_ "GenSigTimeoutTime" BU_SG_REL_ BDC SG_ 1802 DHLBDCGstDataByte7 0;
BA_REL_ "GenSigTimeoutTime" BU_SG_REL_ DHR SG_ 1813 GstBDCDHRDataByte0 0;
BA_REL_ "GenSigTimeoutTime" BU_SG_REL_ DHR SG_ 1813 GstBDCDHRDataByte1 0;
BA_REL_ "GenSigTimeoutTime" BU_SG_REL_ DHR SG_ 1813 GstBDCDHRDataByte2 0;
BA_REL_ "GenSigTimeoutTime" BU_SG_REL_ DHR SG_ 1813 GstBDCDHRDataByte3 0;
BA_REL_ "GenSigTimeoutTime" BU_SG_REL_ DHR SG_ 1813 GstBDCDHRDataByte4 0;
BA_REL_ "GenSigTimeoutTime" BU_SG_REL_ DHR SG_ 1813 GstBDCDHRDataByte5 0;
BA_REL_ "GenSigTimeoutTime" BU_SG_REL_ DHR SG_ 1813 GstBDCDHRDataByte6 0;
BA_REL_ "GenSigTimeoutTime" BU_SG_REL_ DHR SG_ 1813 GstBDCDHRDataByte7 0;
BA_REL_ "GenSigTimeoutTime" BU_SG_REL_ BDC SG_ 1821 DHRBDCGstDataByte0 0;
BA_REL_ "GenSigTimeoutTime" BU_SG_REL_ BDC SG_ 1821 DHRBDCGstDataByte1 0;
BA_REL_ "GenSigTimeoutTime" BU_SG_REL_ BDC SG_ 1821 DHRBDCGstDataByte2 0;
BA_REL_ "GenSigTimeoutTime" BU_SG_REL_ BDC SG_ 1821 DHRBDCGstDataByte3 0;
BA_REL_ "GenSigTimeoutTime" BU_SG_REL_ BDC SG_ 1821 DHRBDCGstDataByte4 0;
BA_REL_ "GenSigTimeoutTime" BU_SG_REL_ BDC SG_ 1821 DHRBDCGstDataByte5 0;
BA_REL_ "GenSigTimeoutTime" BU_SG_REL_ BDC SG_ 1821 DHRBDCGstDataByte6 0;
BA_REL_ "GenSigTimeoutTime" BU_SG_REL_ BDC SG_ 1821 DHRBDCGstDataByte7 0;
BA_REL_ "GenSigTimeoutTime" BU_SG_REL_ DHL SG_ 2015 FrmFormat 0;
BA_REL_ "GenSigTimeoutTime" BU_SG_REL_ DHR SG_ 2015 FrmFormat 0;
BA_REL_ "GenSigTimeoutTime" BU_SG_REL_ ROA SG_ 2015 FrmFormat 0;
BA_REL_ "GenSigTimeoutTime" BU_SG_REL_ UWB_BLE SG_ 2015 FrmFormat 0;
BA_REL_ "GenSigTimeoutTime" BU_SG_REL_ WPC SG_ 2015 FrmFormat 0;
BA_REL_ "GenSigTimeoutTime" BU_SG_REL_ DHL SG_ 2015 SID 0;
BA_REL_ "GenSigTimeoutTime" BU_SG_REL_ DHR SG_ 2015 SID 0;
BA_REL_ "GenSigTimeoutTime" BU_SG_REL_ ROA SG_ 2015 SID 0;
BA_REL_ "GenSigTimeoutTime" BU_SG_REL_ UWB_BLE SG_ 2015 SID 0;
BA_REL_ "GenSigTimeoutTime" BU_SG_REL_ WPC SG_ 2015 SID 0;
BA_REL_ "GenSigTimeoutTime" BU_SG_REL_ DHL SG_ 2015 REQ_RESPONSE 0;
BA_REL_ "GenSigTimeoutTime" BU_SG_REL_ DHR SG_ 2015 REQ_RESPONSE 0;
BA_REL_ "GenSigTimeoutTime" BU_SG_REL_ ROA SG_ 2015 REQ_RESPONSE 0;
BA_REL_ "GenSigTimeoutTime" BU_SG_REL_ UWB_BLE SG_ 2015 REQ_RESPONSE 0;
BA_REL_ "GenSigTimeoutTime" BU_SG_REL_ WPC SG_ 2015 REQ_RESPONSE 0;
BA_REL_ "GenSigTimeoutTime" BU_SG_REL_ DHL SG_ 2015 GstALLByte3Data 0;
BA_REL_ "GenSigTimeoutTime" BU_SG_REL_ DHR SG_ 2015 GstALLByte3Data 0;
BA_REL_ "GenSigTimeoutTime" BU_SG_REL_ ROA SG_ 2015 GstALLByte3Data 0;
BA_REL_ "GenSigTimeoutTime" BU_SG_REL_ UWB_BLE SG_ 2015 GstALLByte3Data 0;
BA_REL_ "GenSigTimeoutTime" BU_SG_REL_ WPC SG_ 2015 GstALLByte3Data 0;
BA_REL_ "GenSigTimeoutTime" BU_SG_REL_ DHL SG_ 2015 GstALLByte4Data 0;
BA_REL_ "GenSigTimeoutTime" BU_SG_REL_ DHR SG_ 2015 GstALLByte4Data 0;
BA_REL_ "GenSigTimeoutTime" BU_SG_REL_ ROA SG_ 2015 GstALLByte4Data 0;
BA_REL_ "GenSigTimeoutTime" BU_SG_REL_ UWB_BLE SG_ 2015 GstALLByte4Data 0;
BA_REL_ "GenSigTimeoutTime" BU_SG_REL_ WPC SG_ 2015 GstALLByte4Data 0;
BA_REL_ "GenSigTimeoutTime" BU_SG_REL_ DHL SG_ 2015 GstALLByte5Data 0;
BA_REL_ "GenSigTimeoutTime" BU_SG_REL_ DHR SG_ 2015 GstALLByte5Data 0;
BA_REL_ "GenSigTimeoutTime" BU_SG_REL_ ROA SG_ 2015 GstALLByte5Data 0;
BA_REL_ "GenSigTimeoutTime" BU_SG_REL_ UWB_BLE SG_ 2015 GstALLByte5Data 0;
BA_REL_ "GenSigTimeoutTime" BU_SG_REL_ WPC SG_ 2015 GstALLByte5Data 0;
BA_REL_ "GenSigTimeoutTime" BU_SG_REL_ DHL SG_ 2015 GstALLByte6Data 0;
BA_REL_ "GenSigTimeoutTime" BU_SG_REL_ DHR SG_ 2015 GstALLByte6Data 0;
BA_REL_ "GenSigTimeoutTime" BU_SG_REL_ ROA SG_ 2015 GstALLByte6Data 0;
BA_REL_ "GenSigTimeoutTime" BU_SG_REL_ UWB_BLE SG_ 2015 GstALLByte6Data 0;
BA_REL_ "GenSigTimeoutTime" BU_SG_REL_ WPC SG_ 2015 GstALLByte6Data 0;
BA_REL_ "GenSigTimeoutTime" BU_SG_REL_ DHL SG_ 2015 GstALLByte7Data 0;
BA_REL_ "GenSigTimeoutTime" BU_SG_REL_ DHR SG_ 2015 GstALLByte7Data 0;
BA_REL_ "GenSigTimeoutTime" BU_SG_REL_ ROA SG_ 2015 GstALLByte7Data 0;
BA_REL_ "GenSigTimeoutTime" BU_SG_REL_ UWB_BLE SG_ 2015 GstALLByte7Data 0;
BA_REL_ "GenSigTimeoutTime" BU_SG_REL_ WPC SG_ 2015 GstALLByte7Data 0;
VAL_ 392 C_UWB_MASTER_Option 0 "Default(NotApplied)" 1 "Applied" 2 "Reseved" 3 "invalid" ;
VAL_ 393 C_UWB_Master_DK_ConnStat 0 "Default" 1 "Connected" 2 "Not Connected" 3 "Invalid" ;
VAL_ 393 C_UWB_Mst_DK_LocalizationStat 0 "Default" 1 "Localizing" 2 "Suspended" 3 "Invalid" ;
VAL_ 400 C_UWB_RL_DTC 0 "Default(Virgin)" 1 "Learned" 2 "Neutralized" 3 "invalid" ;
VAL_ 400 C_UWB_RL_Option 0 "Default(NotApplied)" 1 "Applied" 2 "Reserved" 3 "invalid" ;
VAL_ 405 C_UWB_RR_DTC 0 "Default(Virgin)" 1 "Learned" 2 "Neutralized" 3 "invalid" ;
VAL_ 405 C_UWB_RR_Option 0 "Default(NotApplied)" 1 "Applied" 2 "Reseved" 3 "invalid" ;
VAL_ 410 C_UWB_TRNK_DTC 0 "Default(Virgin)" 1 "Learned" 2 "Neutralized" 3 "invalid" ;
VAL_ 410 C_UWB_TRUNK_Option 0 "Default(NotApplied)" 1 "Applied" 2 "Reseved" 3 "invalid" ;
VAL_ 453 C_UWB_RL_MCU_Bootloader 0 "Default" 1 "Success" 2 "Fail" 3 "0x3~0xFF:Invalid" 255 "0x3~0xFF:Invalid" ;
VAL_ 453 C_UWB_RL_MCU_Flash_Erase 0 "Default" 1 "Success" 2 "Fail" 3 "0x3~0xFF:Invalid" 255 "0x3~0xFF:Invalid" ;
VAL_ 453 C_UWB_RL_MCU_CRC32 0 "Default" 1 "Success" 2 "Fail" 3 "0x3~0xFF:Invalid" 255 "0x3~0xFF:Invalid" ;
VAL_ 454 C_UWB_RL_IC_Bootloader 0 "Default" 1 "Success" 2 "Fail" 3 "0x3~0xFF:Invalid" 255 "0x3~0xFF:Invalid" ;
VAL_ 454 C_UWB_RL_IC_Flash_Erase 0 "Default" 1 "Success" 2 "Fail" 3 "0x3~0xFF:Invalid" 255 "0x3~0xFF:Invalid" ;
VAL_ 454 C_UWB_RL_IC_CRC32 0 "Default" 1 "Success" 2 "Fail" 3 "0x3~0xFF:Invalid" 255 "0x3~0xFF:Invalid" ;
VAL_ 455 C_UWB_RL_Decrypt_FB 0 "Default" 1 "Positive" 2 "Negative" 3 "Reserved" 4 "Reserved" 5 "Reserved" 6 "Reserved" 7 "Reserved" 8 "Reserved" 9 "Reserved" 10 "Reserved" 11 "Reserved" 12 "Reserved" 13 "Reserved" 14 "Reserved" 15 "Reserved" ;
VAL_ 485 C_UWB_RR_MCU_Bootloader 0 "Default" 1 "Success" 2 "Fail" 3 "0x3~0xFF:Invalid" 255 "0x3~0xFF:Invalid" ;
VAL_ 485 C_UWB_RR_MCU_Flash_Erase 0 "Default" 1 "Success" 2 "Fail" 3 "0x3~0xFF:Invalid" 255 "0x3~0xFF:Invalid" ;
VAL_ 485 C_UWB_RR_MCU_CRC32 0 "Default" 1 "Success" 2 "Fail" 3 "0x3~0xFF:Invalid" 255 "0x3~0xFF:Invalid" ;
VAL_ 486 C_UWB_RR_IC_Bootloader 0 "Default" 1 "Success" 2 "Fail" 3 "0x3~0xFF:Invalid" 255 "0x3~0xFF:Invalid" ;
VAL_ 486 C_UWB_RR_IC_Flash_Erase 0 "Default" 1 "Success" 2 "Fail" 3 "0x3~0xFF:Invalid" 255 "0x3~0xFF:Invalid" ;
VAL_ 486 C_UWB_RR_IC_CRC32 0 "Default" 1 "Success" 2 "Fail" 3 "0x3~0xFF:Invalid" 255 "0x3~0xFF:Invalid" ;
VAL_ 487 C_UWB_RR_Decrypt_FB 0 "Default" 1 "Positive" 2 "Negative" 3 "Reserved" 4 "Reserved" 5 "Reserved" 6 "Reserved" 7 "Reserved" 8 "Reserved" 9 "Reserved" 10 "Reserved" 11 "Reserved" 12 "Reserved" 13 "Reserved" 14 "Reserved" 15 "Reserved" ;
VAL_ 501 C_UWB_TRNK_MCU_Bootloader 0 "Default" 1 "Success" 2 "Fail" 3 "0x3~0xFF:Invalid" 255 "0x3~0xFF:Invalid" ;
VAL_ 501 C_UWB_TRNK_MCU_Flash_Erase 0 "Default" 1 "Success" 2 "Fail" 3 "0x3~0xFF:Invalid" 255 "0x3~0xFF:Invalid" ;
VAL_ 501 C_UWB_TRNK_MCU_CRC32 0 "Default" 1 "Success" 2 "Fail" 3 "0x3~0xFF:Invalid" 255 "0x3~0xFF:Invalid" ;
VAL_ 502 C_UWB_TRNK_IC_Bootloader 0 "Default" 1 "Success" 2 "Fail" 3 "0x3~0xFF:Invalid" 255 "0x3~0xFF:Invalid" ;
VAL_ 502 C_UWB_TRNK_IC_Flash_Erase 0 "Default" 1 "Success" 2 "Fail" 3 "0x3~0xFF:Invalid" 255 "0x3~0xFF:Invalid" ;
VAL_ 502 C_UWB_TRNK_IC_CRC32 0 "Default" 1 "Success" 2 "Fail" 3 "0x3~0xFF:Invalid" 255 "0x3~0xFF:Invalid" ;
VAL_ 503 C_UWB_TRNK_Decrypt_FB 0 "Default" 1 "Positive" 2 "Negative" 3 "Reserved" 4 "Reserved" 5 "Reserved" 6 "Reserved" 7 "Reserved" 8 "Reserved" 9 "Reserved" 10 "Reserved" 11 "Reserved" 12 "Reserved" 13 "Reserved" 14 "Reserved" 15 "Reserved" ;
VAL_ 1024 NMSleepFlag_BDC 0 "Alive" 1 "SleepInd" 3 "SleepAck" ;
VAL_ 1024 NMCommandCode_BDC 0 "None" 1 "Alive" 2 "Ring" 4 "Limphome" ;
VAL_ 1054 NMSleepFlag_WPC 0 "Alive" 1 "SleepInd" 3 "SleepAck" ;
VAL_ 1054 NMCommandCode_WPC 0 "None" 1 "Alive" 2 "Ring" 4 "Limphome" ;
VAL_ 1097 NMSleepFlag_ROA 0 "Alive" 1 "SleepInd" 3 "SleepAck" ;
VAL_ 1097 NMCommandCode_ROA 0 "None" 1 "Alive" 2 "Ring" 4 "Limphome" ;
VAL_ 1120 NMSleepFlag_DHL 0 "Alive" 1 "SleepInd" 3 "SleepAck" ;
VAL_ 1120 NMCommandCode_DHL 0 "None" 1 "Alive" 2 "Ring" 4 "Limphome" ;
VAL_ 1121 NMSleepFlag_DHR 0 "Alive" 1 "SleepInd" 3 "SleepAck" ;
VAL_ 1121 NMCommandCode_DHR 0 "None" 1 "Alive" 2 "Ring" 4 "Limphome" ;
VAL_ 1123 NMSleepFlag_Devtool 0 "Alive" 1 "SleepInd" 3 "SleepAck" ;
VAL_ 1123 NMCommandCode_Devtool 0 "None" 1 "Alive" 2 "Ring" 4 "Limphome" ;
VAL_ 1126 NMSleepFlag_UWB_FR 0 "Alive" 1 "SleepInd" 3 "SleepAck" ;
VAL_ 1126 NMCommandCode_UWB_FR 0 "None" 1 "Alive" 2 "Ring" 4 "Limphome" ;
VAL_ 1127 NMSleepFlag_UWB_FL 0 "Alive" 1 "SleepInd" 3 "SleepAck" ;
VAL_ 1127 NMCommandCode_UWB_FL 0 "None" 1 "Alive" 2 "Ring" 4 "Limphome" ;
VAL_ 1128 NMSleepFlag_UWB_RR 0 "Alive" 1 "SleepInd" 3 "SleepAck" ;
VAL_ 1128 NMCommandCode_UWB_RR 0 "None" 1 "Alive" 2 "Ring" 4 "Limphome" ;
VAL_ 1129 NMSleepFlag_UWB_RL 0 "Alive" 1 "SleepInd" 3 "SleepAck" ;
VAL_ 1129 NMCommandCode_UWB_RL 0 "None" 1 "Alive" 2 "Ring" 4 "Limphome" ;
VAL_ 1133 NMSleepFlag_UWB_TRNK 0 "Alive" 1 "SleepInd" 3 "SleepAck" ;
VAL_ 1133 NMCommandCode_UWB_TRNK 0 "None" 1 "Alive" 2 "Ring" 4 "Limphome" ;
VAL_ 1134 NMSleepFlag_UWB_FRNK 0 "Alive" 1 "SleepInd" 3 "SleepAck" ;
VAL_ 1134 NMCommandCode_UWB_FRNK 0 "None" 1 "Alive" 2 "Ring" 4 "Limphome" ;
VAL_ 1140 NMSleepFlag_UWB_BLE 0 "Alive" 1 "SleepInd" 3 "SleepAck" ;
VAL_ 1140 NMCommandCode_UWB_BLE 0 "None" 1 "Alive" 2 "Ring" 4 "Limphome" ;
VAL_ 1141 NMSleepFlag_UWB_INT 0 "Alive" 1 "SleepInd" 3 "SleepAck" ;
VAL_ 1141 NMCommandCode_UWB_INT 0 "None" 1 "Alive" 2 "Ring" 4 "Limphome" ;
